VERSION ""

NS_ :

BS_:

BU_: ACM APIM APIM_CDC APIM_CIM APIM_CISM ARM DSP ESPM FCIMB GENERIC GWM HUD_ADV IPC MRCMB_RDAPM_HS3 RACM_RCIM TRM_ITRM TSTR WCM WCMB WCMC

BO_ 995 Personality_BCM_Data_HS3: 8 GWM
 SG_ FeatConfigBcmActl : 7|16@0+ (1,0) [0|65535] "Undefined"  APIM,APIM_CDC,APIM_CIM,APIM_CISM,IPC
 SG_ FeatNoBcm_No_Actl : 23|16@0+ (1,0) [0|65535] "Number"  APIM,APIM_CDC,APIM_CIM,APIM_CISM,IPC
 SG_ KeyAssocCmplt_B_Rq : 35|1@0+ (1,0) [0|1] "SED"  APIM_CDC,APIM_CIM,IPC
 SG_ FobAssocChime_B_Rq : 36|1@0+ (1,0) [0|1] "SED"  APIM_CDC,APIM_CIM,IPC
 SG_ PersIndexBcm_D_Actl : 39|3@0+ (1,0) [0|7] "SED"  APIM,APIM_CDC,APIM_CIM,APIM_CISM,IPC
 SG_ LightAmbColor_No_Actl : 47|8@0+ (1,0) [0|255] "Discrete"  ACM,APIM,APIM_CDC,APIM_CIM,APIM_CISM,RACM_RCIM
 SG_ LightAmbIntsty_No_Actl : 55|8@0+ (1,0) [0|255] "unitless"  ACM,APIM,APIM_CDC,APIM_CIM,APIM_CISM,RACM_RCIM

BO_ 996 Personality_HUD_Data: 8 HUD_ADV
 SG_ FeatConfigHudActl : 7|16@0+ (1,0) [0|65535] "Unitless"  APIM_CDC,APIM_CIM,APIM_CISM,IPC
 SG_ FeatNoHudActl : 23|16@0+ (1,0) [0|65535] "Unitless"  APIM_CDC,APIM_CIM,APIM_CISM,IPC
 SG_ PersIndexHud_D_Actl : 39|16@0+ (1,0) [0|65535] "unitless"  APIM_CDC,APIM_CIM,APIM_CISM,IPC

BO_ 997 Personality_CCM_Data_HS3: 8 GWM
 SG_ FeatConfigCcmActl : 7|16@0+ (1,0) [0|65535] "Undefined"  APIM,APIM_CDC,APIM_CIM,APIM_CISM,HUD_ADV,IPC
 SG_ FeatNoCcmActl : 23|16@0+ (1,0) [0|65535] "Number"  APIM,APIM_CDC,APIM_CIM,APIM_CISM,HUD_ADV,IPC
 SG_ PersTurnSglView_D_Stat : 36|2@0+ (1,0) [0|3] "SED"  APIM,APIM_CDC,APIM_CIM,APIM_CISM
 SG_ PersIndexCcm_D_Actl : 39|3@0+ (1,0) [0|7] "SED"  APIM,APIM_CDC,APIM_CIM,APIM_CISM,HUD_ADV,IPC

BO_ 998 Personality_SCCM_Data_HS3: 8 GWM
 SG_ FeatConfigSccmActl : 7|16@0+ (1,0) [0|65535] "Undefined"  APIM,APIM_CDC,APIM_CIM,APIM_CISM,IPC
 SG_ FeatNoSccmActl : 23|16@0+ (1,0) [0|65535] "Number"  APIM,APIM_CDC,APIM_CIM,APIM_CISM,IPC
 SG_ PersIndexSccm_D_Actl : 39|3@0+ (1,0) [0|7] "SED"  APIM,APIM_CDC,APIM_CIM,APIM_CISM,IPC

BO_ 999 Personality_HVAC_Data_HS3: 8 GWM
 SG_ FeatConfigFcimActl : 7|16@0+ (1,0) [0|65535] "Undefined"  APIM,APIM_CDC,APIM_CIM,APIM_CISM,IPC
 SG_ FeatNoFcimActl : 23|16@0+ (1,0) [0|65535] "Number"  APIM,APIM_CDC,APIM_CIM,APIM_CISM,IPC
 SG_ PersIndexFcim_D_Actl : 39|3@0+ (1,0) [0|7] "SED"  APIM,APIM_CDC,APIM_CIM,APIM_CISM,IPC

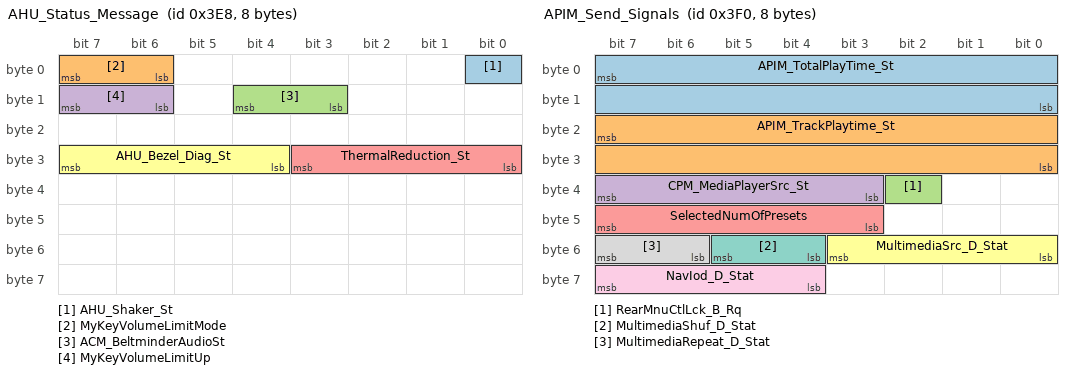
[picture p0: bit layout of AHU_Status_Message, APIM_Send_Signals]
BO_ 1000 AHU_Status_Message: 8 APIM_CIM
 SG_ AHU_Shaker_St : 0|1@0+ (1,0) [0|1] "SED"  APIM,APIM_CDC,GWM
 SG_ MyKeyVolumeLimitMode : 7|2@0+ (1,0) [0|3] "SED"  APIM,APIM_CDC
 SG_ ACM_BeltminderAudioSt : 12|2@0+ (1,0) [0|3] "SED"  APIM,APIM_CDC,IPC
 SG_ MyKeyVolumeLimitUp : 15|2@0+ (1,0) [0|3] "SED"  APIM,APIM_CDC
 SG_ ThermalReduction_St : 27|4@0+ (1,0) [0|15] "SED"  DSP
 SG_ AHU_Bezel_Diag_St : 31|4@0+ (1,0) [0|15] "SED"  APIM,APIM_CDC

BO_ 1001 Personality_SUMA_Data_HS3: 8 GWM
 SG_ FeatConfigSumaActl : 7|16@0+ (1,0) [0|65535] "unitless"  APIM,APIM_CDC,IPC
 SG_ FeatNoSumaActl : 23|16@0+ (1,0) [0|65535] "unitless"  APIM,APIM_CDC,IPC
 SG_ AirSuspMsgTxt_D_Rq2 : 36|2@0+ (1,0) [0|3] "SED"  APIM,APIM_CDC,APIM_CIM,IPC
 SG_ PersIndexSuma_D_Actl : 39|3@0+ (1,0) [0|7] "SED"  APIM,APIM_CDC,IPC

BO_ 1002 Personality_APIM_Data2: 8 APIM_CDC
 SG_ CntrStkKeycodeActl : 7|16@0+ (1,0) [0|65535] "Undefined"  GWM
 SG_ FeatConfigApimActl : 23|16@0+ (1,0) [0|65535] "Number"  GWM,IPC
 SG_ FeatNoApimActl : 39|16@0+ (1,0) [0|65535] "Number"  GWM,IPC
 SG_ CntrStk_D_RqRecall : 52|3@0+ (1,0) [0|7] "SED"  GWM
 SG_ CntrStk_D_RqAssoc : 55|3@0+ (1,0) [0|7] "SED"  GWM
 SG_ PersIndexApim_D_Actl : 63|3@0+ (1,0) [0|7] "SED"  GWM,IPC

BO_ 1004 Personality_BCM2_Data_HS3: 8 GWM
 SG_ RecallEvent_No_Cnt : 7|8@0+ (1,0) [0|255] "Counts"  ACM,APIM,APIM_CDC,APIM_CIM,APIM_CISM,DSP,HUD_ADV,IPC,RACM_RCIM
 SG_ PersNo_D_Actl : 10|3@0+ (1,0) [0|7] "SED"  ACM,APIM,APIM_CDC,APIM_CIM,APIM_CISM,DSP,IPC,RACM_RCIM
 SG_ Pers1Key_D_Stat : 12|2@0+ (1,0) [0|3] "SED"  APIM,APIM_CDC,APIM_CIM,APIM_CISM
 SG_ AssocConfirm_D_Actl : 15|3@0+ (1,0) [0|7] "SED"  APIM,APIM_CDC,APIM_CIM,APIM_CISM
 SG_ PersNoPos_D_Actl : 18|3@0+ (1,0) [0|7] "SED"  APIM,APIM_CDC,APIM_CIM,APIM_CISM,HUD_ADV,IPC
 SG_ PersSetupAccessCtrl : 19|1@0+ (1,0) [0|1] "SED"  APIM,APIM_CDC,APIM_CIM,APIM_CISM
 SG_ PersSetupRestr_D_Actl : 21|2@0+ (1,0) [0|3] "SED"  APIM,APIM_CDC,APIM_CIM,APIM_CISM
 SG_ PersConflict_D_Actl : 22|1@0+ (1,0) [0|1] "SED"  APIM,APIM_CDC,APIM_CIM,APIM_CISM
 SG_ PersSetup_No_Actl : 31|16@0+ (1,0) [0|65535] "Number"  APIM,APIM_CDC,APIM_CIM,APIM_CISM
 SG_ Pers3Key_D_Stat : 41|2@0+ (1,0) [0|3] "SED"  APIM,APIM_CDC,APIM_CIM,APIM_CISM
 SG_ Pers2Key_D_Stat : 43|2@0+ (1,0) [0|3] "SED"  APIM,APIM_CDC,APIM_CIM,APIM_CISM
 SG_ VehKeyActv_D_Stat : 47|4@0+ (1,0) [0|15] "SED"  APIM_CDC,APIM_CIM,APIM_CISM,IPC
 SG_ Pers4Key_D_Stat : 49|2@0+ (1,0) [0|3] "SED"  APIM,APIM_CDC,APIM_CIM,APIM_CISM
 SG_ EmPrflNo_D_Stat : 52|3@0+ (1,0) [0|7] "SED"  APIM,APIM_CDC,APIM_CIM,APIM_CISM
 SG_ EmPrflKeyAssoc_D_Stat : 55|3@0+ (1,0) [0|7] "SED"  APIM,APIM_CDC,APIM_CIM,APIM_CISM
 SG_ TailLghtLoadMde_D_Stat : 60|3@0+ (1,0) [0|7] "SED"  APIM,APIM_CDC,APIM_CIM,APIM_CISM
 SG_ PersRecallSrc_D_Actl : 63|3@0+ (1,0) [0|7] "SED" Vector__XXX

BO_ 1006 Personality_IPMB_Data_HS3: 8 GWM
 SG_ FeatConfigIpmbActl : 7|16@0+ (1,0) [0|65535] "Undefined"  ACM,APIM,APIM_CDC,APIM_CIM,APIM_CISM
 SG_ FeatNoIpmbActl : 23|16@0+ (1,0) [0|65535] "Number"  ACM,APIM,APIM_CDC,APIM_CIM,APIM_CISM
 SG_ PersIndexIpmb_D_Actl : 39|3@0+ (1,0) [0|7] "SED"  ACM,APIM,APIM_CDC,APIM_CIM,APIM_CISM

BO_ 1007 Personality_IPC_Data_3: 8 IPC
 SG_ FeatConfigIpc2Actl : 7|16@0+ (1,0) [0|65535] "unitless"  APIM,APIM_CISM
 SG_ FeatNoIpc2Actl : 23|16@0+ (1,0) [0|65535] "Number"  APIM,APIM_CISM
 SG_ PersIndexIpc2_D_Actl : 39|3@0+ (1,0) [0|7] "SED"  APIM,APIM_CISM

BO_ 1008 APIM_Send_Signals: 8 APIM_CDC
 SG_ APIM_TotalPlayTime_St : 7|16@0+ (1,-100) [-100|65434] "second"  GWM,IPC,RACM_RCIM
 SG_ APIM_TrackPlaytime_St : 23|16@0+ (1,-100) [-100|65434] "second"  GWM,IPC,RACM_RCIM
 SG_ RearMnuCtlLck_B_Rq : 34|1@0+ (1,0) [0|1] "Unitless"  RACM_RCIM
 SG_ CPM_MediaPlayerSrc_St : 39|5@0+ (1,0) [0|31] "SED"  GENERIC,GWM
 SG_ SelectedNumOfPresets : 47|5@0+ (1,0) [0|31] "SED"  ACM,GWM,IPC,RACM_RCIM
 SG_ MultimediaSrc_D_Stat : 51|4@0+ (1,0) [0|15] "SED"  GWM,RACM_RCIM
 SG_ MultimediaShuf_D_Stat : 53|2@0+ (1,0) [0|3] "SED"  GWM,RACM_RCIM
 SG_ MultimediaRepeat_D_Stat : 55|2@0+ (1,0) [0|3] "SED"  GWM,RACM_RCIM
 SG_ NavIod_D_Stat : 63|4@0+ (1,0) [0|15] "SED"  IPC

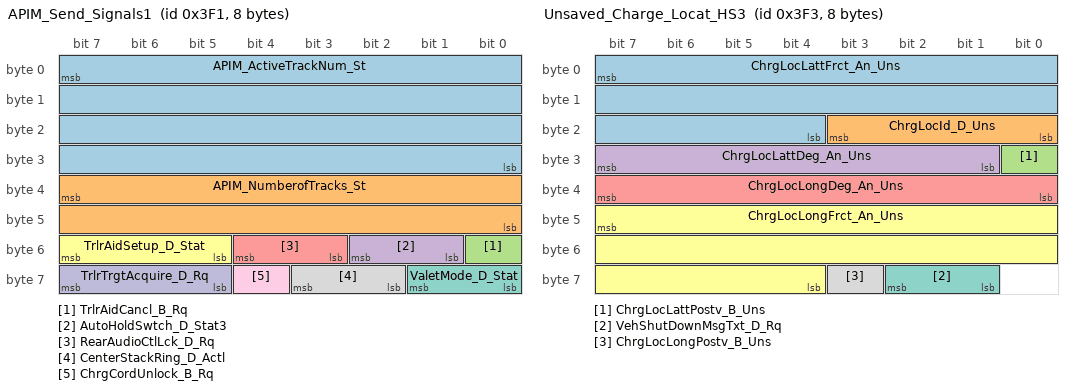
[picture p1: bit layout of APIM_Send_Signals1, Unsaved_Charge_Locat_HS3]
BO_ 1009 APIM_Send_Signals1: 8 APIM_CDC
 SG_ APIM_ActiveTrackNum_St : 7|32@0+ (1,0) [0|4294967295] "unitless"  GWM,HUD_ADV,IPC,RACM_RCIM
 SG_ APIM_NumberofTracks_St : 39|16@0+ (1,0) [0|65535] "unitless"  GWM,HUD_ADV,IPC,RACM_RCIM
 SG_ TrlrAidCancl_B_Rq : 48|1@0+ (1,0) [0|1] "SED"  GWM
 SG_ AutoHoldSwtch_D_Stat3 : 50|2@0+ (1,0) [0|3] "SED"  GWM
 SG_ RearAudioCtlLck_D_Rq : 52|2@0+ (1,0) [0|3] "SED"  GWM,RACM_RCIM
 SG_ TrlrAidSetup_D_Stat : 55|3@0+ (1,0) [0|7] "SED"  GWM,IPC
 SG_ ValetMode_D_Stat : 57|2@0+ (1,0) [0|3] "SED"  GWM
 SG_ CenterStackRing_D_Actl : 59|2@0+ (1,0) [0|3] "SED"  GWM
 SG_ ChrgCordUnlock_B_Rq : 60|1@0+ (1,0) [0|1] "SED"  GWM
 SG_ TrlrTrgtAcquire_D_Rq : 63|3@0+ (1,0) [0|7] "SED"  GWM

BO_ 1011 Unsaved_Charge_Locat_HS3: 8 GWM
 SG_ ChrgLocLattFrct_An_Uns : 7|20@0+ (1E-006,0) [0|1.048575] "degrees"  APIM,APIM_CDC,APIM_CIM,APIM_CISM
 SG_ ChrgLocId_D_Uns : 19|4@0+ (1,0) [0|15] "unitless"  APIM,APIM_CDC,APIM_CIM,APIM_CISM
 SG_ ChrgLocLattPostv_B_Uns : 24|1@0+ (1,0) [0|1] "SED"  APIM,APIM_CDC,APIM_CIM,APIM_CISM
 SG_ ChrgLocLattDeg_An_Uns : 31|7@0+ (1,0) [0|127] "unitless"  APIM,APIM_CDC,APIM_CIM,APIM_CISM
 SG_ ChrgLocLongDeg_An_Uns : 39|8@0+ (1,0) [0|255] "degrees"  APIM,APIM_CDC,APIM_CIM,APIM_CISM
 SG_ ChrgLocLongFrct_An_Uns : 47|20@0+ (1E-006,0) [0|1.048575] "degrees"  APIM,APIM_CDC,APIM_CIM,APIM_CISM
 SG_ VehShutDownMsgTxt_D_Rq : 58|2@0+ (1,0) [0|3] "SED"  APIM_CDC,IPC
 SG_ ChrgLocLongPostv_B_Uns : 59|1@0+ (1,0) [0|1] "SED"  APIM,APIM_CDC,APIM_CIM,APIM_CISM

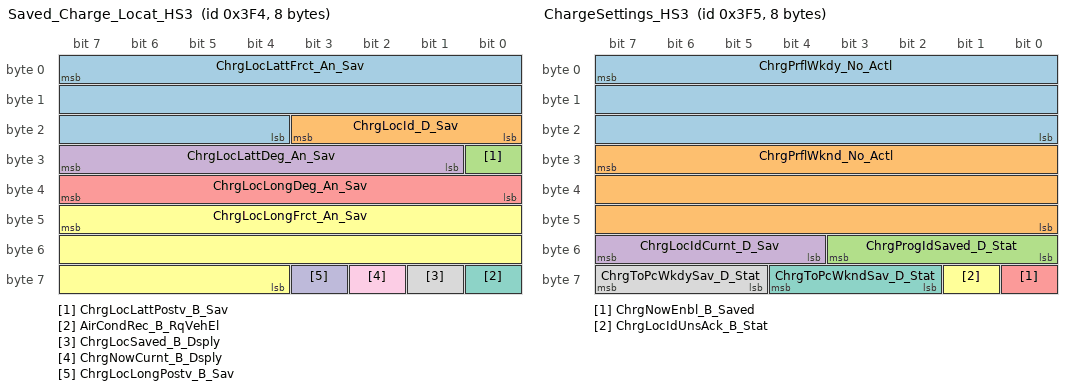
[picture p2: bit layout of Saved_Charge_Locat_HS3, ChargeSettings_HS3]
BO_ 1012 Saved_Charge_Locat_HS3: 8 GWM
 SG_ ChrgLocLattFrct_An_Sav : 7|20@0+ (1E-006,0) [0|1.048575] "degrees"  APIM,APIM_CDC,APIM_CIM,APIM_CISM
 SG_ ChrgLocId_D_Sav : 19|4@0+ (1,0) [0|15] "unitless"  APIM,APIM_CDC,APIM_CIM,APIM_CISM
 SG_ ChrgLocLattPostv_B_Sav : 24|1@0+ (1,0) [0|1] "SED"  APIM,APIM_CDC,APIM_CIM,APIM_CISM
 SG_ ChrgLocLattDeg_An_Sav : 31|7@0+ (1,0) [0|127] "unitless"  APIM,APIM_CDC,APIM_CIM,APIM_CISM
 SG_ ChrgLocLongDeg_An_Sav : 39|8@0+ (1,0) [0|255] "degrees"  APIM,APIM_CDC,APIM_CIM,APIM_CISM
 SG_ ChrgLocLongFrct_An_Sav : 47|20@0+ (1E-006,0) [0|1.048575] "degrees"  APIM,APIM_CDC,APIM_CIM,APIM_CISM
 SG_ AirCondRec_B_RqVehEl : 56|1@0+ (1,0) [0|1] "SED" Vector__XXX
 SG_ ChrgLocSaved_B_Dsply : 57|1@0+ (1,0) [0|1] "SED"  APIM,APIM_CDC,APIM_CIM,APIM_CISM
 SG_ ChrgNowCurnt_B_Dsply : 58|1@0+ (1,0) [0|1] "SED"  APIM,APIM_CDC,APIM_CIM,APIM_CISM,IPC
 SG_ ChrgLocLongPostv_B_Sav : 59|1@0+ (1,0) [0|1] "SED"  APIM,APIM_CDC,APIM_CIM,APIM_CISM

BO_ 1013 ChargeSettings_HS3: 8 GWM
 SG_ ChrgPrflWkdy_No_Actl : 7|24@0+ (1,0) [0|16777215] "unitless"  APIM,APIM_CDC,APIM_CIM,APIM_CISM
 SG_ ChrgPrflWknd_No_Actl : 31|24@0+ (1,0) [0|16777215] "unitless"  APIM,APIM_CDC,APIM_CIM,APIM_CISM
 SG_ ChrgProgIdSaved_D_Stat : 51|4@0+ (1,0) [0|15] "unitless"  APIM,APIM_CDC,APIM_CIM,APIM_CISM
 SG_ ChrgLocIdCurnt_D_Sav : 55|4@0+ (1,0) [0|15] "unitless"  APIM,APIM_CDC,APIM_CIM,APIM_CISM,IPC
 SG_ ChrgNowEnbl_B_Saved : 56|1@0+ (1,0) [0|1] "SED"  APIM,APIM_CDC,APIM_CIM,APIM_CISM
 SG_ ChrgLocIdUnsAck_B_Stat : 57|1@0+ (1,0) [0|1] "SED"  APIM,APIM_CDC,APIM_CIM,APIM_CISM
 SG_ ChrgToPcWkndSav_D_Stat : 60|3@0+ (1,0) [0|7] "SED"  APIM,APIM_CDC,APIM_CIM,APIM_CISM
 SG_ ChrgToPcWkdySav_D_Stat : 63|3@0+ (1,0) [0|7] "SED"  APIM,APIM_CDC,APIM_CIM,APIM_CISM

BO_ 1014 WCM_Send_Signals: 8 WCM
 SG_ WrlssAcsyChrgr_D_Stat : 7|3@0+ (1,0) [0|7] "SED"  APIM,APIM_CDC,APIM_CIM,APIM_CISM
 SG_ WrlssAcsyChrg_Pc_Actl : 15|7@0+ (1,0) [0|127] "percent"  APIM,APIM_CDC,APIM_CIM,APIM_CISM

BO_ 1015 Clmt_Button_Stat8_HS3: 8 GWM
 SG_ SelDrvMdeSwtch_D_Stat7 : 1|2@0+ (1,0) [0|3] "SED"  APIM,APIM_CDC
 SG_ E_Frt_Btn_Status_1st : 7|6@0+ (1,0) [0|63] "SED" Vector__XXX
 SG_ E_Frt_Btn_Status_2nd : 15|6@0+ (1,0) [0|63] "SED" Vector__XXX

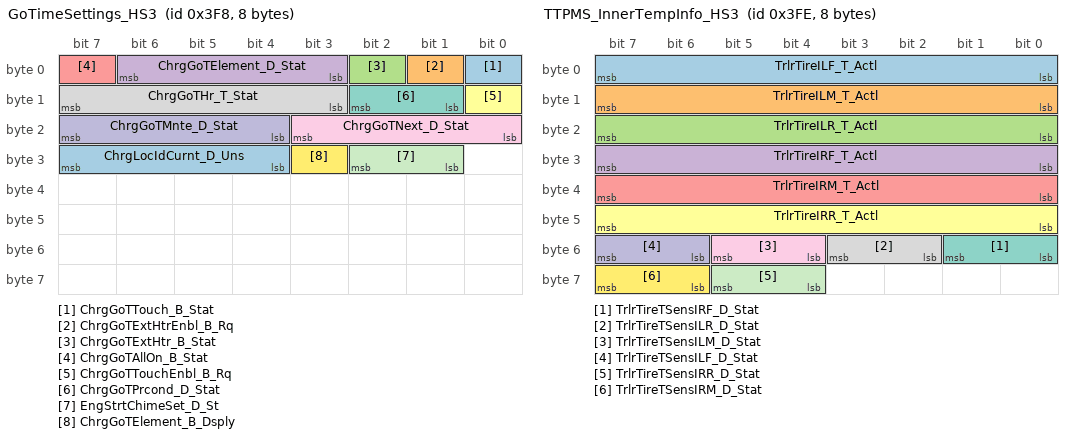
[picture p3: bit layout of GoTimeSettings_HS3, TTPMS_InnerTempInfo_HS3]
BO_ 1016 GoTimeSettings_HS3: 8 GWM
 SG_ ChrgGoTTouch_B_Stat : 0|1@0+ (1,0) [0|1] "SED"  APIM,APIM_CDC,APIM_CIM,APIM_CISM
 SG_ ChrgGoTExtHtrEnbl_B_Rq : 1|1@0+ (1,0) [0|1] "SED" Vector__XXX
 SG_ ChrgGoTExtHtr_B_Stat : 2|1@0+ (1,0) [0|1] "SED"  APIM,APIM_CDC,APIM_CIM,APIM_CISM
 SG_ ChrgGoTElement_D_Stat : 6|4@0+ (1,0) [0|15] "unitless"  APIM,APIM_CDC,APIM_CIM,APIM_CISM
 SG_ ChrgGoTAllOn_B_Stat : 7|1@0+ (1,0) [0|1] "SED"  APIM,APIM_CDC,APIM_CIM,APIM_CISM
 SG_ ChrgGoTTouchEnbl_B_Rq : 8|1@0+ (1,0) [0|1] "SED"  APIM,APIM_CDC,APIM_CIM,APIM_CISM
 SG_ ChrgGoTPrcond_D_Stat : 10|2@0+ (1,0) [0|3] "SED"  APIM,APIM_CDC,APIM_CIM,APIM_CISM
 SG_ ChrgGoTHr_T_Stat : 15|5@0+ (1,0) [0|31] "hour"  APIM,APIM_CDC,APIM_CIM,APIM_CISM
 SG_ ChrgGoTNext_D_Stat : 19|4@0+ (1,0) [0|15] "unitless"  APIM,APIM_CDC,APIM_CIM,APIM_CISM
 SG_ ChrgGoTMnte_D_Stat : 23|4@0+ (1,0) [0|15] "SED"  APIM,APIM_CDC,APIM_CIM,APIM_CISM
 SG_ EngStrtChimeSet_D_St : 26|2@0+ (1,0) [0|3] "SED"  APIM
 SG_ ChrgGoTElement_B_Dsply : 27|1@0+ (1,0) [0|1] "SED"  APIM,APIM_CDC,APIM_CIM,APIM_CISM
 SG_ ChrgLocIdCurnt_D_Uns : 31|4@0+ (1,0) [0|15] "unitless"  APIM,APIM_CDC,APIM_CIM,APIM_CISM

BO_ 1018 TTPMS_InnerLeftTrlTire_HS3: 8 GWM
 SG_ TrlrTireILF_P_Actl : 7|16@0+ (1,0) [0|65535] "kilopascal"  APIM,APIM_CDC,APIM_CIM,APIM_CISM,IPC
 SG_ TrlrTireILM_P_Actl : 23|16@0+ (1,0) [0|65535] "kilopascal"  APIM,APIM_CDC,APIM_CIM,APIM_CISM,IPC
 SG_ TrlrTireILR_P_Actl : 39|16@0+ (1,0) [0|65535] "kilopascal"  APIM,APIM_CDC,APIM_CIM,APIM_CISM,IPC
 SG_ TrlrTireSensILM_D_Stat : 51|4@0+ (1,0) [0|15] "SED"  APIM,APIM_CDC,APIM_CIM,APIM_CISM,IPC
 SG_ TrlrTireSensILF_D_Stat : 55|4@0+ (1,0) [0|15] "SED"  APIM,APIM_CDC,APIM_CIM,APIM_CISM,IPC
 SG_ TrlrTireSensILR_D_Stat : 63|4@0+ (1,0) [0|15] "SED"  APIM,APIM_CDC,APIM_CIM,APIM_CISM,IPC

BO_ 1019 Personality_IPC_Data_2: 8 APIM_CDC
 SG_ FeatConfigIpcActl : 7|16@0+ (1,0) [0|65535] "unitless"  APIM,APIM_CISM,GWM
 SG_ FeatNoIpcActl : 23|16@0+ (1,0) [0|65535] "Number"  APIM,APIM_CISM,GWM
 SG_ PersIndexIpc_D_Actl : 34|3@0+ (1,0) [0|7] "SED"  APIM,APIM_CISM,GWM

BO_ 1020 Personality_APIM_Data4: 8 APIM_CDC
 SG_ CtrStkFeat2ConfigActl : 7|16@0+ (1,0) [0|65535] "Undefined"  HUD_ADV,IPC
 SG_ CtrStkFeat2NoActl : 23|16@0+ (1,0) [0|65535] "Undefined"  HUD_ADV,IPC
 SG_ CtrStkDsplyOp2_D_Rq : 36|3@0+ (1,0) [0|7] "SED"  HUD_ADV,IPC
 SG_ CtrStkPersIndex2_D_Actl : 39|3@0+ (1,0) [0|7] "SED"  HUD_ADV,IPC

BO_ 1021 TTPMS_InnerRghtTrlTire_HS3: 8 GWM
 SG_ TrlrTireIRF_P_Actl : 7|16@0+ (1,0) [0|65535] "kilopascal"  APIM,APIM_CDC,APIM_CIM,APIM_CISM,IPC
 SG_ TrlrTireIRM_P_Actl : 23|16@0+ (1,0) [0|65535] "kilopascal"  APIM,APIM_CDC,APIM_CIM,APIM_CISM,IPC
 SG_ TrlrTireIRR_P_Actl : 39|16@0+ (1,0) [0|65535] "kilopascal"  APIM,APIM_CDC,APIM_CIM,APIM_CISM,IPC
 SG_ TrlrTireSensIRM_D_Stat : 51|4@0+ (1,0) [0|15] "SED"  APIM,APIM_CDC,APIM_CIM,APIM_CISM,IPC
 SG_ TrlrTireSensIRF_D_Stat : 55|4@0+ (1,0) [0|15] "SED"  APIM,APIM_CDC,APIM_CIM,APIM_CISM,IPC
 SG_ TrlrTireSensIRR_D_Stat : 63|4@0+ (1,0) [0|15] "SED"  APIM,APIM_CDC,APIM_CIM,APIM_CISM,IPC

BO_ 1022 TTPMS_InnerTempInfo_HS3: 8 GWM
 SG_ TrlrTireILF_T_Actl : 7|8@0+ (1,-60) [-60|195] "degC"  APIM,APIM_CDC,APIM_CIM,APIM_CISM,IPC
 SG_ TrlrTireILM_T_Actl : 15|8@0+ (1,-60) [-60|195] "degC"  APIM,APIM_CDC,APIM_CIM,APIM_CISM,IPC
 SG_ TrlrTireILR_T_Actl : 23|8@0+ (1,-60) [-60|195] "degC"  APIM,APIM_CDC,APIM_CIM,APIM_CISM,IPC
 SG_ TrlrTireIRF_T_Actl : 31|8@0+ (1,-60) [-60|195] "degC"  APIM,APIM_CDC,APIM_CIM,APIM_CISM,IPC
 SG_ TrlrTireIRM_T_Actl : 39|8@0+ (1,-60) [-60|195] "degC"  APIM,APIM_CDC,APIM_CIM,APIM_CISM,IPC
 SG_ TrlrTireIRR_T_Actl : 47|8@0+ (1,-60) [-60|195] "degC"  APIM,APIM_CDC,APIM_CIM,APIM_CISM,IPC
 SG_ TrlrTireTSensIRF_D_Stat : 49|2@0+ (1,0) [0|3] "SED"  APIM,APIM_CDC,APIM_CIM,APIM_CISM,IPC
 SG_ TrlrTireTSensILR_D_Stat : 51|2@0+ (1,0) [0|3] "SED"  APIM,APIM_CDC,APIM_CIM,APIM_CISM,IPC
 SG_ TrlrTireTSensILM_D_Stat : 53|2@0+ (1,0) [0|3] "SED"  APIM,APIM_CDC,APIM_CIM,APIM_CISM,IPC
 SG_ TrlrTireTSensILF_D_Stat : 55|2@0+ (1,0) [0|3] "SED"  APIM,APIM_CDC,APIM_CIM,APIM_CISM,IPC
 SG_ TrlrTireTSensIRR_D_Stat : 61|2@0+ (1,0) [0|3] "SED"  APIM,APIM_CDC,APIM_CIM,APIM_CISM,IPC
 SG_ TrlrTireTSensIRM_D_Stat : 63|2@0+ (1,0) [0|3] "SED"  APIM,APIM_CDC,APIM_CIM,APIM_CISM,IPC

BO_ 1034 GGCC_Config_Mgmt_ID_1_HS3: 8 GWM
 SG_ VehicleGGCCData : 7|64@0+ (1,0) [0|1.84467440737096E+019] "Unitless"  ACM,APIM,APIM_CDC,APIM_CIM,APIM_CISM,HUD_ADV,IPC,RACM_RCIM,TRM_ITRM

BO_ 1036 PedestrianAlert_Data_HS3: 8 GWM
 SG_ OnbSnd_D_Stat : 6|2@0+ (1,0) [0|3] "SED"  APIM
 SG_ PdstrnAlrt_B_Falt : 7|1@0+ (1,0) [0|1] "SED"  APIM_CDC,APIM_CIM,IPC

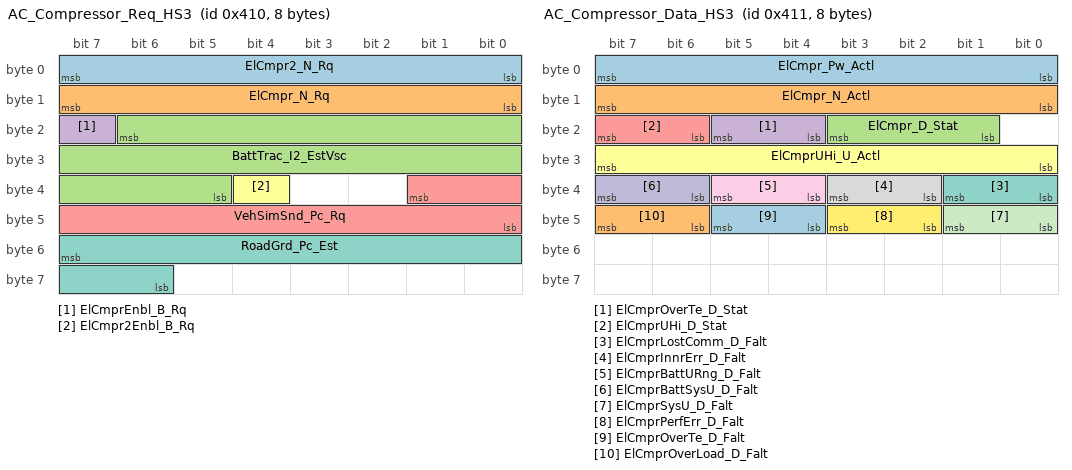
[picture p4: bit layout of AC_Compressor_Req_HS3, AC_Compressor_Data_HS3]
BO_ 1040 AC_Compressor_Req_HS3: 8 GWM
 SG_ ElCmpr2_N_Rq : 7|8@0+ (50,0) [0|12750] "RPM" Vector__XXX
 SG_ ElCmpr_N_Rq : 15|8@0+ (50,0) [0|12750] "RPM" Vector__XXX
 SG_ BattTrac_I2_EstVsc : 22|18@0+ (0.05,-6553.52) [-6553.52|6553.63] "ampere" Vector__XXX
 SG_ ElCmprEnbl_B_Rq : 23|1@0+ (1,0) [0|1] "SED" Vector__XXX
 SG_ VehSimSnd_Pc_Rq : 33|10@0+ (0.2,-102.2) [-102.2|102.4] "percent"  ACM,APIM_CDC,APIM_CIM,APIM_CISM
 SG_ ElCmpr2Enbl_B_Rq : 36|1@0+ (1,0) [0|1] "SED" Vector__XXX
 SG_ RoadGrd_Pc_Est : 55|10@0+ (0.2,-102) [-102|102.6] "percent" Vector__XXX

BO_ 1041 AC_Compressor_Data_HS3: 8 GWM
 SG_ ElCmpr_Pw_Actl : 7|8@0+ (40,0) [0|10200] "watts" Vector__XXX
 SG_ ElCmpr_N_Actl : 15|8@0+ (50,0) [0|12750] "RPM"  WCM,WCMB,WCMC
 SG_ ElCmpr_D_Stat : 19|3@0+ (1,0) [0|7] "SED" Vector__XXX
 SG_ ElCmprOverTe_D_Stat : 21|2@0+ (1,0) [0|3] "SED" Vector__XXX
 SG_ ElCmprUHi_D_Stat : 23|2@0+ (1,0) [0|3] "SED" Vector__XXX
 SG_ ElCmprUHi_U_Actl : 31|8@0+ (2,0) [0|510] "volt" Vector__XXX
 SG_ ElCmprLostComm_D_Falt : 33|2@0+ (1,0) [0|3] "SED" Vector__XXX
 SG_ ElCmprInnrErr_D_Falt : 35|2@0+ (1,0) [0|3] "SED" Vector__XXX
 SG_ ElCmprBattURng_D_Falt : 37|2@0+ (1,0) [0|3] "SED" Vector__XXX
 SG_ ElCmprBattSysU_D_Falt : 39|2@0+ (1,0) [0|3] "SED" Vector__XXX
 SG_ ElCmprSysU_D_Falt : 41|2@0+ (1,0) [0|3] "SED" Vector__XXX
 SG_ ElCmprPerfErr_D_Falt : 43|2@0+ (1,0) [0|3] "SED" Vector__XXX
 SG_ ElCmprOverTe_D_Falt : 45|2@0+ (1,0) [0|3] "SED" Vector__XXX
 SG_ ElCmprOverLoad_D_Falt : 47|2@0+ (1,0) [0|3] "SED" Vector__XXX

BO_ 1042 TrailerBrakeData_HS3: 8 GWM
 SG_ TrlrBrk_Pc_Rq : 14|7@0+ (1,0) [0|127] "percent"  IPC,TRM_ITRM
 SG_ VehPtch_An_Dsply : 23|7@0+ (1,-64) [-64|63] "degrees"  APIM,APIM_CDC,APIM_CIM,APIM_CISM,HUD_ADV,IPC
 SG_ VehRol_An_Dsply : 31|7@0+ (1,-64) [-64|63] "degrees"  APIM,APIM_CDC,APIM_CIM,APIM_CISM,HUD_ADV,IPC
 SG_ RearDiffLck_Tq_RqMn : 39|12@0+ (4,0) [0|16380] "Nm" Vector__XXX

BO_ 1043 ABS_BrkData_HS3: 8 GWM
 SG_ OrtaSwtchLamp_B_Rq : 0|1@0+ (1,0) [0|1] "SED"  APIM,APIM_CDC,APIM_CIM,APIM_CISM
 SG_ OrtaMsgTxt_D_Rq : 4|4@0+ (1,0) [0|15] "SED"  APIM,APIM_CDC,APIM_CIM,APIM_CISM,HUD_ADV,IPC
 SG_ OrtaMde_D_Ind : 7|3@0+ (1,0) [0|7] "SED"  APIM,APIM_CDC,APIM_CIM,APIM_CISM,HUD_ADV,IPC
 SG_ IndvMdeSel_D_Stat : 9|2@0+ (1,0) [0|3] "SED"  APIM_CDC,APIM_CIM,IPC
 SG_ TrailOnePdlMsgTxt_D_Rq : 12|3@0+ (1,0) [0|7] "SED"  APIM_CDC,APIM_CIM,APIM_CISM,IPC
 SG_ TrailOnePdlMde_D_Ind : 15|3@0+ (1,0) [0|7] "SED"  APIM_CDC,APIM_CIM,APIM_CISM,HUD_ADV,IPC
 SG_ IndvMdeSel_No_Rq : 19|4@0+ (1,0) [0|15] "unitless"  APIM_CDC,APIM_CIM,IPC
 SG_ IndvMdeMsgTxt_D_Rq : 23|4@0+ (1,0) [0|15] "SED"  APIM_CDC,APIM_CIM,IPC
 SG_ IndvMdeSusp_No_Stat : 27|4@0+ (1,0) [0|15] "unitless"  APIM_CDC,APIM_CIM,IPC
 SG_ IndvMdeSte_No_Stat : 31|4@0+ (1,0) [0|15] "unitless"  APIM_CDC,APIM_CIM,IPC
 SG_ PrkBrkPerfActv_B_Stat : 32|1@0+ (1,0) [0|1] "SED" Vector__XXX
 SG_ PrkBrkPerfMde_D_Stat : 34|2@0+ (1,0) [0|3] "SED"  APIM,APIM_CDC,APIM_CIM,APIM_CISM,IPC
 SG_ IndvMde5_B_Avail : 35|1@0+ (1,0) [0|1] "SED"  APIM_CDC,APIM_CIM,IPC
 SG_ IndvMde4_B_Avail : 36|1@0+ (1,0) [0|1] "SED"  APIM_CDC,APIM_CIM,IPC
 SG_ IndvMde3_B_Avail : 37|1@0+ (1,0) [0|1] "SED"  APIM_CDC,APIM_CIM,IPC
 SG_ IndvMde2_B_Avail : 38|1@0+ (1,0) [0|1] "SED"  APIM_CDC,APIM_CIM,IPC
 SG_ IndvMde1_B_Avail : 39|1@0+ (1,0) [0|1] "SED"  APIM_CDC,APIM_CIM,IPC
 SG_ WhlSpareMsgTxt_D_Rq : 41|2@0+ (1,0) [0|3] "SED"  APIM_CISM
 SG_ PrkBrkApplCpblty_B_Stat : 42|1@0+ (1,0) [0|1] "SED" Vector__XXX
 SG_ SelDrvMdeHmi02_D_Rq : 47|5@0+ (1,0) [0|31] "SED"  APIM,APIM_CDC,APIM_CIM,APIM_CISM,HUD_ADV,IPC
 SG_ WhlSpareDetct_D_Dsply : 50|3@0+ (1,0) [0|7] "SED"  APIM_CISM
 SG_ SelDrvMdeHmi04_D_Rq : 55|5@0+ (1,0) [0|31] "SED"  ACM,APIM_CDC,APIM_CIM,APIM_CISM
 SG_ PrkBrkPerfMsgTxt_D_Rq : 63|5@0+ (1,0) [0|31] "SED"  APIM,APIM_CDC,APIM_CIM,APIM_CISM,IPC

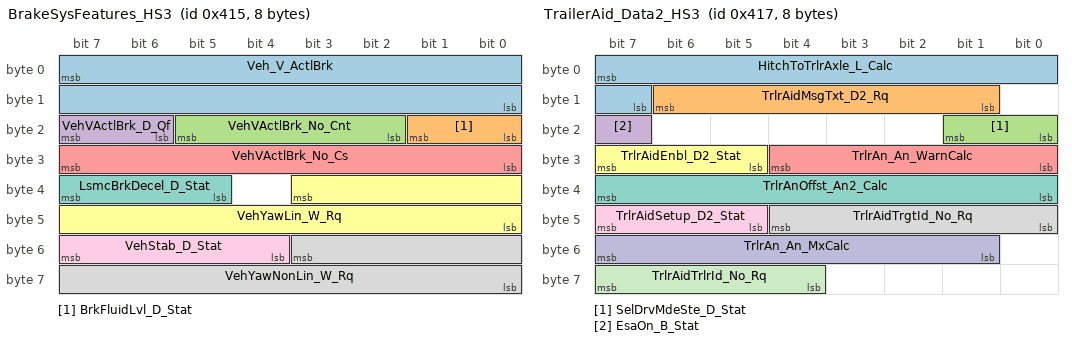
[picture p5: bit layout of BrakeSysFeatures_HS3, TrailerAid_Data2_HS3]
BO_ 1045 BrakeSysFeatures_HS3: 8 GWM
 SG_ Veh_V_ActlBrk : 7|16@0+ (0.01,0) [0|655.35] "kph"  TRM_ITRM
 SG_ BrkFluidLvl_D_Stat : 17|2@0+ (1,0) [0|3] "SED"  APIM_CDC,APIM_CIM
 SG_ VehVActlBrk_No_Cnt : 21|4@0+ (1,0) [0|15] "unitless"  TRM_ITRM
 SG_ VehVActlBrk_D_Qf : 23|2@0+ (1,0) [0|3] "SED"  TRM_ITRM
 SG_ VehVActlBrk_No_Cs : 31|8@0+ (1,0) [0|255] "unitless"  TRM_ITRM
 SG_ VehYawLin_W_Rq : 35|12@0+ (0.03663,-75) [-75|74.99985] "deg/s" Vector__XXX
 SG_ LsmcBrkDecel_D_Stat : 39|3@0+ (1,0) [0|7] "SED" Vector__XXX
 SG_ VehYawNonLin_W_Rq : 51|12@0+ (0.03663,-75) [-75|74.99985] "deg/s" Vector__XXX
 SG_ VehStab_D_Stat : 55|4@0+ (1,0) [0|15] "SED" Vector__XXX

BO_ 1046 BrakeSysFeatures_2_HS3: 8 GWM
 SG_ BpedMove_No_Cnt : 3|4@0+ (1,0) [0|15] "unitless"  GENERIC
 SG_ StabCtlBrk_B_Avail : 4|1@0+ (1,0) [0|1] "SED"  IPC
 SG_ Abs_B_Falt : 5|1@0+ (1,0) [0|1] "SED"  IPC,TRM_ITRM
 SG_ BpedMove_D_Actl : 7|2@0+ (1,0) [0|3] "SED" Vector__XXX
 SG_ DrvHdcMsg_D_Rq : 10|3@0+ (1,0) [0|7] "SED"  APIM_CDC,APIM_CIM,IPC
 SG_ DrvHdcLampInfo_D_Rq : 12|2@0+ (1,0) [0|3] "SED"  APIM,APIM_CDC,APIM_CIM,APIM_CISM,IPC
 SG_ BrkLamp_B_Rq : 13|1@0+ (1,0) [0|1] "SED"  APIM_CDC,APIM_CIM,IPC
 SG_ ChimeBrk_B_Rq : 14|1@0+ (1,0) [0|1] "SED"  APIM_CDC,APIM_CIM,IPC
 SG_ TCMode : 15|1@0+ (1,0) [0|1] "SED"  APIM,APIM_CDC,APIM_CIM,APIM_CISM,IPC
 SG_ BpedDiffLckTq_No_Cs : 23|8@0+ (1,0) [0|255] "unitless"  GENERIC
 SG_ BrkPrkBrkDynmc_B_Actl : 24|1@0+ (1,0) [0|1] "SED"  IPC
 SG_ TRLR_SWAY_EVNT_IN_PROG : 25|1@0+ (1,0) [0|1] "SED"  APIM,APIM_CDC,APIM_CIM,APIM_CISM,IPC
 SG_ TRLR_SWAY_CONFIG_STAT : 26|1@0+ (1,0) [0|1] "SED"  APIM,APIM_CDC,APIM_CIM,APIM_CISM,IPC
 SG_ BrkBstrVac_B_Rq : 27|1@0+ (1,0) [0|1] "Discrete" Vector__XXX
 SG_ ReserveTracCtlPtActv : 28|1@0+ (1,0) [0|1] "SED" Vector__XXX
 SG_ HdcMde_D_Actl : 31|3@0+ (1,0) [0|7] "SED"  APIM_CDC,APIM_CIM
 SG_ HsaMde_D_Mem : 33|2@0+ (1,0) [0|3] "SED"  APIM,APIM_CDC,APIM_CIM,APIM_CISM,IPC
 SG_ DrvHdcWarnInfo_D_Rq : 35|2@0+ (1,0) [0|3] "SED"  APIM_CDC,APIM_CIM,IPC
 SG_ PrkBrkDynmc_D_Allw : 39|2@0+ (1,0) [0|3] "SED"  IPC
 SG_ RearDiffElckrOpen_B_Rq : 40|1@0+ (1,0) [0|1] "SED"  GENERIC
 SG_ DrvSlipCtlLamp_D_Rq : 42|2@0+ (1,0) [0|3] "SED"  APIM_CDC,APIM_CIM,APIM_CISM,IPC
 SG_ DrvSlipCtlMde_D_Ind : 44|2@0+ (1,0) [0|3] "SED"  APIM_CDC,APIM_CIM,IPC
 SG_ HILL_DESC_MC : 47|3@0+ (1,0) [0|7] "SED"  APIM,APIM_CDC,APIM_CIM,APIM_CISM,IPC
 SG_ RearDiffLck_Tq2_RqMx : 51|12@0+ (4,0) [0|16380] "Nm"  GENERIC
 SG_ DrvAntiLckLamp_D_Rq : 55|2@0+ (1,0) [0|3] "SED"  APIM_CDC,APIM_CIM,APIM_CISM,IPC

BO_ 1047 TrailerAid_Data2_HS3: 8 GWM
 SG_ HitchToTrlrAxle_L_Calc : 7|9@0+ (0.0254,0) [0|12.9794] "meter" Vector__XXX
 SG_ TrlrAidMsgTxt_D2_Rq : 14|6@0+ (1,0) [0|63] "SED"  APIM,APIM_CDC,APIM_CIM,APIM_CISM,IPC,TRM_ITRM
 SG_ SelDrvMdeSte_D_Stat : 17|2@0+ (1,0) [0|3] "SED" Vector__XXX
 SG_ EsaOn_B_Stat : 23|1@0+ (1,0) [0|1] "SED"  APIM_CDC,APIM_CIM,IPC
 SG_ TrlrAn_An_WarnCalc : 28|5@0+ (1,0) [0|31] "degrees" Vector__XXX
 SG_ TrlrAidEnbl_D2_Stat : 31|3@0+ (1,0) [0|7] "SED"  APIM,APIM_CDC,APIM_CIM,APIM_CISM,IPC,TRM_ITRM
 SG_ TrlrAnOffst_An2_Calc : 39|8@0+ (0.5,-64) [-64|63.5] "degrees" Vector__XXX
 SG_ TrlrAidTrgtId_No_Rq : 44|5@0+ (1,0) [0|31] "unitless" Vector__XXX
 SG_ TrlrAidSetup_D2_Stat : 47|3@0+ (1,0) [0|7] "SED"  APIM,APIM_CDC
 SG_ TrlrAn_An_MxCalc : 55|7@0+ (1,0) [0|127] "degrees" Vector__XXX
 SG_ TrlrAidTrlrId_No_Rq : 63|4@0+ (1,0) [0|15] "unitless"  APIM,APIM_CDC,APIM_CIM,APIM_CISM,IPC

BO_ 1049 APIMSDMsignals: 8 APIM_CDC
 SG_ SelDrvMdePage_B_Stat : 0|1@0+ (1,0) [0|1] "SED"  GWM
 SG_ SelDrvMdeCnfm_D_Stat2 : 2|2@0+ (1,0) [0|3] "SED"  GWM
 SG_ SelDrvMde_D_RqDrv : 7|5@0+ (1,0) [0|31] "SED"  GWM
 SG_ RearDiffLck_D_RqDrv3 : 9|2@0+ (1,0) [0|3] "SED"  GWM
 SG_ FrontDiffLck_D_RqDrv3 : 11|2@0+ (1,0) [0|3] "SED"  GWM
 SG_ CamraFrnt_B_RqMnu : 12|1@0+ (1,0) [0|1] "SED"  GWM
 SG_ TurnAsstSwtch_D_Stat : 14|2@0+ (1,0) [0|3] "SED"  GWM
 SG_ SelDrvMdeTxtRst_B_Rq2 : 15|1@0+ (1,0) [0|1] "SED"  GWM
 SG_ DcacAllZoneBttn_B_Stat : 16|1@0+ (1,0) [0|1] "SED"  GWM
 SG_ DcacChime_D_Rq : 18|2@0+ (1,0) [0|3] "SED"  GWM,IPC
 SG_ PersTurnSglView_D_RqMnu : 20|2@0+ (1,0) [0|3] "SED"  GWM
 SG_ TrailCtlSwtch_B_Stat4 : 21|1@0+ (1,0) [0|1] "SED"  GWM
 SG_ StabBarCnncButtn_D_Sta3 : 23|2@0+ (1,0) [0|3] "SED"  GWM
 SG_ TrlrRngId_No_RqReset : 27|4@0+ (1,0) [0|15] "unitless"  GWM
 SG_ TrlrId_No_ActlMnu : 31|4@0+ (1,0) [0|15] "unitless"  GWM
 SG_ LnchCtl_D_Rq2 : 33|2@0+ (1,0) [0|3] "SED"  GWM
 SG_ DcacZone3PwBttn_B_Stat : 34|1@0+ (1,0) [0|1] "SED"  GWM
 SG_ DcacZone2PwBttn_B_Stat : 35|1@0+ (1,0) [0|1] "SED"  GWM
 SG_ DcacPwResetBtn2_B_Stat : 36|1@0+ (1,0) [0|1] "SED"  GWM
 SG_ DcacPwOffButtn2_B_Stat : 37|1@0+ (1,0) [0|1] "SED"  GWM
 SG_ DcacPwHiButtn2_B_Stat : 38|1@0+ (1,0) [0|1] "SED"  GWM
 SG_ DcacGfciTestBtn2_B_Stat : 39|1@0+ (1,0) [0|1] "SED"  GWM
 SG_ LnchCtl_N_Rq2 : 47|8@0+ (50,0) [0|12750] "rpm"  GWM,IPC
 SG_ Chrgr_Pw_EstMx : 55|9@0+ (2,0) [0|1022] "kilowatt"  GWM
 SG_ Fba_D_Rq : 57|2@0+ (1,0) [0|3] "SED"  GWM
 SG_ ExtLghtAnmtn_D_Rq : 61|4@0+ (1,0) [0|15] "SED"  GWM
 SG_ DrvSlipCtlMde_B_Rq6 : 62|1@0+ (1,0) [0|1] "SED"  GWM

BO_ 1050 Climate_Control_Data_HS3: 8 GWM
 SG_ Outside_Air_Temp_Stat : 7|8@0+ (0.5,-40) [-40|87.5] "degC"  APIM,APIM_CDC,APIM_CIM,APIM_CISM,HUD_ADV,IPC,WCM,WCMB,WCMC
 SG_ CamraFrntBttn_D_Stat : 8|1@0+ (1,0) [0|1] "SED" Vector__XXX
 SG_ DrvSlipCtlMde_B_Rq : 9|1@0+ (1,0) [0|1] "SED" Vector__XXX
 SG_ SteWhlHeat_D_Rq : 13|4@0+ (1,0) [0|15] "SED" Vector__XXX
 SG_ MirrorHeatOn_B_Rq : 14|1@0+ (1,0) [0|1] "SED" Vector__XXX
 SG_ Remote_Start_QuietMode : 15|1@0+ (1,0) [0|1] "SED" Vector__XXX
 SG_ TrailCtlSwtch_B_Stat : 16|1@0+ (1,0) [0|1] "SED" Vector__XXX
 SG_ EcoInhbt_B_RqHvac : 17|1@0+ (1,0) [0|1] "SED" Vector__XXX
 SG_ PrkAidSwtch_D_RqDrv : 18|1@0+ (1,0) [0|1] "SED" Vector__XXX
 SG_ AutoHoldSwtch_D_Stat : 20|2@0+ (1,0) [0|3] "SED" Vector__XXX
 SG_ GlvBoxRleas_No_Actl : 23|3@0+ (1,0) [0|7] "unitless" Vector__XXX
 SG_ LpdbDfrstRearOn_B_Rq : 24|1@0+ (1,0) [0|1] "SED" Vector__XXX
 SG_ LpdbDfrstFrOn_B_Rq : 25|1@0+ (1,0) [0|1] "SED" Vector__XXX
 SG_ LpdbDfrstFlOn_B_Rq : 26|1@0+ (1,0) [0|1] "SED" Vector__XXX
 SG_ LpdbAuxBlwr_B_Rq : 27|1@0+ (1,0) [0|1] "SED" Vector__XXX
 SG_ PrkAidSwtch_No_Cnt : 31|4@0+ (1,0) [0|15] "Unitless" Vector__XXX
 SG_ HtrCoreRearSov_D_Stat : 34|3@0+ (1,0) [0|7] "SED" Vector__XXX
 SG_ CamraRearBttn_D_Stat : 35|1@0+ (1,0) [0|1] "SED"  APIM,APIM_CDC,APIM_CIM,APIM_CISM
 SG_ LpdbPtc3_B_Rq : 36|1@0+ (1,0) [0|1] "SED" Vector__XXX
 SG_ LpdbPtc2_B_Rq : 37|1@0+ (1,0) [0|1] "SED" Vector__XXX
 SG_ LpdbPtc1_B_Rq : 38|1@0+ (1,0) [0|1] "SED" Vector__XXX
 SG_ LpdbHeatWiprPrk_B_Rq : 39|1@0+ (1,0) [0|1] "SED" Vector__XXX
 SG_ CabnAmb_Te2_Actl : 47|8@0+ (0.5,-42) [-42|85] "degC" Vector__XXX
 SG_ RearDiffLck_D_RqDrv4 : 55|2@0+ (1,0) [0|3] "SED" Vector__XXX
 SG_ CabnThrml_Te_Actl : 63|7@0+ (1,-40) [-40|87] "degC" Vector__XXX

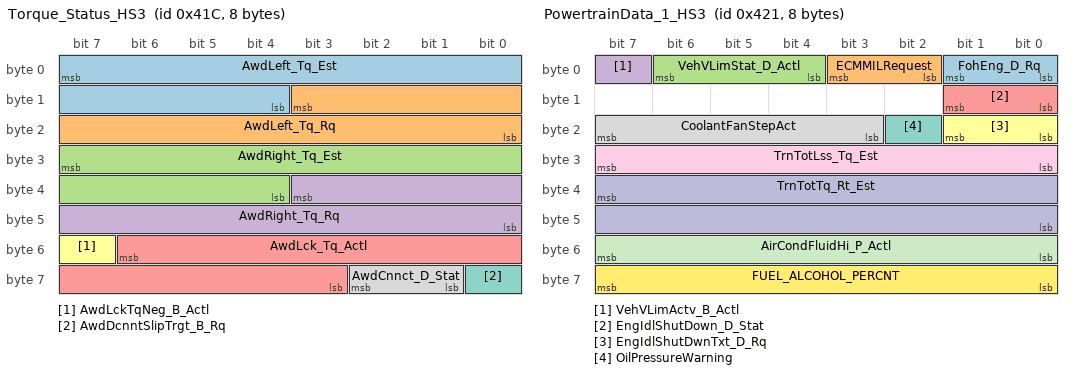
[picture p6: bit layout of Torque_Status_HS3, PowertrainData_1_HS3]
BO_ 1052 Torque_Status_HS3: 8 GWM
 SG_ AwdLeft_Tq_Est : 7|12@0+ (1,0) [0|4095] "Nm" Vector__XXX
 SG_ AwdLeft_Tq_Rq : 11|12@0+ (1,0) [0|4095] "Nm" Vector__XXX
 SG_ AwdRight_Tq_Est : 31|12@0+ (1,0) [0|4095] "Nm" Vector__XXX
 SG_ AwdRight_Tq_Rq : 35|12@0+ (1,0) [0|4095] "Nm" Vector__XXX
 SG_ AwdLck_Tq_Actl : 54|12@0+ (1,0) [0|4095] "Nm"  APIM_CDC,APIM_CIM,IPC
 SG_ AwdLckTqNeg_B_Actl : 55|1@0+ (1,0) [0|1] "SED" Vector__XXX
 SG_ AwdDcnntSlipTrgt_B_Rq : 56|1@0+ (1,0) [0|1] "SED" Vector__XXX
 SG_ AwdCnnct_D_Stat : 58|2@0+ (1,0) [0|3] "SED" Vector__XXX

BO_ 1054 BrakeSysFeatures_3_HS3: 8 GWM
 SG_ AutoHoldSwMde_B_Ind : 0|1@0+ (1,0) [0|1] "SED"  APIM,APIM_CDC,APIM_CIM,APIM_CISM
 SG_ AutoHoldMsgTxt_D_Rq : 4|4@0+ (1,0) [0|15] "SED"  APIM_CDC,APIM_CIM,IPC
 SG_ BrkDrvMde_D_Stat : 7|3@0+ (1,0) [0|7] "SED"  ACM,IPC
 SG_ BrkMdeInhbt_B_RqDsply : 8|1@0+ (1,0) [0|1] "SED"  APIM_CDC,APIM_CIM,IPC
 SG_ DrvSlipCtlMdeMsg_D_Rq : 13|5@0+ (1,0) [0|31] "SED"  APIM,APIM_CDC,APIM_CIM,APIM_CISM,IPC
 SG_ AutoHoldMde_D_Ind : 15|2@0+ (1,0) [0|3] "SED"  APIM_CDC,APIM_CIM,HUD_ADV,IPC
 SG_ HdcOn_B_Ind : 16|1@0+ (1,0) [0|1] "SED"  APIM,APIM_CDC,APIM_CIM,APIM_CISM,IPC
 SG_ BrkBstrVac_D_Stat : 18|2@0+ (1,0) [0|3] "SED" Vector__XXX
 SG_ BrkLineLck_D_Stat : 21|3@0+ (1,0) [0|7] "SED"  APIM,APIM_CDC,APIM_CIM,APIM_CISM,IPC
 SG_ DrvSlipCtlOffLamp_D_Rq : 23|2@0+ (1,0) [0|3] "SED"  APIM,APIM_CDC,APIM_CIM,APIM_CISM,IPC
 SG_ BrkBstrLoLampOn_B_Rq : 24|1@0+ (1,0) [0|1] "SED"  APIM_CDC,APIM_CIM
 SG_ SelDrvMdeAwd_D_Rq : 29|5@0+ (1,0) [0|31] "SED" Vector__XXX
 SG_ BrkPadMsgTxt_D_Rq : 31|2@0+ (1,0) [0|3] "SED"  APIM_CDC,APIM_CIM,IPC
 SG_ ApaBrk_D_Stat : 34|2@0+ (1,0) [0|3] "SED" Vector__XXX
 SG_ SelDrvMdeChassis_D_Rq : 39|5@0+ (1,0) [0|31] "SED" Vector__XXX
 SG_ OnePdlDrvDeny_B_Stat : 40|1@0+ (1,0) [0|1] "SED" Vector__XXX
 SG_ SelDrvMdeChassis2_D_Rq : 45|5@0+ (1,0) [0|31] "SED" Vector__XXX
 SG_ CtaBrk_D_Stat : 47|2@0+ (1,0) [0|3] "SED" Vector__XXX
 SG_ FrontDiffElckrOpen_B_Rq : 48|1@0+ (1,0) [0|1] "SED" Vector__XXX
 SG_ TrailCtlMsgTxt_D_Rq : 52|4@0+ (1,0) [0|15] "SED"  APIM_CDC,APIM_CIM,APIM_CISM,IPC
 SG_ TrailCtl_D_Stat : 55|3@0+ (1,0) [0|7] "SED"  APIM,APIM_CDC,APIM_CIM,APIM_CISM,HUD_ADV,IPC
 SG_ TrailOnePdlTqLm_B_Actl : 56|1@0+ (1,0) [0|1] "SED" Vector__XXX
 SG_ SelDrvMdeChassis3_D_Rq : 61|5@0+ (1,0) [0|31] "SED" Vector__XXX
 SG_ RbaBrk_D_Stat : 63|2@0+ (1,0) [0|3] "SED" Vector__XXX

BO_ 1055 PowertrainData_7_HS3: 8 GWM
 SG_ EcoCochA_Pc_Dsply : 7|8@0+ (0.392157,0) [0|100.000035] "percent"  APIM,APIM_CDC,APIM_CIM,APIM_CISM,IPC
 SG_ EcoCochCrus_Pc_Dsply : 15|8@0+ (0.392157,0) [0|100.000035] "percent"  APIM,APIM_CDC,APIM_CIM,APIM_CISM,IPC
 SG_ EcoCochDecel_Pc_Dsply : 23|8@0+ (0.392157,0) [0|100.000035] "percent"  APIM,APIM_CDC,APIM_CIM,APIM_CISM,IPC
 SG_ EcoCochIdlFuel_Pc_Dsply : 31|8@0+ (0.392157,0) [0|100.000035] "percent"  APIM_CDC,APIM_CIM,APIM_CISM,IPC
 SG_ EcoCochShif_Pc_Dsply : 39|8@0+ (0.392157,0) [0|100.000035] "percent"  APIM,APIM_CDC,APIM_CIM,APIM_CISM,IPC
 SG_ EcoCochInst_Pc_Dsply : 47|10@0+ (0.1,0) [0|102.3] "percent"  APIM_CDC,APIM_CIM,APIM_CISM,IPC
 SG_ EcoCochInstNeg_B_Dsply : 53|1@0+ (1,0) [0|1] "SED"  APIM_CDC,APIM_CIM,APIM_CISM,IPC
 SG_ DcdcIn_Pw2_Mx : 63|8@0+ (20,500) [500|5600] "watts" Vector__XXX

BO_ 1056 SelectDriveModeData_HS3: 8 GWM
 SG_ VehVActlBrk_No_Corr : 7|8@0+ (0.001,0.9) [0.9|1.155] "unitless"  APIM_CDC,IPC
 SG_ SelDrvMdeHmi03_D_Rq : 12|5@0+ (1,0) [0|31] "SED" Vector__XXX
 SG_ PrkBrkMsgTxt_D2_Rq : 15|3@0+ (1,0) [0|7] "Unitless"  APIM_CDC,APIM_CIM,IPC
 SG_ SelDrvMdeMsgTxt_D_Rq : 19|4@0+ (1,0) [0|15] "SED"  APIM_CDC,APIM_CIM,IPC
 SG_ SelDrvMdeMsgTxt2_D_Rq : 23|4@0+ (1,0) [0|15] "SED"  APIM,APIM_CDC,APIM_CIM,APIM_CISM
 SG_ SelDrvMdePos01_B_Avail : 24|1@0+ (1,0) [0|1] "SED"  APIM,APIM_CDC,APIM_CIM,APIM_CISM,IPC
 SG_ SelDrvMde_D_Stat : 26|2@0+ (1,0) [0|3] "SED"  APIM,APIM_CDC,APIM_CIM,APIM_CISM,IPC
 SG_ SelDrvMdePt_D_Rq : 31|5@0+ (1,0) [0|31] "SED"  GENERIC
 SG_ SelDrvMdePos02_B_Avail : 32|1@0+ (1,0) [0|1] "SED"  APIM,APIM_CDC,APIM_CIM,APIM_CISM,IPC
 SG_ AwdMde_D_RqBrk : 35|3@0+ (1,0) [0|7] "SED"  GENERIC
 SG_ AutoEpbDsply_D_Stat : 37|2@0+ (1,0) [0|3] "SED"  APIM,APIM_CDC,APIM_CIM,APIM_CISM
 SG_ SelDrvMdePos10_B_Avail : 40|1@0+ (1,0) [0|1] "SED"  APIM,APIM_CDC,APIM_CIM,APIM_CISM,IPC
 SG_ SelDrvMdePos09_B_Avail : 41|1@0+ (1,0) [0|1] "SED"  APIM,APIM_CDC,APIM_CIM,APIM_CISM,IPC
 SG_ SelDrvMdePos08_B_Avail : 42|1@0+ (1,0) [0|1] "SED"  APIM,APIM_CDC,APIM_CIM,APIM_CISM,IPC
 SG_ SelDrvMdePos07_B_Avail : 43|1@0+ (1,0) [0|1] "SED"  APIM,APIM_CDC,APIM_CIM,APIM_CISM,IPC
 SG_ SelDrvMdePos06_B_Avail : 44|1@0+ (1,0) [0|1] "SED"  APIM,APIM_CDC,APIM_CIM,APIM_CISM,IPC
 SG_ SelDrvMdePos05_B_Avail : 45|1@0+ (1,0) [0|1] "SED"  APIM,APIM_CDC,APIM_CIM,APIM_CISM,IPC
 SG_ SelDrvMdePos04_B_Avail : 46|1@0+ (1,0) [0|1] "SED"  APIM,APIM_CDC,APIM_CIM,APIM_CISM,IPC
 SG_ SelDrvMdePos03_B_Avail : 47|1@0+ (1,0) [0|1] "SED"  APIM,APIM_CDC,APIM_CIM,APIM_CISM,IPC
 SG_ AutoEpbButtnOn_B_Stat : 48|1@0+ (1,0) [0|1] "SED"  APIM,APIM_CDC,APIM_CIM,APIM_CISM
 SG_ ActvDrvMde_D2_Stat : 53|5@0+ (1,0) [0|31] "SED"  ACM,APIM,APIM_CDC,APIM_CIM,APIM_CISM,HUD_ADV,IPC
 SG_ SelDrvMdePos12_B_Avail : 54|1@0+ (1,0) [0|1] "SED"  APIM,APIM_CDC,APIM_CIM,APIM_CISM,IPC
 SG_ SelDrvMdePos11_B_Avail : 55|1@0+ (1,0) [0|1] "SED"  APIM,APIM_CDC,APIM_CIM,APIM_CISM,IPC
 SG_ AutoEpbMsgTxt_D_Rq : 58|3@0+ (1,0) [0|7] "SED"  APIM,APIM_CDC,APIM_CIM,APIM_CISM
 SG_ SelDrvMde_D2_Rq : 63|5@0+ (1,0) [0|31] "SED"  APIM,APIM_CDC,APIM_CIM,APIM_CISM,IPC

BO_ 1057 PowertrainData_1_HS3: 8 GWM
 SG_ FohEng_D_Rq : 1|2@0+ (1,0) [0|3] "SED"  IPC
 SG_ ECMMILRequest : 3|2@0+ (1,0) [0|3] "SED"  APIM_CDC,APIM_CIM,IPC
 SG_ VehVLimStat_D_Actl : 6|3@0+ (1,0) [0|7] "SED"  IPC
 SG_ VehVLimActv_B_Actl : 7|1@0+ (1,0) [0|1] "SED"  IPC
 SG_ EngIdlShutDown_D_Stat : 9|2@0+ (1,0) [0|3] "SED"  APIM,APIM_CDC,APIM_CIM,IPC
 SG_ EngIdlShutDwnTxt_D_Rq : 17|2@0+ (1,0) [0|3] "SED"  APIM_CDC,APIM_CIM,IPC
 SG_ OilPressureWarning : 18|1@0+ (1,0) [0|1] "SED"  APIM_CDC,APIM_CIM,IPC
 SG_ CoolantFanStepAct : 23|5@0+ (1,0) [0|31] "Steps"  IPC
 SG_ TrnTotLss_Tq_Est : 31|8@0+ (0.5,0) [0|127.5] "Nm"  IPC
 SG_ TrnTotTq_Rt_Est : 39|16@0+ (0.001,0) [0|65.535] "unitless"  IPC
 SG_ AirCondFluidHi_P_Actl : 55|8@0+ (0.125,0) [0|31.875] "bar"  IPC
 SG_ FUEL_ALCOHOL_PERCNT : 63|8@0+ (0.393700787,0) [0|100.393700685] "percent"  APIM_CDC,APIM_CIM,IPC

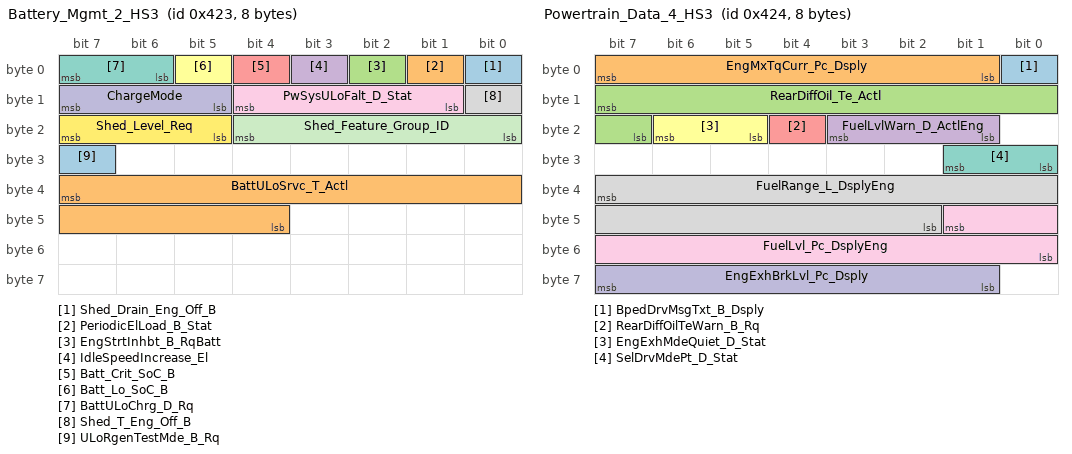
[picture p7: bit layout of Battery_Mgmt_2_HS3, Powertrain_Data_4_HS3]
BO_ 1059 Battery_Mgmt_2_HS3: 8 GWM
 SG_ Shed_Drain_Eng_Off_B : 0|1@0+ (1,0) [0|1] "SED"  APIM,APIM_CDC,APIM_CIM,APIM_CISM,TRM_ITRM
 SG_ PeriodicElLoad_B_Stat : 1|1@0+ (1,0) [0|1] "SED" Vector__XXX
 SG_ EngStrtInhbt_B_RqBatt : 2|1@0+ (1,0) [0|1] "SED" Vector__XXX
 SG_ IdleSpeedIncrease_El : 3|1@0+ (1,0) [0|1] "SED" Vector__XXX
 SG_ Batt_Crit_SoC_B : 4|1@0+ (1,0) [0|1] "SED"  APIM,APIM_CDC,APIM_CIM,APIM_CISM,IPC,TRM_ITRM
 SG_ Batt_Lo_SoC_B : 5|1@0+ (1,0) [0|1] "SED"  APIM,APIM_CDC,APIM_CIM,APIM_CISM,IPC,TRM_ITRM
 SG_ BattULoChrg_D_Rq : 7|2@0+ (1,0) [0|3] "SED" Vector__XXX
 SG_ Shed_T_Eng_Off_B : 8|1@0+ (1,0) [0|1] "SED"  APIM,APIM_CDC,APIM_CIM,APIM_CISM,TRM_ITRM
 SG_ PwSysULoFalt_D_Stat : 12|4@0+ (1,0) [0|15] "SED"  APIM_CDC,APIM_CIM,IPC
 SG_ ChargeMode : 15|3@0+ (1,0) [0|7] "SED" Vector__XXX
 SG_ Shed_Feature_Group_ID : 20|5@0+ (1,0) [0|31] "SED"  TRM_ITRM
 SG_ Shed_Level_Req : 23|3@0+ (1,0) [0|7] "SED"  APIM,APIM_CDC,APIM_CIM,APIM_CISM,IPC,TRM_ITRM
 SG_ ULoRgenTestMde_B_Rq : 31|1@0+ (1,0) [0|1] "SED" Vector__XXX
 SG_ BattULoSrvc_T_Actl : 39|12@0+ (1,0) [0|4095] "day" Vector__XXX

BO_ 1060 Powertrain_Data_4_HS3: 8 GWM
 SG_ BpedDrvMsgTxt_B_Dsply : 0|1@0+ (1,0) [0|1] "SED"  APIM_CDC,APIM_CIM,IPC
 SG_ EngMxTqCurr_Pc_Dsply : 7|7@0+ (1,0) [0|100] "percent"  APIM_CDC,APIM_CIM,IPC
 SG_ RearDiffOil_Te_Actl : 15|9@0+ (1,-40) [-40|471] "degC"  APIM,APIM_CDC,APIM_CIM,APIM_CISM,IPC
 SG_ FuelLvlWarn_D_ActlEng : 19|3@0+ (1,0) [0|7] "SED"  APIM,APIM_CDC,APIM_CIM,APIM_CISM,HUD_ADV,IPC
 SG_ RearDiffOilTeWarn_B_Rq : 20|1@0+ (1,0) [0|1] "SED"  APIM_CDC,APIM_CIM,IPC
 SG_ EngExhMdeQuiet_D_Stat : 22|2@0+ (1,0) [0|3] "SED"  ACM,APIM_CDC,APIM_CIM,APIM_CISM,IPC
 SG_ SelDrvMdePt_D_Stat : 25|2@0+ (1,0) [0|3] "SED"  GENERIC
 SG_ FuelRange_L_DsplyEng : 39|14@0+ (0.1,0) [0|1638.3] "kilometer"  APIM_CDC,APIM_CIM,IPC
 SG_ FuelLvl_Pc_DsplyEng : 41|10@0+ (0.108696,-5.217408) [-5.217408|105.9786] "percent"  APIM,APIM_CDC,APIM_CIM,APIM_CISM,IPC
 SG_ EngExhBrkLvl_Pc_Dsply : 63|7@0+ (1,0) [0|127] "Percent"  APIM_CDC,APIM_CIM,IPC

BO_ 1068 EnginePwrData_HS3: 8 GWM
 SG_ TrlrAidMsgTxt_D_Rq : 30|5@0+ (1,0) [0|31] "SED"  APIM_CDC,APIM_CIM,IPC

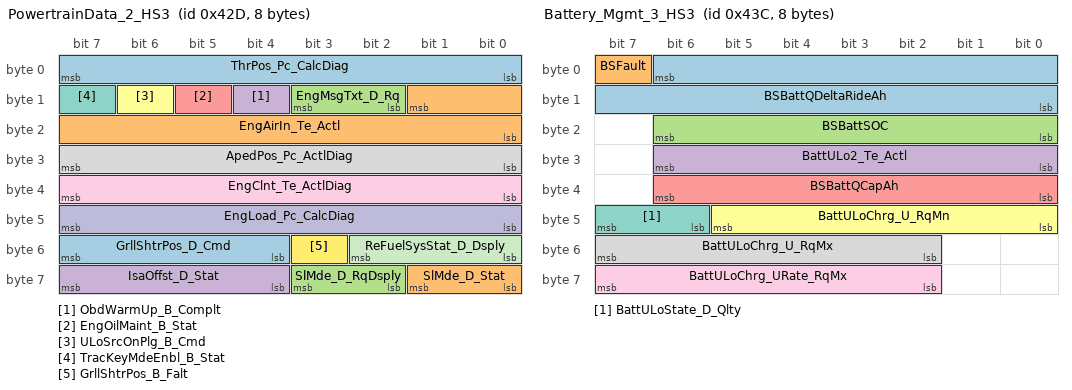
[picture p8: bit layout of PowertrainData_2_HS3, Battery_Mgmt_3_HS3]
BO_ 1069 PowertrainData_2_HS3: 8 GWM
 SG_ ThrPos_Pc_CalcDiag : 7|8@0+ (0.392157,0) [0|100.000035] "%"  IPC
 SG_ EngAirIn_Te_Actl : 9|10@0+ (0.25,-128) [-128|127.75] "degC"  APIM,APIM_CDC,APIM_CIM,IPC
 SG_ EngMsgTxt_D_Rq : 11|2@0+ (1,0) [0|3] "SED"  APIM_CDC,APIM_CIM,IPC
 SG_ ObdWarmUp_B_Complt : 12|1@0+ (1,0) [0|1] "SED" Vector__XXX
 SG_ EngOilMaint_B_Stat : 13|1@0+ (1,0) [0|1] "SED"  GENERIC
 SG_ ULoSrcOnPlg_B_Cmd : 14|1@0+ (1,0) [0|1] "SED"  IPC
 SG_ TracKeyMdeEnbl_B_Stat : 15|1@0+ (1,0) [0|1] "SED"  APIM_CDC,APIM_CIM,IPC
 SG_ ApedPos_Pc_ActlDiag : 31|8@0+ (0.392157,0) [0|100.000035] "%"  IPC
 SG_ EngClnt_Te_ActlDiag : 39|8@0+ (1,-40) [-40|215] "degC"  IPC
 SG_ EngLoad_Pc_CalcDiag : 47|8@0+ (0.392157,0) [0|100.000035] "%"  IPC
 SG_ ReFuelSysStat_D_Dsply : 50|3@0+ (1,0) [0|7] "SED"  APIM_CDC,APIM_CIM,APIM_CISM,IPC
 SG_ GrllShtrPos_B_Falt : 51|1@0+ (1,0) [0|1] "SED"  IPC
 SG_ GrllShtrPos_D_Cmd : 55|4@0+ (1,0) [0|15] "SED"  IPC
 SG_ SlMde_D_Stat : 57|2@0+ (1,0) [0|3] "SED"  APIM_CDC,APIM_CIM,HUD_ADV,IPC
 SG_ SlMde_D_RqDsply : 59|2@0+ (1,0) [0|3] "SED"  APIM,APIM_CDC,APIM_CIM,APIM_CISM,HUD_ADV,IPC
 SG_ IsaOffst_D_Stat : 63|4@0+ (1,0) [0|15] "SED"  APIM_CDC,APIM_CIM,IPC

BO_ 1071 Engine_Clutch_Data_HS3: 8 GWM
 SG_ CluPdl_PcRate_Actl : 7|8@0+ (0.04,-5) [-5|5.2] "%/ms"  IPC
 SG_ CluPdlPos_Pc_Meas : 9|10@0+ (0.1,0) [0|102.3] "%"  IPC
 SG_ CluPdlPosPcMeas_D_Qf : 11|2@0+ (1,0) [0|3] "SED"  IPC
 SG_ EngAoutIdl_N_Ntrl : 31|11@0+ (2,0) [0|4094] "rpm"  GENERIC
 SG_ EngMnfld3_P_Actl : 47|8@0+ (10,0) [0|2550] "milibar"  GENERIC
 SG_ EngAout_N_Dsply : 52|13@0+ (2,0) [0|16382] "rpm"  APIM_CDC,APIM_CIM,HUD_ADV,IPC

BO_ 1072 Cluster_Info1: 8 APIM_CDC
 SG_ ePRNDL_MODE : 0|1@0+ (1,0) [0|1] "SED"  GWM
 SG_ NtrlTowMdeEnbl_B_RqDrv : 1|1@0+ (1,0) [0|1] "SED"  GWM
 SG_ LscmbbStat_B_Actl : 2|1@0+ (1,0) [0|1] "SED"  GWM
 SG_ EngIdlShutDown_B_RqDrv : 3|1@0+ (1,0) [0|1] "SED"  GWM
 SG_ ManRgen_D_Rq : 5|2@0+ (1,0) [0|3] "SED"  GWM
 SG_ MetricActv_B_Actl : 6|1@0+ (1,0) [0|1] "SED"  APIM,APIM_CISM,GWM,HUD_ADV
 SG_ AccDeny_B_RqIpc : 7|1@0+ (1,0) [0|1] "SED"  GWM,HUD_ADV
 SG_ OdometerMasterValue : 15|24@0+ (1,0) [0|16777215] "km"  APIM,APIM_CISM,GWM
 SG_ DrvSlipCtlMde_D_Rq : 33|2@0+ (1,0) [0|3] "SED"  GWM
 SG_ DrvSlipCtlMde_B_Rq2 : 34|1@0+ (1,0) [0|1] "SED"  GWM
 SG_ AccEnbl_B_RqDrv : 35|1@0+ (1,0) [0|1] "SED"  GWM,HUD_ADV
 SG_ Fda_B_Stat : 36|1@0+ (1,0) [0|1] "SED"  GWM
 SG_ TRAILER_BRAKE_CONFIG : 37|1@0+ (1,0) [0|1] "SED"  GWM,TRM_ITRM
 SG_ MetricActvTe_B_Actl : 38|1@0+ (1,0) [0|1] "SED"  GWM
 SG_ Power_Liftgate_Mode_Cmd : 39|1@0+ (1,0) [0|1] "SED"  GWM
 SG_ KeyTypeChngMykey_D_Rq : 41|2@0+ (1,0) [0|3] "SED"  GWM
 SG_ HaDsplyCpblty_B_Stat : 42|1@0+ (1,0) [0|1] "SED"  GWM
 SG_ EngOilLife_B_RqReset : 43|1@0+ (1,0) [0|1] "SED"  GWM
 SG_ FrostWarn_D_Stat : 45|2@0+ (1,0) [0|3] "SED"  GWM
 SG_ StopStrtDrvMde_D_RqMnu : 47|2@0+ (1,0) [0|3] "SED"  GWM
 SG_ DrvPerfMde_D_Rq : 49|2@0+ (1,0) [0|3] "SED"  GWM
 SG_ ReducedGuard_D_Rq : 51|2@0+ (1,0) [0|3] "SED"  GWM
 SG_ ParkDetect_Stat : 52|1@0+ (1,0) [0|1] "SED"  GWM,HUD_ADV
 SG_ HsaMde_D_Rq : 54|2@0+ (1,0) [0|3] "SED"  GWM
 SG_ BulbChkActv_B_Stat : 55|1@0+ (1,0) [0|1] "SED"  GWM
 SG_ TRLR_SWAY_CONFIG_CMD : 56|1@0+ (1,0) [0|1] "SED"  GWM
 SG_ TrlrBrkMde_D_Rq : 57|1@0+ (1,0) [0|1] "SED"  GWM,TRM_ITRM
 SG_ PtDrvMde_D_Rq : 61|4@0+ (1,0) [0|15] "SED"  GWM
 SG_ PrkLckCtlEnbl_D_RqIpc : 63|2@0+ (1,0) [0|3] "SED"  GWM

BO_ 1076 Cluster_Info_3: 8 APIM_CDC
 SG_ FuelLvl_Pc_Dsply : 1|10@0+ (0.108696,-5.217408) [-5.217408|105.9786] "Percent"  APIM,APIM_CISM,GWM
 SG_ OdoTripRx_B_Actl : 2|1@0+ (1,0) [0|1] "SED"  GWM
 SG_ FogLghtRearButtn_B_Rq : 3|1@0+ (1,0) [0|1] "SED"  GWM
 SG_ FogLghtFrontButtn_B_Rq : 4|1@0+ (1,0) [0|1] "SED"  GWM
 SG_ DISPLAY_SPEED_OFFSET : 7|3@0+ (0.5,0) [0|3.5] "kph"  GWM
 SG_ FuelLvlPssvSide_No_Raw : 17|10@0+ (1,0) [0|1023] "Unitless"  GWM
 SG_ TirePReset_B_Rq : 18|1@0+ (1,0) [0|1] "SED"  GWM
 SG_ DieslFuelBio_B_ActlDrv : 19|1@0+ (1,0) [0|1] "SED"  GWM
 SG_ DISPLAY_SPEED_SCALING : 23|4@0+ (0.5,100) [100|107.5] "%"  GWM
 SG_ HILL_DESC_SW : 32|1@0+ (1,0) [0|1] "SED"  GWM
 SG_ AutoRgen_D_Rq : 34|2@0+ (1,0) [0|3] "SED"  GWM
 SG_ FUEL_SENSOR_NUM : 35|1@0+ (1,0) [0|1] "SED"  GWM
 SG_ IpcGearDsplyRdy_B_Stat : 36|1@0+ (1,0) [0|1] "SED"  GWM
 SG_ W2S_LAMP_OK : 37|1@0+ (1,0) [0|1] "SED"  GWM
 SG_ DrvSlipCtlMde_B_RqMyKey : 38|1@0+ (1,0) [0|1] "SED"  GWM
 SG_ FuelSecndActv_B_Actl : 39|1@0+ (1,0) [0|1] "SED"  GWM
 SG_ Veh_V_CompLimMx : 47|12@0+ (0.1,0) [0|409.5] "km/h"  GWM
 SG_ FuelLvlActvSide_No_Raw : 49|10@0+ (1,0) [0|1023] "Unitless"  GWM
 SG_ FuelLvlWarn_D_Actl : 51|2@0+ (1,0) [0|3] "SED"  APIM,APIM_CISM,ARM,GWM,HUD_ADV

BO_ 1084 Battery_Mgmt_3_HS3: 8 GWM
 SG_ BSBattQDeltaRideAh : 6|15@0+ (0.0078125,-100) [-100|155.9921875] "ampere*hour" Vector__XXX
 SG_ BSFault : 7|1@0+ (1,0) [0|1] "SED" Vector__XXX
 SG_ BSBattSOC : 22|7@0+ (1,0) [0|127] "%"  APIM,APIM_CDC,APIM_CIM,APIM_CISM
 SG_ BattULo2_Te_Actl : 30|7@0+ (1,-40) [-40|87] "degC" Vector__XXX
 SG_ BSBattQCapAh : 38|7@0+ (1,0) [0|127] "ampere*hour" Vector__XXX
 SG_ BattULoChrg_U_RqMn : 45|6@0+ (0.1,10.6) [10.6|16.9] "volt" Vector__XXX
 SG_ BattULoState_D_Qlty : 47|2@0+ (1,0) [0|3] "SED" Vector__XXX
 SG_ BattULoChrg_U_RqMx : 55|6@0+ (0.1,10.6) [10.6|16.9] "volt" Vector__XXX
 SG_ BattULoChrg_URate_RqMx : 63|6@0+ (0.1,0) [0|6.3] "volts/second" Vector__XXX

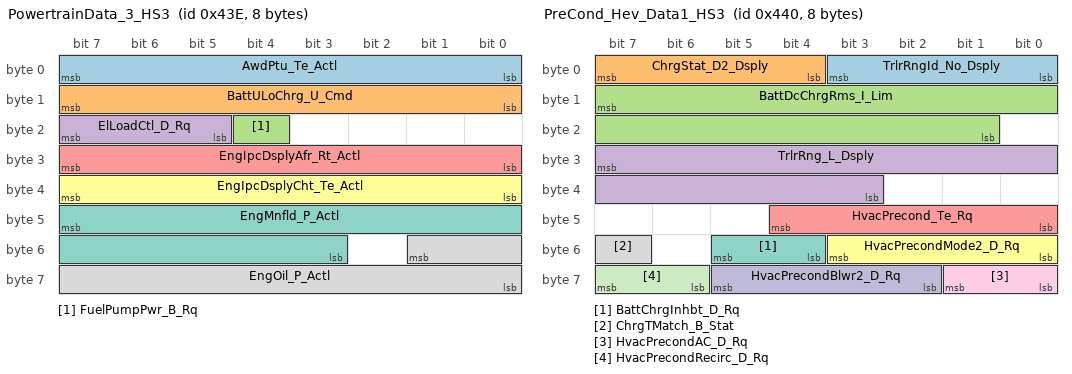
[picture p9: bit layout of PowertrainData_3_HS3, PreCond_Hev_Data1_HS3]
BO_ 1086 PowertrainData_3_HS3: 8 GWM
 SG_ AwdPtu_Te_Actl : 7|8@0+ (1,-50) [-50|205] "degC" Vector__XXX
 SG_ BattULoChrg_U_Cmd : 15|8@0+ (0.025,10.6) [10.6|16.975] "volt"  IPC
 SG_ FuelPumpPwr_B_Rq : 20|1@0+ (1,0) [0|1] "SED"  IPC
 SG_ ElLoadCtl_D_Rq : 23|3@0+ (1,0) [0|7] "SED"  IPC
 SG_ EngIpcDsplyAfr_Rt_Actl : 31|8@0+ (0.1,0) [0|25.5] "unitless"  APIM,APIM_CDC,APIM_CIM,IPC
 SG_ EngIpcDsplyCht_Te_Actl : 39|8@0+ (1,-60) [-60|195] "degC"  APIM,APIM_CDC,APIM_CIM,IPC
 SG_ EngMnfld_P_Actl : 47|13@0+ (0.1,-206.8) [-206.8|612.3] "kilopascal"  APIM,APIM_CDC,APIM_CIM,APIM_CISM,IPC
 SG_ EngOil_P_Actl : 49|10@0+ (1,0) [0|1023] "kilopascal"  APIM,APIM_CDC,APIM_CIM,APIM_CISM,IPC

BO_ 1087 Powertrain_Data_5_HS3: 8 GWM
 SG_ AdasLcObtclAbrt_B_Stat : 0|1@0+ (1,0) [0|1] "SED" Vector__XXX
 SG_ FapLcInhbt_B_Rq : 1|1@0+ (1,0) [0|1] "SED" Vector__XXX
 SG_ FapLcStopHold_B_Rq : 2|1@0+ (1,0) [0|1] "SED" Vector__XXX
 SG_ FapLcPrchgBrk_B_Rq : 3|1@0+ (1,0) [0|1] "SED" Vector__XXX
 SG_ FapLcObstcl_B_Stat : 4|1@0+ (1,0) [0|1] "SED" Vector__XXX
 SG_ FapLcMaxGrdInhbt_B_Stat : 5|1@0+ (1,0) [0|1] "SED" Vector__XXX
 SG_ FapLcMaxGrdAbrt_B_Stat : 6|1@0+ (1,0) [0|1] "SED" Vector__XXX
 SG_ FapLcActv_B_Stat : 7|1@0+ (1,0) [0|1] "SED" Vector__XXX
 SG_ BtsiShifInhbt_B_RqPt : 8|1@0+ (1,0) [0|1] "SED" Vector__XXX
 SG_ IgnOffInhbt_B_Stat : 9|1@0+ (1,0) [0|1] "SED" Vector__XXX
 SG_ CrnkInhbtHlthRate_B_Rq : 10|1@0+ (1,0) [0|1] "SED" Vector__XXX
 SG_ CrnkInhbtActv_B_Stat : 11|1@0+ (1,0) [0|1] "SED" Vector__XXX
 SG_ BattRgenLoDChrg_D_RqEng : 13|2@0+ (1,0) [0|3] "SED" Vector__XXX
 SG_ BattRgenLoChrg_D_RqEng : 15|2@0+ (1,0) [0|3] "SED" Vector__XXX
 SG_ TrlrRngeDsply_B_Stat : 16|1@0+ (1,0) [0|1] "SED"  APIM_CDC,IPC
 SG_ RepaLcGrdInhbt_B_Stat : 17|1@0+ (1,0) [0|1] "SED" Vector__XXX
 SG_ ClimtCool_D_RqPt : 19|2@0+ (1,0) [0|3] "SED" Vector__XXX
 SG_ StrtInGearMsgTxt_D_Rq : 23|4@0+ (1,0) [0|15] "SED"  APIM_CDC,APIM_CIM,IPC
 SG_ StopStrtCstm_D_Stat : 26|2@0+ (1,0) [0|3] "SED" Vector__XXX
 SG_ SelDrvMdeCstmPt_D_Stat : 31|5@0+ (1,0) [0|31] "SED" Vector__XXX
 SG_ DcacFaltMsgTxt_D2_Rq : 39|6@0+ (1,0) [0|63] "SED"  APIM,APIM_CDC,APIM_CIM,APIM_CISM,IPC
 SG_ EngIdlShutDownT_D_Stat : 47|8@0+ (1,0) [0|255] "SED"  APIM,APIM_CDC,APIM_CIM,APIM_CISM
 SG_ StopStrtImccActv_D_St : 52|3@0+ (1,0) [0|7] "SED"  APIM,APIM_CDC
 SG_ StopStrtImccTxt_D_Rq : 55|3@0+ (1,0) [0|7] "SED"  APIM,APIM_CDC
 SG_ StopStrtImccTxt_D_Dspl : 63|4@0+ (1,0) [0|15] "SED"  APIM_CDC,IPC

BO_ 1088 PreCond_Hev_Data1_HS3: 8 GWM
 SG_ TrlrRngId_No_Dsply : 3|4@0+ (1,0) [0|15] "unitless"  APIM,APIM_CDC,APIM_CIM,APIM_CISM
 SG_ ChrgStat_D2_Dsply : 7|4@0+ (1,0) [0|15] "SED"  APIM,APIM_CDC,APIM_CIM,APIM_CISM,IPC
 SG_ BattDcChrgRms_I_Lim : 15|15@0+ (0.05,0) [0|1638.35] "ampere" Vector__XXX
 SG_ TrlrRng_L_Dsply : 31|13@0+ (0.1,0) [0|819.1] "kilometer"  APIM,APIM_CDC,APIM_CIM,APIM_CISM
 SG_ HvacPrecond_Te_Rq : 44|5@0+ (0.5,14.5) [14.5|30] "degC"  GENERIC
 SG_ HvacPrecondMode2_D_Rq : 51|4@0+ (1,0) [0|15] "SED"  GENERIC
 SG_ BattChrgInhbt_D_Rq : 53|2@0+ (1,0) [0|3] "SED"  GENERIC
 SG_ ChrgTMatch_B_Stat : 55|1@0+ (1,0) [0|1] "SED"  APIM_CDC,APIM_CIM,APIM_CISM,IPC
 SG_ HvacPrecondAC_D_Rq : 57|2@0+ (1,0) [0|3] "SED"  GENERIC
 SG_ HvacPrecondBlwr2_D_Rq : 61|4@0+ (1,0) [0|15] "SED"  GENERIC
 SG_ HvacPrecondRecirc_D_Rq : 63|2@0+ (1,0) [0|3] "SED"  GENERIC

BO_ 1090 MtrTrac_Data2_HS3: 8 GWM
 SG_ Inv1Ain_I_ActlMntr : 7|15@0+ (0.1,-1000) [-1000|2276.7] "ampere" Vector__XXX
 SG_ HybVehMde_D_ActlMntr : 20|3@0+ (1,0) [0|7] "SED" Vector__XXX
 SG_ ChrgStat_D_ActlMntr : 23|3@0+ (1,0) [0|7] "SED" Vector__XXX
 SG_ VehElRnge_L_Dsply : 28|12@0+ (0.1,0) [0|409.5] "kilometer"  APIM,APIM_CDC,APIM_CIM,APIM_CISM,HUD_ADV,IPC
 SG_ Mtr2State_D_ActlMntr : 31|3@0+ (1,0) [0|7] "SED" Vector__XXX
 SG_ MtrTotNum_No_ActlMntr : 63|3@0+ (1,0) [0|7] "unitless" Vector__XXX

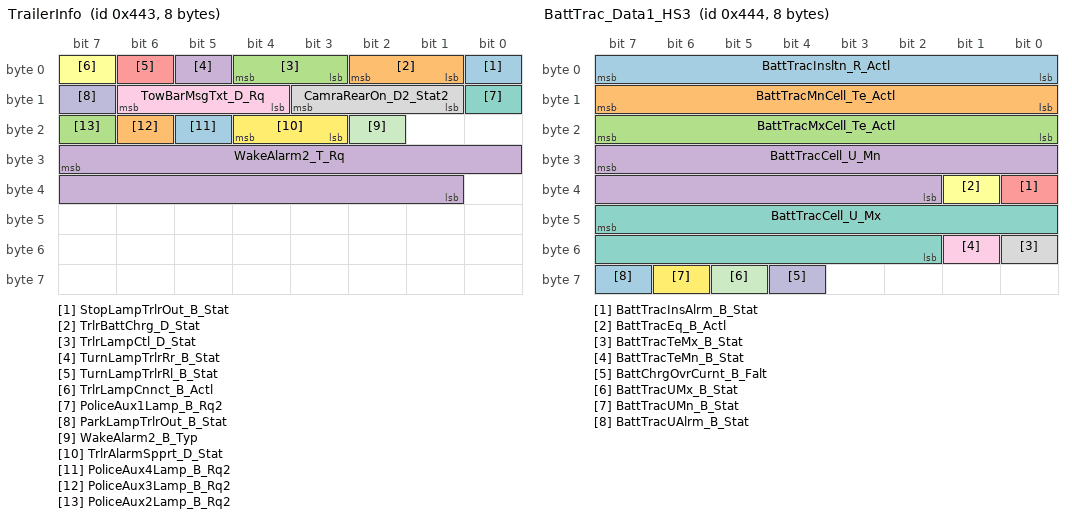
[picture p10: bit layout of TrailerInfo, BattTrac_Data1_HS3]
BO_ 1091 TrailerInfo: 8 TRM_ITRM
 SG_ StopLampTrlrOut_B_Stat : 0|1@0+ (1,0) [0|1] "SED"  APIM_CDC,APIM_CIM,GWM,IPC
 SG_ TrlrBattChrg_D_Stat : 2|2@0+ (1,0) [0|3] "SED"  APIM_CDC,APIM_CIM,GWM,IPC
 SG_ TrlrLampCtl_D_Stat : 4|2@0+ (1,0) [0|3] "SED"  APIM_CDC,APIM_CIM,GWM,IPC
 SG_ TurnLampTrlrRr_B_Stat : 5|1@0+ (1,0) [0|1] "SED"  APIM_CDC,APIM_CIM,GWM,IPC
 SG_ TurnLampTrlrRl_B_Stat : 6|1@0+ (1,0) [0|1] "SED"  APIM_CDC,APIM_CIM,GWM,IPC
 SG_ TrlrLampCnnct_B_Actl : 7|1@0+ (1,0) [0|1] "SED"  APIM,APIM_CDC,APIM_CIM,APIM_CISM,GWM,IPC
 SG_ PoliceAux1Lamp_B_Rq2 : 8|1@0+ (1,0) [0|1] "SED"  APIM_CDC,APIM_CIM,GWM,IPC
 SG_ CamraRearOn_D2_Stat2 : 11|3@0+ (1,0) [0|7] "SED"  APIM,APIM_CDC,APIM_CIM,APIM_CISM,GWM
 SG_ TowBarMsgTxt_D_Rq : 14|3@0+ (1,0) [0|7] "SED"  APIM_CDC,APIM_CIM,GWM,IPC
 SG_ ParkLampTrlrOut_B_Stat : 15|1@0+ (1,0) [0|1] "SED"  APIM_CDC,APIM_CIM,GWM,IPC
 SG_ WakeAlarm2_B_Typ : 18|1@0+ (1,0) [0|1] "SED"  GWM
 SG_ TrlrAlarmSpprt_D_Stat : 20|2@0+ (1,0) [0|3] "SED"  APIM,APIM_CDC,APIM_CIM,APIM_CISM,GWM
 SG_ PoliceAux4Lamp_B_Rq2 : 21|1@0+ (1,0) [0|1] "SED"  APIM_CDC,APIM_CIM,GWM,IPC
 SG_ PoliceAux3Lamp_B_Rq2 : 22|1@0+ (1,0) [0|1] "SED"  APIM_CDC,APIM_CIM,GWM,IPC
 SG_ PoliceAux2Lamp_B_Rq2 : 23|1@0+ (1,0) [0|1] "SED"  APIM_CDC,APIM_CIM,GWM,IPC
 SG_ WakeAlarm2_T_Rq : 31|15@0+ (1,0) [0|32767] "minute"  GWM

BO_ 1092 BattTrac_Data1_HS3: 8 GWM
 SG_ BattTracInsltn_R_Actl : 7|8@0+ (6000,0) [0|1530000] "ohm" Vector__XXX
 SG_ BattTracMnCell_Te_Actl : 15|8@0+ (1,-40) [-40|215] "degC" Vector__XXX
 SG_ BattTracMxCell_Te_Actl : 23|8@0+ (1,-40) [-40|215] "degC" Vector__XXX
 SG_ BattTracCell_U_Mn : 31|14@0+ (0.001,0) [0|16.383] "volt" Vector__XXX
 SG_ BattTracInsAlrm_B_Stat : 32|1@0+ (1,0) [0|1] "SED" Vector__XXX
 SG_ BattTracEq_B_Actl : 33|1@0+ (1,0) [0|1] "SED" Vector__XXX
 SG_ BattTracCell_U_Mx : 47|14@0+ (0.001,0) [0|16.383] "volt" Vector__XXX
 SG_ BattTracTeMx_B_Stat : 48|1@0+ (1,0) [0|1] "SED" Vector__XXX
 SG_ BattTracTeMn_B_Stat : 49|1@0+ (1,0) [0|1] "SED" Vector__XXX
 SG_ BattChrgOvrCurnt_B_Falt : 60|1@0+ (1,0) [0|1] "SED"  GENERIC
 SG_ BattTracUMx_B_Stat : 61|1@0+ (1,0) [0|1] "SED" Vector__XXX
 SG_ BattTracUMn_B_Stat : 62|1@0+ (1,0) [0|1] "SED" Vector__XXX
 SG_ BattTracUAlrm_B_Stat : 63|1@0+ (1,0) [0|1] "SED" Vector__XXX

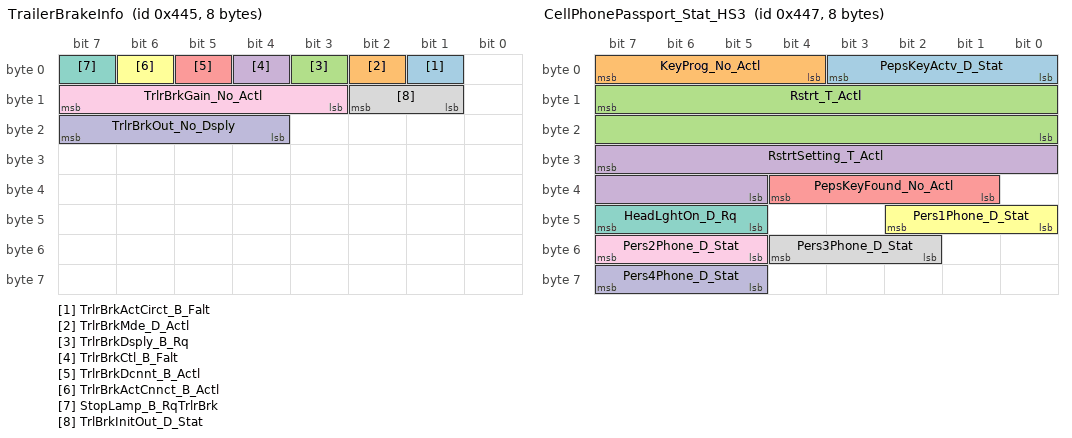
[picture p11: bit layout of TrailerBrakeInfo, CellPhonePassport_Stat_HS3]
BO_ 1093 TrailerBrakeInfo: 8 TRM_ITRM
 SG_ TrlrBrkActCirct_B_Falt : 1|1@0+ (1,0) [0|1] "SED"  APIM_CDC,APIM_CIM,GWM,IPC
 SG_ TrlrBrkMde_D_Actl : 2|1@0+ (1,0) [0|1] "SED"  APIM_CDC,APIM_CIM,GWM,IPC
 SG_ TrlrBrkDsply_B_Rq : 3|1@0+ (1,0) [0|1] "SED"  APIM_CDC,APIM_CIM,GWM,HUD_ADV,IPC
 SG_ TrlrBrkCtl_B_Falt : 4|1@0+ (1,0) [0|1] "SED"  APIM_CDC,APIM_CIM,GWM,IPC
 SG_ TrlrBrkDcnnt_B_Actl : 5|1@0+ (1,0) [0|1] "SED"  APIM_CDC,APIM_CIM,GWM,HUD_ADV,IPC
 SG_ TrlrBrkActCnnct_B_Actl : 6|1@0+ (1,0) [0|1] "SED"  APIM,APIM_CDC,APIM_CIM,APIM_CISM,GWM,HUD_ADV,IPC
 SG_ StopLamp_B_RqTrlrBrk : 7|1@0+ (1,0) [0|1] "SED"  GWM
 SG_ TrlBrkInitOut_D_Stat : 10|2@0+ (1,0) [0|3] "SED"  APIM_CDC,APIM_CIM,GWM,IPC
 SG_ TrlrBrkGain_No_Actl : 15|5@0+ (0.5,0) [0|15.5] "unitless"  APIM,APIM_CDC,APIM_CIM,APIM_CISM,GWM,HUD_ADV,IPC
 SG_ TrlrBrkOut_No_Dsply : 23|4@0+ (1,0) [0|15] "unitless"  APIM_CDC,APIM_CIM,GWM,HUD_ADV,IPC

BO_ 1095 CellPhonePassport_Stat_HS3: 8 GWM
 SG_ PepsKeyActv_D_Stat : 3|4@0+ (1,0) [0|15] "SED"  APIM_CDC,APIM_CIM
 SG_ KeyProg_No_Actl : 7|4@0+ (1,0) [0|15] "unitless" Vector__XXX
 SG_ Rstrt_T_Actl : 15|16@0+ (1,0) [0|65535] "seconds" Vector__XXX
 SG_ RstrtSetting_T_Actl : 31|11@0+ (1,0) [0|2047] "second" Vector__XXX
 SG_ PepsKeyFound_No_Actl : 36|4@0+ (1,0) [0|15] "unitless" Vector__XXX
 SG_ Pers1Phone_D_Stat : 42|3@0+ (1,0) [0|7] "SED"  APIM,APIM_CDC,APIM_CIM,APIM_CISM
 SG_ HeadLghtOn_D_Rq : 47|3@0+ (1,0) [0|7] "SED"  GENERIC
 SG_ Pers3Phone_D_Stat : 52|3@0+ (1,0) [0|7] "SED"  APIM,APIM_CDC,APIM_CIM,APIM_CISM
 SG_ Pers2Phone_D_Stat : 55|3@0+ (1,0) [0|7] "SED"  APIM,APIM_CDC,APIM_CIM,APIM_CISM
 SG_ Pers4Phone_D_Stat : 63|3@0+ (1,0) [0|7] "SED"  APIM,APIM_CDC,APIM_CIM,APIM_CISM

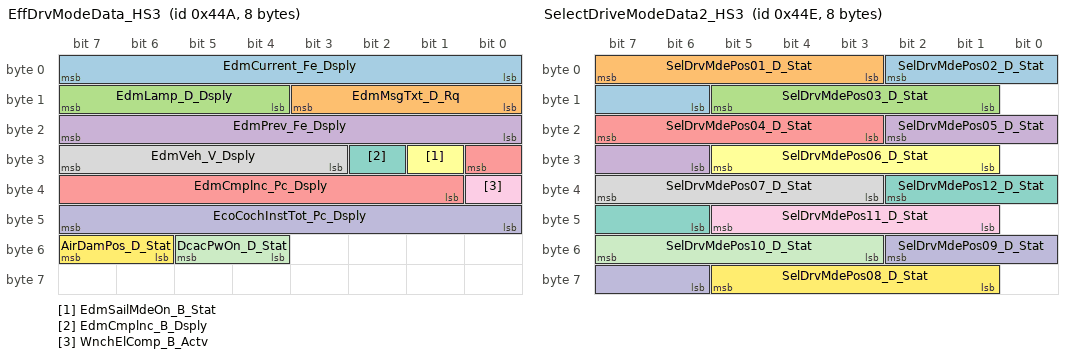
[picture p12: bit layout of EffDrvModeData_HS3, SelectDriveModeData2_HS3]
BO_ 1098 EffDrvModeData_HS3: 8 GWM
 SG_ EdmCurrent_Fe_Dsply : 7|8@0+ (0.1,0) [0|25.5] "litre/100km"  APIM_CDC,APIM_CIM,IPC
 SG_ EdmMsgTxt_D_Rq : 11|4@0+ (1,0) [0|15] "SED"  APIM_CDC,APIM_CIM,IPC
 SG_ EdmLamp_D_Dsply : 15|4@0+ (1,0) [0|15] "SED"  APIM_CDC,APIM_CIM,HUD_ADV,IPC
 SG_ EdmPrev_Fe_Dsply : 23|8@0+ (0.1,0) [0|25.5] "litre/100km"  APIM_CDC,APIM_CIM,IPC
 SG_ EdmCmplnc_Pc_Dsply : 24|8@0+ (0.392157,0) [0|100.000035] "percent"  APIM_CDC,APIM_CIM,IPC
 SG_ EdmSailMdeOn_B_Stat : 25|1@0+ (1,0) [0|1] "SED"  APIM_CDC,APIM_CIM,IPC
 SG_ EdmCmplnc_B_Dsply : 26|1@0+ (1,0) [0|1] "SED"  APIM_CDC,APIM_CIM,HUD_ADV,IPC
 SG_ EdmVeh_V_Dsply : 31|5@0+ (5,0) [0|155] "km/h"  APIM_CDC,APIM_CIM,IPC
 SG_ WnchElComp_B_Actv : 32|1@0+ (1,0) [0|1] "SED"  APIM_CDC,IPC
 SG_ EcoCochInstTot_Pc_Dsply : 47|8@0+ (0.392157,0) [0|100.000035] "percent"  APIM_CDC,APIM_CIM,IPC
 SG_ DcacPwOn_D_Stat : 53|2@0+ (1,0) [0|3] "SED"  APIM
 SG_ AirDamPos_D_Stat : 55|2@0+ (1,0) [0|3] "SED"  APIM_CDC,APIM_CIM,IPC

BO_ 1100 PowertrainData_9_HS3: 8 GWM
 SG_ GrossTrainWeight_M_Est : 7|8@0+ (100,0) [0|25500] "kilogram" Vector__XXX
 SG_ RearDiffSumpOil_Te_Est : 15|8@0+ (1,-40) [-40|215] "degC" Vector__XXX
 SG_ RearDiffLckMsg2_D_Rq : 19|4@0+ (1,0) [0|15] "SED"  APIM_CDC,APIM_CIM,IPC
 SG_ RearDiffLckLamp_D_Rq2 : 21|2@0+ (1,0) [0|3] "SED"  APIM_CDC,APIM_CIM,IPC
 SG_ EngTrlrCnnct_D_Stat : 23|2@0+ (1,0) [0|3] "SED" Vector__XXX
 SG_ AutoTowAllw_D_StatMnu : 25|2@0+ (1,0) [0|3] "SED"  APIM_CDC,APIM_CIM,IPC
 SG_ EngExhMdeQuiet_D2_Stat : 28|3@0+ (1,0) [0|7] "SED"  ACM,APIM,APIM_CDC,APIM_CIM,APIM_CISM,IPC
 SG_ SuspVlimMsgTxt_B_Rq : 29|1@0+ (1,0) [0|1] "SED"  APIM_CDC,APIM_CIM,IPC
 SG_ SpareTireDetct_B_Stat : 30|1@0+ (1,0) [0|1] "SED" Vector__XXX
 SG_ RearDiffMtrRun_B_Stat : 31|1@0+ (1,0) [0|1] "SED" Vector__XXX
 SG_ HvacCmprLim_D_Stat : 34|3@0+ (1,0) [0|7] "SED" Vector__XXX
 SG_ TrailCtlPt_B_Falt : 36|2@0+ (1,0) [0|3] "SED" Vector__XXX
 SG_ TrnNtrlIdlInhbt_B_Rq : 37|1@0+ (1,0) [0|1] "SED" Vector__XXX
 SG_ TrnNtrlIdlExit_B_Rq : 38|1@0+ (1,0) [0|1] "SED" Vector__XXX
 SG_ AutoTowActv_B_Stat : 39|1@0+ (1,0) [0|1] "SED"  APIM_CDC,APIM_CIM,IPC
 SG_ RvltnMatchAllw_D_Stat : 41|2@0+ (1,0) [0|3] "SED"  APIM_CDC,APIM_CIM,IPC
 SG_ Veh_V_DsplyTrailCtlSet : 47|6@0+ (0.5,0) [0|31.5] "unitless"  APIM_CDC,APIM_CIM,HUD_ADV,IPC
 SG_ WakeAlarm1_T_Rq : 55|15@0+ (1,0) [0|32767] "minute" Vector__XXX
 SG_ WakeAlarm1_B_Typ : 56|1@0+ (1,0) [0|1] "SED" Vector__XXX

BO_ 1101 LockControlData_HS3: 8 GWM
 SG_ Ptu_Te_Actl : 7|8@0+ (1,-50) [-50|205] "degC" Vector__XXX
 SG_ RearDiffLckLamp_D_Rq3 : 11|2@0+ (1,0) [0|3] "SED"  APIM_CDC,APIM_CIM,IPC
 SG_ AwdLckLamp_D_Rq : 13|2@0+ (1,0) [0|3] "SED"  APIM_CDC,APIM_CIM,IPC
 SG_ PtLatchActv_B_RqAwd : 14|1@0+ (1,0) [0|1] "SED" Vector__XXX
 SG_ PtuFanOn_B_Rq : 15|1@0+ (1,0) [0|1] "SED" Vector__XXX

BO_ 1102 SelectDriveModeData2_HS3: 8 GWM
 SG_ SelDrvMdePos02_D_Stat : 2|5@0+ (1,0) [0|31] "SED"  APIM,APIM_CDC,APIM_CIM,APIM_CISM,IPC
 SG_ SelDrvMdePos01_D_Stat : 7|5@0+ (1,0) [0|31] "SED"  APIM,APIM_CDC,APIM_CIM,APIM_CISM,IPC
 SG_ SelDrvMdePos03_D_Stat : 13|5@0+ (1,0) [0|31] "SED"  APIM,APIM_CDC,APIM_CIM,APIM_CISM,IPC
 SG_ SelDrvMdePos05_D_Stat : 18|5@0+ (1,0) [0|31] "SED"  APIM,APIM_CDC,APIM_CIM,APIM_CISM,IPC
 SG_ SelDrvMdePos04_D_Stat : 23|5@0+ (1,0) [0|31] "SED"  APIM,APIM_CDC,APIM_CIM,APIM_CISM,IPC
 SG_ SelDrvMdePos06_D_Stat : 29|5@0+ (1,0) [0|31] "SED"  APIM,APIM_CDC,APIM_CIM,APIM_CISM,IPC
 SG_ SelDrvMdePos12_D_Stat : 34|5@0+ (1,0) [0|31] "SED"  APIM,APIM_CDC,APIM_CIM,APIM_CISM,IPC
 SG_ SelDrvMdePos07_D_Stat : 39|5@0+ (1,0) [0|31] "SED"  APIM,APIM_CDC,APIM_CIM,APIM_CISM,IPC
 SG_ SelDrvMdePos11_D_Stat : 45|5@0+ (1,0) [0|31] "SED"  APIM,APIM_CDC,APIM_CIM,APIM_CISM,IPC
 SG_ SelDrvMdePos09_D_Stat : 50|5@0+ (1,0) [0|31] "SED"  APIM,APIM_CDC,APIM_CIM,APIM_CISM,IPC
 SG_ SelDrvMdePos10_D_Stat : 55|5@0+ (1,0) [0|31] "SED"  APIM,APIM_CDC,APIM_CIM,APIM_CISM,IPC
 SG_ SelDrvMdePos08_D_Stat : 61|5@0+ (1,0) [0|31] "SED"  APIM,APIM_CDC,APIM_CIM,APIM_CISM,IPC

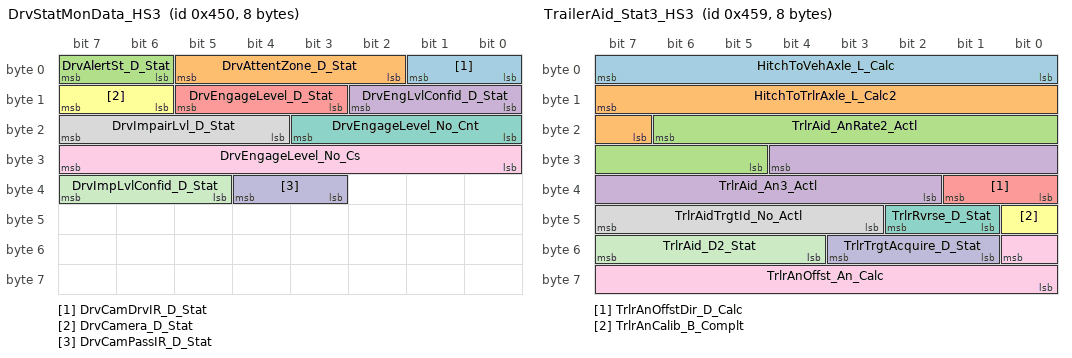
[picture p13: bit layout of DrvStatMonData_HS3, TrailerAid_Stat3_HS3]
BO_ 1104 DrvStatMonData_HS3: 8 GWM
 SG_ DrvCamDrvIR_D_Stat : 1|2@0+ (1,0) [0|3] "SED"  APIM,APIM_CDC,APIM_CIM,APIM_CISM
 SG_ DrvAttentZone_D_Stat : 5|4@0+ (1,0) [0|15] "SED" Vector__XXX
 SG_ DrvAlertSt_D_Stat : 7|2@0+ (1,0) [0|3] "SED" Vector__XXX
 SG_ DrvEngLvlConfid_D_Stat : 10|3@0+ (1,0) [0|7] "SED" Vector__XXX
 SG_ DrvEngageLevel_D_Stat : 13|3@0+ (1,0) [0|7] "SED" Vector__XXX
 SG_ DrvCamera_D_Stat : 15|2@0+ (1,0) [0|3] "SED"  APIM,APIM_CDC,APIM_CIM,APIM_CISM
 SG_ DrvEngageLevel_No_Cnt : 19|4@0+ (1,0) [0|15] "unitless" Vector__XXX
 SG_ DrvImpairLvl_D_Stat : 23|4@0+ (1,0) [0|15] "SED" Vector__XXX
 SG_ DrvEngageLevel_No_Cs : 31|8@0+ (1,0) [0|255] "unitless" Vector__XXX
 SG_ DrvCamPassIR_D_Stat : 36|2@0+ (1,0) [0|3] "SED"  APIM,APIM_CDC,APIM_CIM,APIM_CISM
 SG_ DrvImpLvlConfid_D_Stat : 39|3@0+ (1,0) [0|7] "SED" Vector__XXX

BO_ 1105 Image_Processing_Data_HS3: 8 GWM
 SG_ TrlrAidEnbl_D_RqAdas : 5|3@0+ (1,0) [0|7] "SED"  GENERIC
 SG_ CamraFrntStat_D_Stat : 7|2@0+ (1,0) [0|3] "SED"  ACM,APIM,APIM_CDC,APIM_CIM,APIM_CISM,FCIMB,IPC
 SG_ BrkDecel_B_RqRba : 8|1@0+ (1,0) [0|1] "SED" Vector__XXX
 SG_ RbaMnu_D_Rq : 10|2@0+ (1,0) [0|3] "SED"  APIM,APIM_CDC,APIM_CIM,APIM_CISM
 SG_ RbaAlrt_D_Dsply : 12|2@0+ (1,0) [0|3] "SED"  APIM,APIM_CDC,APIM_CIM,APIM_CISM,IPC
 SG_ Rba_D_Stat : 14|2@0+ (1,0) [0|3] "SED"  APIM,APIM_CDC,APIM_CIM,APIM_CISM,IPC
 SG_ TrlrHitchLamp_D_Rq2 : 15|1@0+ (1,0) [0|1] "SED" Vector__XXX
 SG_ TrlrRvrseEnbl_D2_Stat : 18|3@0+ (1,0) [0|7] "SED"  APIM,APIM_CDC,APIM_CIM,APIM_CISM,IPC,TRM_ITRM
 SG_ RbaMsg_D_Rq : 22|2@0+ (1,0) [0|3] "SED"  APIM_CDC,APIM_CIM,IPC
 SG_ BrkEnbl_B_RqRba : 23|1@0+ (1,0) [0|1] "SED" Vector__XXX
 SG_ ClrExitAsstActv_B_Rq : 24|1@0+ (1,0) [0|1] "SED"  APIM,APIM_CDC,APIM_CIM,APIM_CISM
 SG_ CamraFrntOffRd_B_Stat : 25|1@0+ (1,0) [0|1] "SED"  APIM,APIM_CDC,APIM_CIM,APIM_CISM
 SG_ TrlrRvrseMsgTxt_D2_Rq : 31|6@0+ (1,0) [0|63] "SED"  APIM,APIM_CDC,APIM_CIM,APIM_CISM,IPC,TRM_ITRM
 SG_ TrlrAidSwtchLamp_B_Rq : 32|1@0+ (1,0) [0|1] "SED"  TRM_ITRM
 SG_ TrlrHitchIcon_D_Rq : 36|4@0+ (1,0) [0|15] "SED"  APIM,APIM_CDC,APIM_CIM,APIM_CISM
 SG_ TrlrHitchChime_D_Rq : 39|3@0+ (1,0) [0|7] "SED"  APIM_CDC,APIM_CIM,IPC
 SG_ SpeedChngChime_D_Stat : 41|2@0+ (1,0) [0|3] "SED"  APIM,APIM_CDC,APIM_CIM,APIM_CISM,IPC
 SG_ TrlrHitchMsgTxt_D_Rq : 47|6@0+ (1,0) [0|63] "SED"  APIM,APIM_CDC,APIM_CIM,APIM_CISM
 SG_ ClrExitAsstMsgTxt2_D_Rq : 55|4@0+ (1,0) [0|15] "SED"  APIM,APIM_CDC,APIM_CIM,APIM_CISM

BO_ 1106 TrailerAid_Stat1_HS3: 8 GWM
 SG_ TrlrSnsId_No_Actl : 7|48@0+ (1,0) [0|281474976710655] "unitless"  APIM,APIM_CDC,APIM_CIM,APIM_CISM,IPC

BO_ 1109 eCall_Info: 8 APIM_CDC
 SG_ PassRstrnIndB_Stat : 4|3@0+ (1,0) [0|7] "SED"  GWM
 SG_ eCallConfirmation : 7|3@0+ (1,0) [0|7] "SED"  GWM,IPC
 SG_ PassRstrnIndA_D_Stat : 13|3@0+ (1,0) [0|7] "SED"  GWM
 SG_ DcacPwOn_D_RqMnu : 15|2@0+ (1,0) [0|3] "SED"  GWM

BO_ 1112 Battery_Traction_6_HS3: 8 GWM
 SG_ BattTracIsoDis_B_Stat : 0|1@0+ (1,0) [0|1] "SED" Vector__XXX
 SG_ BattTracTeEvnt_B_Stat : 2|1@0+ (1,0) [0|1] "SED" Vector__XXX
 SG_ BattChrgTrgtEvnt_B_Stat : 3|1@0+ (1,0) [0|1] "SED" Vector__XXX
 SG_ BattTracChrgSustn_B_Rq : 4|1@0+ (1,0) [0|1] "SED" Vector__XXX
 SG_ HtrnClntPump_D_Stat : 6|2@0+ (1,0) [0|3] "SED" Vector__XXX
 SG_ BattTracDcdcDis_B_Rq : 7|1@0+ (1,0) [0|1] "SED" Vector__XXX
 SG_ BattTracHvilOpen_B_Stat : 8|1@0+ (1,0) [0|1] "SED" Vector__XXX
 SG_ BattTracCoolLvl_D_Rq : 11|3@0+ (1,0) [0|7] "SED" Vector__XXX
 SG_ BattDcCnnct_D_Cmd : 14|3@0+ (1,0) [0|7] "SED" Vector__XXX
 SG_ BattTracDiagClr_B_Rq : 15|1@0+ (1,0) [0|1] "SED" Vector__XXX
 SG_ BattTracCnnct_D_Cmd : 18|3@0+ (1,0) [0|7] "SED" Vector__XXX
 SG_ CoolFanBatt_D_Rq : 23|5@0+ (1,0) [0|31] "unitless" Vector__XXX
 SG_ BattTrac2_E_Avail : 31|12@0+ (50,0) [0|204750] "watt*hour"  APIM,APIM_CDC,APIM_CIM,APIM_CISM
 SG_ BattTracClntPmp_D_Stat : 33|2@0+ (1,0) [0|3] "SED" Vector__XXX
 SG_ BattTracHeat_D_Rq : 35|2@0+ (1,0) [0|3] "SED" Vector__XXX
 SG_ BattTrac2_E_Max : 47|12@0+ (50,0) [0|204750] "watt*hour"  APIM,APIM_CDC,APIM_CIM,APIM_CISM
 SG_ BattTracHazrd_D_Stat : 50|3@0+ (1,0) [0|7] "SED"  APIM_CDC,APIM_CIM,IPC
 SG_ BattTracDcFstSustn_B_Rq : 51|1@0+ (1,0) [0|1] "SED" Vector__XXX
 SG_ BattTracDelta_Te_Actl : 63|8@0+ (0.5,-60) [-60|67.5] "degC" Vector__XXX

BO_ 1113 TrailerAid_Stat3_HS3: 8 GWM
 SG_ HitchToVehAxle_L_Calc : 7|8@0+ (0.0127,-0.508) [-0.508|2.7305] "meter" Vector__XXX
 SG_ HitchToTrlrAxle_L_Calc2 : 15|9@0+ (0.0254,0) [0|12.9794] "meter" Vector__XXX
 SG_ TrlrAid_AnRate2_Actl : 22|10@0+ (0.125,-50) [-50|77.875] "degrees/sec" Vector__XXX
 SG_ TrlrAid_An3_Actl : 28|11@0+ (0.125,-90) [-90|165.875] "degrees" Vector__XXX
 SG_ TrlrAnOffstDir_D_Calc : 33|2@0+ (1,0) [0|3] "SED"  APIM,APIM_CDC,APIM_CIM,APIM_CISM,IPC
 SG_ TrlrAnCalib_B_Complt : 40|1@0+ (1,0) [0|1] "SED"  APIM,APIM_CDC,APIM_CIM,APIM_CISM,IPC
 SG_ TrlrRvrse_D_Stat : 42|2@0+ (1,0) [0|3] "SED" Vector__XXX
 SG_ TrlrAidTrgtId_No_Actl : 47|5@0+ (1,0) [0|31] "unitless"  APIM,APIM_CDC,APIM_CIM,APIM_CISM,IPC
 SG_ TrlrAnOffst_An_Calc : 48|9@0+ (0.1,0) [0|51.1] "degrees"  APIM,APIM_CDC,APIM_CIM,APIM_CISM,IPC
 SG_ TrlrTrgtAcquire_D_Stat : 51|3@0+ (1,0) [0|7] "SED" Vector__XXX
 SG_ TrlrAid_D2_Stat : 55|4@0+ (1,0) [0|15] "SED" Vector__XXX

BO_ 1114 TrailerAid_Data: 8 APIM_CDC
 SG_ TrailCtlSwtch_B_Stat2 : 16|1@0+ (1,0) [0|1] "SED"  GWM
 SG_ TrlBrkInitOut_D_Rq : 60|2@0+ (1,0) [0|3] "SED"  GWM,TRM_ITRM

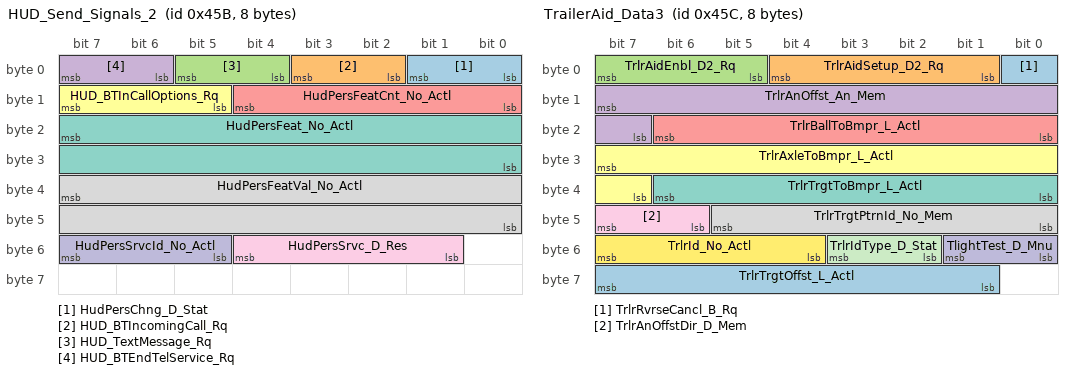
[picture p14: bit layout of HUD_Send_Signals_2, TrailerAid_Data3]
BO_ 1115 HUD_Send_Signals_2: 8 HUD_ADV
 SG_ HudPersChng_D_Stat : 1|2@0+ (1,0) [0|3] "SED"  GWM
 SG_ HUD_BTIncomingCall_Rq : 3|2@0+ (1,0) [0|3] "SED"  APIM,APIM_CDC,APIM_CIM,APIM_CISM
 SG_ HUD_TextMessage_Rq : 5|2@0+ (1,0) [0|3] "SED"  APIM,APIM_CDC,APIM_CIM,APIM_CISM
 SG_ HUD_BTEndTelService_Rq : 7|2@0+ (1,0) [0|3] "SED"  APIM,APIM_CDC,APIM_CIM,APIM_CISM
 SG_ HudPersFeatCnt_No_Actl : 12|5@0+ (1,0) [0|31] "unitless"  GWM
 SG_ HUD_BTInCallOptions_Rq : 15|3@0+ (1,0) [0|7] "SED"  APIM,APIM_CDC,APIM_CIM,APIM_CISM
 SG_ HudPersFeat_No_Actl : 23|16@0+ (1,0) [0|65535] "unitless"  GWM
 SG_ HudPersFeatVal_No_Actl : 39|16@0+ (1,0) [0|65535] "unitless"  GWM
 SG_ HudPersSrvc_D_Res : 52|4@0+ (1,0) [0|15] "SED"  GWM
 SG_ HudPersSrvcId_No_Actl : 55|3@0+ (1,0) [0|7] "unitless"  GWM

BO_ 1116 TrailerAid_Data3: 8 APIM_CDC
 SG_ TrlrRvrseCancl_B_Rq : 0|1@0+ (1,0) [0|1] "SED"  GWM
 SG_ TrlrAidSetup_D2_Rq : 4|4@0+ (1,0) [0|15] "SED"  GWM
 SG_ TrlrAidEnbl_D2_Rq : 7|3@0+ (1,0) [0|7] "SED"  GWM
 SG_ TrlrAnOffst_An_Mem : 15|9@0+ (0.1,0) [0|51.1] "degrees"  GWM
 SG_ TrlrBallToBmpr_L_Actl : 22|7@0+ (0.0127,0) [0|1.6129] "meter"  GWM
 SG_ TrlrAxleToBmpr_L_Actl : 31|9@0+ (0.0254,0) [0|12.9794] "meter"  GWM
 SG_ TrlrTrgtToBmpr_L_Actl : 38|7@0+ (0.0127,0) [0|1.6129] "meter"  GWM
 SG_ TrlrTrgtPtrnId_No_Mem : 45|6@0+ (1,0) [0|63] "unitless"  GWM
 SG_ TrlrAnOffstDir_D_Mem : 47|2@0+ (1,0) [0|3] "SED"  GWM
 SG_ TlightTest_D_Mnu : 49|2@0+ (1,0) [0|3] "SED"  GWM
 SG_ TrlrIdType_D_Stat : 51|2@0+ (1,0) [0|3] "SED"  GWM
 SG_ TrlrId_No_Actl : 55|4@0+ (1,0) [0|15] "unitless"  GWM
 SG_ TrlrTrgtOffst_L_Actl : 63|7@0+ (0.0127,0) [0|1.6129] "meter"  GWM

BO_ 1118 LocationServices_Data1: 8 APIM_CDC
 SG_ LocationServices_1 : 7|64@0+ (1,0) [0|1.84467440737096E+019] "unitless"  GWM,IPC

BO_ 1119 LocationServices_Data2: 8 APIM_CDC
 SG_ LocationServices_2 : 7|64@0+ (1,0) [0|1.84467440737096E+019] "unitless"  GWM,IPC

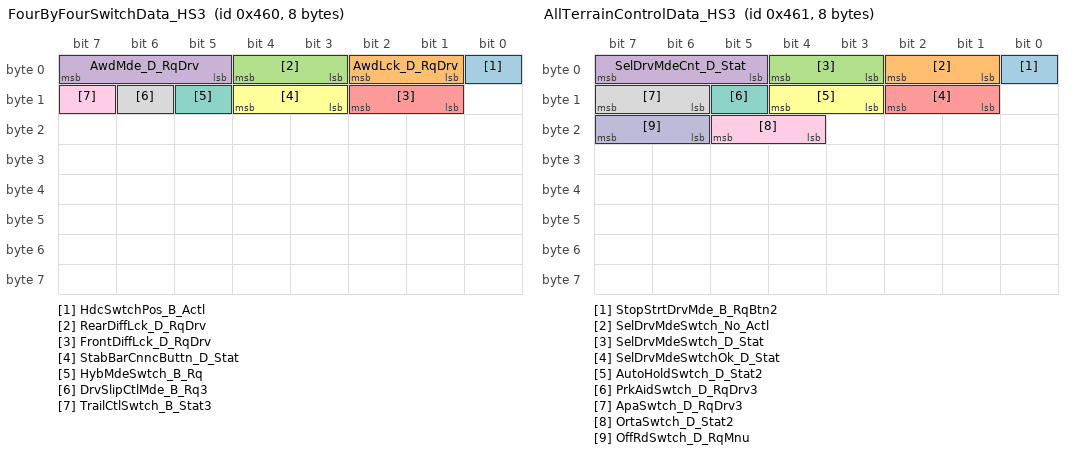
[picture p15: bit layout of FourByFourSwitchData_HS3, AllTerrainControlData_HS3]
BO_ 1120 FourByFourSwitchData_HS3: 8 GWM
 SG_ HdcSwtchPos_B_Actl : 0|1@0+ (1,0) [0|1] "SED" Vector__XXX
 SG_ AwdLck_D_RqDrv : 2|2@0+ (1,0) [0|3] "SED" Vector__XXX
 SG_ RearDiffLck_D_RqDrv : 4|2@0+ (1,0) [0|3] "SED"  APIM_CDC,APIM_CIM,IPC
 SG_ AwdMde_D_RqDrv : 7|3@0+ (1,0) [0|7] "SED"  APIM_CDC,APIM_CIM,IPC
 SG_ FrontDiffLck_D_RqDrv : 10|2@0+ (1,0) [0|3] "SED" Vector__XXX
 SG_ StabBarCnncButtn_D_Stat : 12|2@0+ (1,0) [0|3] "SED" Vector__XXX
 SG_ HybMdeSwtch_B_Rq : 13|1@0+ (1,0) [0|1] "SED" Vector__XXX
 SG_ DrvSlipCtlMde_B_Rq3 : 14|1@0+ (1,0) [0|1] "SED" Vector__XXX
 SG_ TrailCtlSwtch_B_Stat3 : 15|1@0+ (1,0) [0|1] "SED" Vector__XXX

BO_ 1121 AllTerrainControlData_HS3: 8 GWM
 SG_ StopStrtDrvMde_B_RqBtn2 : 0|1@0+ (1,0) [0|1] "SED" Vector__XXX
 SG_ SelDrvMdeSwtch_No_Actl : 2|2@0+ (1,0) [0|3] "unitless" Vector__XXX
 SG_ SelDrvMdeSwtch_D_Stat : 4|2@0+ (1,0) [0|3] "SED" Vector__XXX
 SG_ SelDrvMdeCnt_D_Stat : 7|3@0+ (1,0) [0|7] "Counts" Vector__XXX
 SG_ SelDrvMdeSwtchOk_D_Stat : 10|2@0+ (1,0) [0|3] "SED" Vector__XXX
 SG_ AutoHoldSwtch_D_Stat2 : 12|2@0+ (1,0) [0|3] "SED" Vector__XXX
 SG_ PrkAidSwtch_D_RqDrv3 : 13|1@0+ (1,0) [0|1] "SED" Vector__XXX
 SG_ ApaSwtch_D_RqDrv3 : 15|2@0+ (1,0) [0|3] "SED" Vector__XXX
 SG_ OrtaSwtch_D_Stat2 : 21|2@0+ (1,0) [0|3] "SED" Vector__XXX
 SG_ OffRdSwtch_D_RqMnu : 23|2@0+ (1,0) [0|3] "SED"  APIM,APIM_CDC,APIM_CIM,APIM_CISM

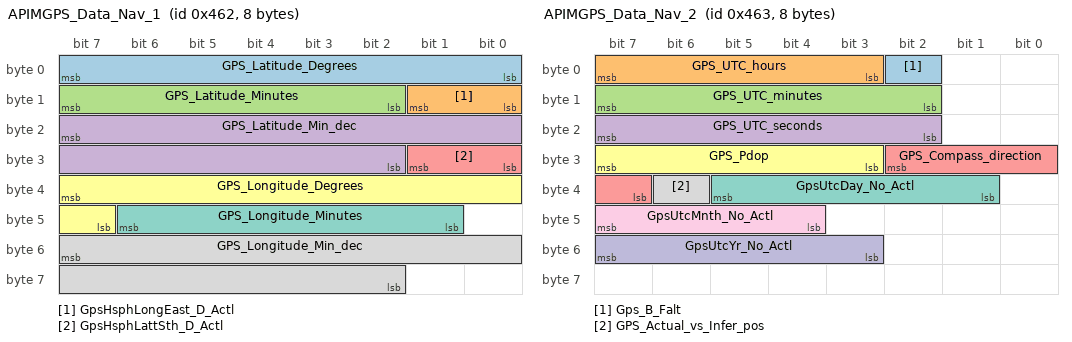
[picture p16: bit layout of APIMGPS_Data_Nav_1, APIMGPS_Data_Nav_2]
BO_ 1122 APIMGPS_Data_Nav_1: 8 APIM_CIM
 SG_ GPS_Latitude_Degrees : 7|8@0+ (1,-89) [-89|166] "degrees"  GWM
 SG_ GpsHsphLongEast_D_Actl : 9|2@0+ (1,0) [0|3] "SED"  GWM
 SG_ GPS_Latitude_Minutes : 15|6@0+ (1,0) [0|63] "minute"  GWM
 SG_ GPS_Latitude_Min_dec : 23|14@0+ (0.0001,0) [0|1.6383] "minute"  GWM
 SG_ GpsHsphLattSth_D_Actl : 25|2@0+ (1,0) [0|3] "SED"  GWM
 SG_ GPS_Longitude_Degrees : 39|9@0+ (1,-179) [-179|332] "degrees"  GWM
 SG_ GPS_Longitude_Minutes : 46|6@0+ (1,0) [0|63] "minute"  GWM
 SG_ GPS_Longitude_Min_dec : 55|14@0+ (0.0001,0) [0|1.6383] "minute"  GWM

BO_ 1123 APIMGPS_Data_Nav_2: 8 APIM_CIM
 SG_ Gps_B_Falt : 2|1@0+ (1,0) [0|1] "SED"  GWM
 SG_ GPS_UTC_hours : 7|5@0+ (1,0) [0|31] "Hours"  GWM
 SG_ GPS_UTC_minutes : 15|6@0+ (1,0) [0|63] "minute"  GWM
 SG_ GPS_UTC_seconds : 23|6@0+ (1,0) [0|63] "seconds"  GWM
 SG_ GPS_Compass_direction : 26|4@0+ (1,0) [0|15] "SED"  APIM_CDC,GWM,HUD_ADV,IPC
 SG_ GPS_Pdop : 31|5@0+ (0.2,0) [0|6.2] "unitless"  GWM
 SG_ GpsUtcDay_No_Actl : 37|5@0+ (1,1) [1|32] "day"  GWM
 SG_ GPS_Actual_vs_Infer_pos : 38|1@0+ (1,0) [0|1] "SED"  GWM
 SG_ GpsUtcMnth_No_Actl : 47|4@0+ (1,1) [1|16] "Month"  GWM
 SG_ GpsUtcYr_No_Actl : 55|5@0+ (1,2010) [2010|2041] "Year"  GWM

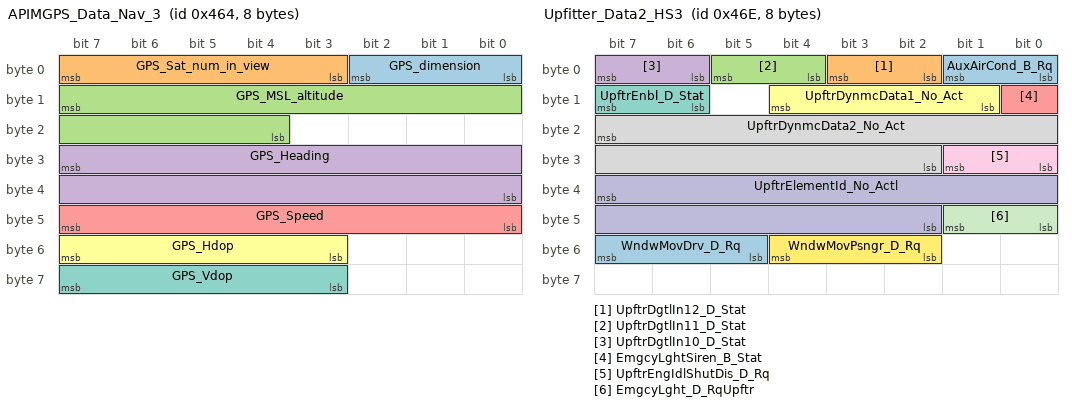
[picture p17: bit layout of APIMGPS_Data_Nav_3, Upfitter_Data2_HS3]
BO_ 1124 APIMGPS_Data_Nav_3: 8 APIM_CIM
 SG_ GPS_dimension : 2|3@0+ (1,0) [0|7] "SED"  GWM
 SG_ GPS_Sat_num_in_view : 7|5@0+ (1,0) [0|31] "unitless"  GWM
 SG_ GPS_MSL_altitude : 15|12@0+ (10,-20460) [-20460|20490] "feet"  GWM
 SG_ GPS_Heading : 31|16@0+ (0.01,0) [0|655.35] "degrees"  GWM
 SG_ GPS_Speed : 47|8@0+ (1,0) [0|255] "MPH"  GWM
 SG_ GPS_Hdop : 55|5@0+ (0.2,0) [0|6.2] "unitless"  GWM
 SG_ GPS_Vdop : 63|5@0+ (0.2,0) [0|6.2] "unitless"  GWM

BO_ 1128 BatteryCharge_Data2_HS3: 8 GWM
 SG_ ChrgrSrvcRqd_B_Rq : 0|1@0+ (1,0) [0|1] "SED"  APIM_CDC,APIM_CIM,IPC
 SG_ ChrgrInPwMde_D_Actl : 4|4@0+ (1,0) [0|15] "SED" Vector__XXX
 SG_ ChrgCordLck_D_Stat : 7|3@0+ (1,0) [0|7] "SED"  APIM,APIM_CDC,APIM_CIM,APIM_CISM
 SG_ ChrgCordChlng1_No_Actl : 15|8@0+ (1,0) [0|255] "unitless" Vector__XXX
 SG_ ChrgCordChlng2_No_Actl : 23|8@0+ (1,0) [0|255] "unitless" Vector__XXX
 SG_ BptTgl_B_Complt : 29|1@0+ (1,0) [0|1] "SED" Vector__XXX
 SG_ ChrgrClntFlw_D_Rq : 31|2@0+ (1,0) [0|3] "SED" Vector__XXX
 SG_ ChrgrAvailEvnt_B_Stat : 32|1@0+ (1,0) [0|1] "SED" Vector__XXX
 SG_ ChrgChngEvnt_B_Stat : 33|1@0+ (1,0) [0|1] "SED" Vector__XXX
 SG_ ChrgCrdLck_D_Falt : 41|2@0+ (1,0) [0|3] "SED"  APIM,APIM_CDC,APIM_CIM,APIM_CISM,IPC
 SG_ ChrgrS2Swtch_B_Stat : 42|1@0+ (1,0) [0|1] "SED" Vector__XXX
 SG_ ChrgPortDrOpen_B_Stat : 43|1@0+ (1,0) [0|1] "SED"  APIM_CDC,APIM_CIM,IPC
 SG_ CoolFanChrgr_D_Rq : 45|2@0+ (1,0) [0|3] "SED" Vector__XXX
 SG_ PlgStatEvnt_B_Stat : 46|1@0+ (1,0) [0|1] "SED" Vector__XXX
 SG_ ChrgrCnnctPwr_B_Stat : 47|1@0+ (1,0) [0|1] "SED" Vector__XXX
 SG_ DgtlCommGtwyMde_D_Rq : 48|4@0+ (1,0) [0|15] "SED" Vector__XXX
 SG_ ExtChrgNowButtn_B_Rq : 49|1@0+ (1,0) [0|1] "SED" Vector__XXX
 SG_ ChrgrDcOvrVolt_B_Falt : 50|1@0+ (1,0) [0|1] "SED" Vector__XXX
 SG_ AcChrgRdy_B_Stat : 51|1@0+ (1,0) [0|1] "SED" Vector__XXX
 SG_ ChrgrDcOvrCurnt_B_Falt : 56|1@0+ (1,0) [0|1] "SED" Vector__XXX
 SG_ ChrgrPncEnbl_D_Stat : 58|2@0+ (1,0) [0|3] "SED" Vector__XXX
 SG_ ChrgrCc2Cnnct_B_Falt : 59|1@0+ (1,0) [0|1] "SED" Vector__XXX
 SG_ ChrgPortDcTeMx_B_Falt : 60|1@0+ (1,0) [0|1] "SED" Vector__XXX

BO_ 1134 Upfitter_Data2_HS3: 8 GWM
 SG_ AuxAirCond_B_Rq : 1|2@0+ (1,0) [0|3] "SED" Vector__XXX
 SG_ UpftrDgtlIn12_D_Stat : 3|2@0+ (1,0) [0|3] "SED" Vector__XXX
 SG_ UpftrDgtlIn11_D_Stat : 5|2@0+ (1,0) [0|3] "SED" Vector__XXX
 SG_ UpftrDgtlIn10_D_Stat : 7|2@0+ (1,0) [0|3] "SED" Vector__XXX
 SG_ EmgcyLghtSiren_B_Stat : 8|1@0+ (1,0) [0|1] "SED" Vector__XXX
 SG_ UpftrDynmcData1_No_Act : 12|4@0+ (1,0) [0|15] "unitless"  APIM,APIM_CDC
 SG_ UpftrEnbl_D_Stat : 15|2@0+ (1,0) [0|3] "SED" Vector__XXX
 SG_ UpftrDynmcData2_No_Act : 23|14@0+ (1,0) [0|16383] "unitless"  APIM,APIM_CDC
 SG_ UpftrEngIdlShutDis_D_Rq : 25|2@0+ (1,0) [0|3] "SED" Vector__XXX
 SG_ UpftrElementId_No_Actl : 39|14@0+ (1,0) [0|16383] "unitless"  APIM,APIM_CDC
 SG_ EmgcyLght_D_RqUpftr : 41|2@0+ (1,0) [0|3] "SED" Vector__XXX
 SG_ WndwMovPsngr_D_Rq : 52|3@0+ (1,0) [0|7] "SED" Vector__XXX
 SG_ WndwMovDrv_D_Rq : 55|3@0+ (1,0) [0|7] "SED" Vector__XXX

BO_ 1137 Cluster_HEV_Data10_HS3: 8 GWM
 SG_ RngPerChrgAvg_L_Dsply : 7|12@0+ (0.1,0) [0|409.5] "km"  APIM,APIM_CDC,APIM_CIM,APIM_CISM,IPC
 SG_ RngPerChrgLbl_L_Dsply : 11|12@0+ (0.1,0) [0|409.5] "km"  APIM_CDC,APIM_CIM,APIM_CISM,IPC
 SG_ RngImpctDrv_Pc_Dsply : 31|10@0+ (0.2,-102) [-102|102.6] "percent"  APIM_CDC,APIM_CIM,APIM_CISM,IPC
 SG_ RngImpctClim_Pc_Dsply : 37|10@0+ (0.2,-102) [-102|102.6] "percent"  APIM_CDC,APIM_CIM,APIM_CISM,IPC
 SG_ RngImpctExt_Pc_Dsply : 43|10@0+ (0.2,-102) [-102|102.6] "percent"  APIM_CDC,APIM_CIM,APIM_CISM,IPC
 SG_ RngImpctTot_Pc_Dsply : 49|10@0+ (0.2,-102) [-102|102.6] "percent"  APIM_CDC,APIM_CIM,APIM_CISM,IPC

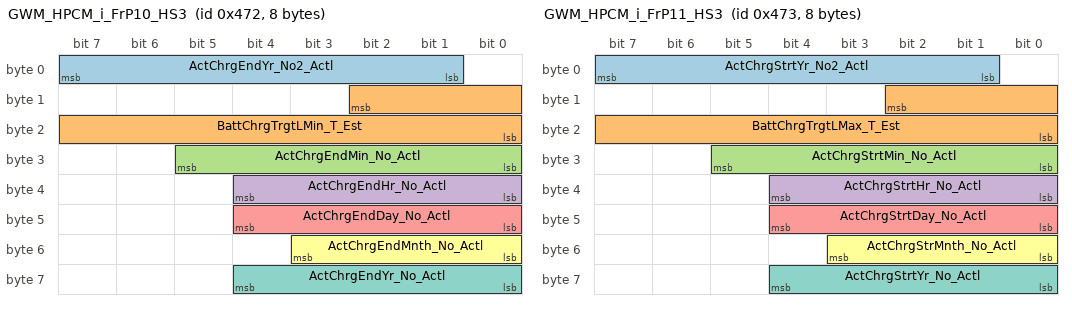
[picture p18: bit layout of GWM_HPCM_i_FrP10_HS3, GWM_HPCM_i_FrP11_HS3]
BO_ 1138 GWM_HPCM_i_FrP10_HS3: 8 GWM
 SG_ ActChrgEndYr_No2_Actl : 7|7@0+ (1,2017) [2017|2144] "year"  APIM,APIM_CDC,APIM_CIM,APIM_CISM,IPC
 SG_ BattChrgTrgtLMin_T_Est : 10|11@0+ (1,0) [0|2047] "minute"  APIM,APIM_CDC,APIM_CIM,APIM_CISM
 SG_ ActChrgEndMin_No_Actl : 29|6@0+ (1,0) [0|63] "minute"  APIM,APIM_CDC,APIM_CIM,APIM_CISM,IPC
 SG_ ActChrgEndHr_No_Actl : 36|5@0+ (1,0) [0|31] "hour"  APIM,APIM_CDC,APIM_CIM,APIM_CISM,IPC
 SG_ ActChrgEndDay_No_Actl : 44|5@0+ (1,1) [1|31] "day"  APIM,APIM_CDC,APIM_CIM,APIM_CISM,IPC
 SG_ ActChrgEndMnth_No_Actl : 51|4@0+ (1,1) [1|16] "month"  APIM,APIM_CDC,APIM_CIM,APIM_CISM,IPC
 SG_ ActChrgEndYr_No_Actl : 60|5@0+ (1,2010) [2010|2041] "year"  APIM,APIM_CDC,APIM_CIM,APIM_CISM,IPC

BO_ 1139 GWM_HPCM_i_FrP11_HS3: 8 GWM
 SG_ ActChrgStrtYr_No2_Actl : 7|7@0+ (1,2017) [2017|2144] "year"  APIM,APIM_CDC,APIM_CIM,APIM_CISM,IPC
 SG_ BattChrgTrgtLMax_T_Est : 10|11@0+ (1,0) [0|2047] "minute"  APIM,APIM_CDC,APIM_CIM,APIM_CISM
 SG_ ActChrgStrtMin_No_Actl : 29|6@0+ (1,0) [0|63] "minute"  APIM,APIM_CDC,APIM_CIM,APIM_CISM,IPC
 SG_ ActChrgStrtHr_No_Actl : 36|5@0+ (1,0) [0|31] "hour"  APIM,APIM_CDC,APIM_CIM,APIM_CISM,HUD_ADV,IPC
 SG_ ActChrgStrtDay_No_Actl : 44|5@0+ (1,1) [1|32] "day"  APIM,APIM_CDC,APIM_CIM,APIM_CISM,IPC
 SG_ ActChrgStrMnth_No_Actl : 51|4@0+ (1,1) [1|16] "month"  APIM,APIM_CDC,APIM_CIM,APIM_CISM,IPC
 SG_ ActChrgStrtYr_No_Actl : 60|5@0+ (1,2010) [2010|2041] "year"  APIM,APIM_CDC,APIM_CIM,APIM_CISM,IPC

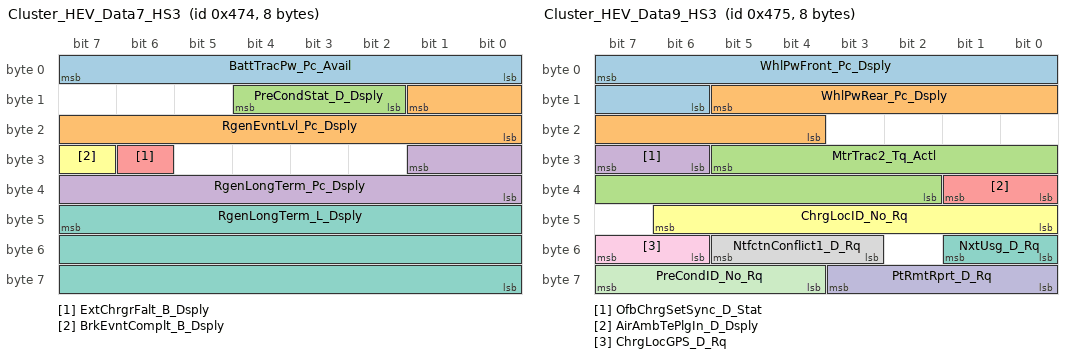
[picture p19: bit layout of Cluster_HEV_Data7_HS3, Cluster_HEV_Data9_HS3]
BO_ 1140 Cluster_HEV_Data7_HS3: 8 GWM
 SG_ BattTracPw_Pc_Avail : 7|8@0+ (0.5,0) [0|127.5] "percent"  APIM_CDC,APIM_CIM,IPC
 SG_ RgenEvntLvl_Pc_Dsply : 9|10@0+ (0.1,0) [0|102.3] "percent"  APIM_CDC,APIM_CIM,IPC
 SG_ PreCondStat_D_Dsply : 12|3@0+ (1,0) [0|7] "SED"  IPC
 SG_ RgenLongTerm_Pc_Dsply : 25|10@0+ (0.1,0) [0|102.3] "percent"  APIM_CDC,APIM_CIM,IPC
 SG_ ExtChrgrFalt_B_Dsply : 30|1@0+ (1,0) [0|1] "SED"  APIM_CDC,APIM_CIM,IPC
 SG_ BrkEvntComplt_B_Dsply : 31|1@0+ (1,0) [0|1] "SED"  APIM_CDC,APIM_CIM,IPC
 SG_ RgenLongTerm_L_Dsply : 47|24@0+ (0.1,0) [0|1677721.5] "km"  APIM_CDC,APIM_CIM,IPC

BO_ 1141 Cluster_HEV_Data9_HS3: 8 GWM
 SG_ WhlPwFront_Pc_Dsply : 7|10@0+ (0.2,-102.2) [-102.2|102.4] "percent"  APIM_CDC,APIM_CIM,IPC
 SG_ WhlPwRear_Pc_Dsply : 13|10@0+ (0.2,-102.2) [-102.2|102.4] "percent"  APIM_CDC,APIM_CIM,IPC
 SG_ MtrTrac2_Tq_Actl : 29|12@0+ (1,-2047) [-2047|2048] "Nm" Vector__XXX
 SG_ OfbChrgSetSync_D_Stat : 31|2@0+ (1,0) [0|3] "SED"  APIM,APIM_CDC,APIM_CIM,APIM_CISM
 SG_ AirAmbTePlgIn_D_Dsply : 33|2@0+ (1,0) [0|3] "SED"  APIM_CDC,APIM_CIM,APIM_CISM,IPC
 SG_ ChrgLocID_No_Rq : 46|7@0+ (1,0) [0|127] "unitless"  IPC
 SG_ NxtUsg_D_Rq : 49|2@0+ (1,0) [0|3] "SED"  IPC
 SG_ NtfctnConflict1_D_Rq : 53|3@0+ (1,0) [0|7] "SED"  APIM,APIM_CDC,APIM_CIM,APIM_CISM
 SG_ ChrgLocGPS_D_Rq : 55|2@0+ (1,0) [0|3] "SED"  IPC
 SG_ PtRmtRprt_D_Rq : 59|4@0+ (1,0) [0|15] "SED"  IPC
 SG_ PreCondID_No_Rq : 63|4@0+ (1,0) [0|15] "unitless"  IPC

BO_ 1142 ConsTip_Data_HS3: 8 GWM
 SG_ ConsTipA_No_Dsply : 17|10@0+ (0.1,0) [0|102.3] "percent"  APIM,APIM_CDC,APIM_CIM,APIM_CISM,IPC
 SG_ ConsTipMsg3_D_Dsply : 21|4@0+ (1,0) [0|15] "SED"  APIM,APIM_CDC,APIM_CIM,APIM_CISM,IPC
 SG_ ConsTipDecel_No_Dsply : 33|10@0+ (0.1,0) [0|102.3] "percent"  APIM,APIM_CDC,APIM_CIM,APIM_CISM,IPC
 SG_ ConsTipMsg2_D_Dsply : 37|4@0+ (1,0) [0|15] "SED"  APIM,APIM_CDC,APIM_CIM,APIM_CISM,IPC
 SG_ ConsTipV_No_Dsply : 49|10@0+ (0.1,0) [0|102.3] "percent"  APIM,APIM_CDC,APIM_CIM,APIM_CISM,IPC
 SG_ ConsTipMsg1_D_Dsply : 53|4@0+ (1,0) [0|15] "SED"  APIM,APIM_CDC,APIM_CIM,APIM_CISM,IPC

BO_ 1143 ConsTip_Data2_HS3: 8 GWM
 SG_ EffAvgChrg_Pc_Dsply : 17|10@0+ (0.1,0) [0|102.3] "percent"  APIM_CDC,APIM_CIM,APIM_CISM,IPC
 SG_ AirCondClntLo_Te_Actl : 39|8@0+ (1,-60) [-60|195] "degC" Vector__XXX
 SG_ AirCondFluidLo_P_Actl : 47|8@0+ (0.125,0) [0|31.875] "bar" Vector__XXX
 SG_ ConsTipTot_Pc_Dsply : 49|10@0+ (0.1,0) [0|102.3] "percent"  APIM_CDC,APIM_CIM,IPC
 SG_ ConsTipUnitPt_D_Dsply : 51|2@0+ (1,0) [0|3] "SED"  APIM,APIM_CDC,APIM_CIM,APIM_CISM,IPC
 SG_ ChrgCompltMsgTxt_D_Rq : 53|2@0+ (1,0) [0|3] "SED"  APIM,APIM_CDC,APIM_CIM,APIM_CISM,IPC

BO_ 1144 MHT_EV_Wakeup_HS3: 8 GWM
 SG_ WakeAlarm0_T_Rq : 7|15@0+ (1,0) [0|32767] "minute" Vector__XXX
 SG_ BattTracDrvSustn_B_Rq : 8|1@0+ (1,0) [0|1] "SED" Vector__XXX
 SG_ HtrnCnnctPwr_B_Stat : 16|1@0+ (1,0) [0|1] "SED" Vector__XXX
 SG_ PtcHtr_D_Stat : 18|2@0+ (1,0) [0|3] "SED" Vector__XXX
 SG_ HtrnClntFlw_D_Rq : 20|2@0+ (1,0) [0|3] "SED" Vector__XXX
 SG_ WakeAlarm0_B_Typ : 21|1@0+ (1,0) [0|1] "SED" Vector__XXX
 SG_ ChrgNowEvnt_B_Stat : 22|1@0+ (1,0) [0|1] "SED" Vector__XXX
 SG_ CabinDrvSustn_B_Rq : 23|1@0+ (1,0) [0|1] "SED" Vector__XXX
 SG_ BrkAppl_D_RqPt : 25|2@0+ (1,0) [0|3] "SED" Vector__XXX
 SG_ HtrnDcdcDis_B_Rq : 26|1@0+ (1,0) [0|1] "SED" Vector__XXX
 SG_ BattTracChillerOn_B_Rq : 27|1@0+ (1,0) [0|1] "SED" Vector__XXX
 SG_ BattTracChiller_D_Stat : 29|2@0+ (1,0) [0|3] "SED" Vector__XXX
 SG_ BattClntVlvOvrrd_D_Rq : 31|2@0+ (1,0) [0|3] "SED" Vector__XXX
 SG_ PreCondBatt_B_Actl : 32|1@0+ (1,0) [0|1] "SED" Vector__XXX
 SG_ BattChrgTrgtSoC_D_Rq : 35|3@0+ (1,0) [0|7] "Percent"  APIM_CDC,APIM_CIM,APIM_CISM,IPC
 SG_ HeatCoreSovRear_B_Rq : 36|1@0+ (1,0) [0|1] "SED" Vector__XXX
 SG_ CabnEvapSovRear_B_Rq : 37|1@0+ (1,0) [0|1] "SED" Vector__XXX
 SG_ CabnEvapSovFront_B_Rq : 38|1@0+ (1,0) [0|1] "SED" Vector__XXX
 SG_ BattChlrSov_B_Rq : 39|1@0+ (1,0) [0|1] "SED" Vector__XXX
 SG_ FstChrgCmplt_T_Est : 41|10@0+ (1,0) [0|1023] "minute"  APIM,APIM_CDC,APIM_CIM,APIM_CISM,IPC
 SG_ BattTracClimtDis_B_Stat : 42|1@0+ (1,0) [0|1] "SED" Vector__XXX
 SG_ ULoBattTrnsfrSustn_B_Rq : 43|1@0+ (1,0) [0|1] "SED" Vector__XXX
 SG_ ULoBattTransfer_D_Stat : 46|3@0+ (1,0) [0|7] "SED" Vector__XXX
 SG_ BattTracClntVlv_B_Rq : 47|1@0+ (1,0) [0|1] "SED" Vector__XXX
 SG_ BattMtrTeGage_B_Dsply : 56|1@0+ (1,0) [0|1] "SED"  IPC
 SG_ AwdLckMde_D_Stat : 59|3@0+ (1,0) [0|7] "SED" Vector__XXX
 SG_ BattTracCool_B_Actl : 60|1@0+ (1,0) [0|1] "SED" Vector__XXX
 SG_ BattChrgInhbt_D2_Rq : 63|3@0+ (1,0) [0|7] "SED" Vector__XXX

BO_ 1145 HEV_ChargeStat_HS3: 8 GWM
 SG_ NxtUsgSocEst_Pc_Dsply : 7|8@0+ (0.5,0) [0|127.5] "unitless"  APIM,APIM_CDC,APIM_CIM,APIM_CISM
 SG_ VehElRngeNut_L_Dsply : 11|12@0+ (0.1,0) [0|409.5] "km"  APIM,APIM_CDC,APIM_CIM,APIM_CISM,IPC
 SG_ ChargeNowDuration_St : 31|8@0+ (0.1,0) [0|25.5] "hour"  APIM,APIM_CDC,APIM_CIM,APIM_CISM,IPC
 SG_ EstmChrgTimeLP_St : 39|8@0+ (0.1,0) [0|25.5] "hour"  APIM,APIM_CDC,APIM_CIM,APIM_CISM,IPC
 SG_ EstmChrgTimeHP_St : 47|8@0+ (0.1,0) [0|25.5] "hour"  APIM,APIM_CDC,APIM_CIM,APIM_CISM,IPC
 SG_ VehElRngeNut_L2_Dsply : 55|13@0+ (0.1,0) [0|819.1] "km"  APIM,APIM_CDC,APIM_CIM,APIM_CISM

BO_ 1146 TrailerInfo_ITRM: 8 TRM_ITRM
 SG_ TrlrAidCtl_U_RqDrv : 31|12@0+ (0.00125,0) [0|5.11875] "volt"  GWM
 SG_ TrlrAidSwtch_D_RqDrv : 35|2@0+ (1,0) [0|3] "SED"  GWM

BO_TX_BU_ 1000 : ACM,APIM_CIM,APIM_CISM;
BO_TX_BU_ 1002 : APIM,APIM_CDC,APIM_CIM,APIM_CISM;
BO_TX_BU_ 1008 : APIM,APIM_CDC,APIM_CIM,APIM_CISM;
BO_TX_BU_ 1009 : APIM,APIM_CDC,APIM_CIM,APIM_CISM;
BO_TX_BU_ 1019 : APIM_CDC,IPC;
BO_TX_BU_ 1020 : APIM,APIM_CDC,APIM_CIM,APIM_CISM;
BO_TX_BU_ 1049 : APIM,APIM_CDC,APIM_CIM,APIM_CISM;
BO_TX_BU_ 1072 : APIM_CDC,APIM_CIM,APIM_CISM,IPC;
BO_TX_BU_ 1076 : APIM_CDC,APIM_CIM,IPC;
BO_TX_BU_ 1109 : APIM,APIM_CDC,APIM_CIM,APIM_CISM;
BO_TX_BU_ 1114 : APIM_CDC,APIM_CIM,APIM_CISM,IPC;
BO_TX_BU_ 1116 : APIM,APIM_CDC,APIM_CIM,APIM_CISM;
BO_TX_BU_ 1118 : APIM,APIM_CDC,APIM_CIM,APIM_CISM;
BO_TX_BU_ 1119 : APIM,APIM_CDC,APIM_CIM,APIM_CISM;
BO_TX_BU_ 1122 : APIM,APIM_CIM,APIM_CISM;
BO_TX_BU_ 1123 : APIM,APIM_CIM,APIM_CISM;
BO_TX_BU_ 1124 : APIM,APIM_CIM,APIM_CISM;
CM_ BO_ 1009 "APIM Tx";
CM_ BO_ 1106 " new RCM Serial Trailer Aid (TrailerAid_Stat1) 48 bits";
CM_ BO_ 1122 "HS3 APIM Sync Gen3 Tx 0x462.  FrameGateway to 0x465 on HS1, HS2, HS3 and MS1.";
CM_ BO_ 1123 "HS3 APIM Sync Gen3 Tx 0x463.  FrameGateway to 0x466 on HS1, HS2, HS3 and MS1.";
CM_ BO_ 1124 "HS3 APIM Sync Gen3 Tx 0x464.  FrameGateway to 0x467 on HS1, HS2, HS3 and MS1.";
BA_DEF_ BO_  "E2EDataId" INT 0 65535;
BA_DEF_ BO_  "E2EDataLength" INT 0 512;
BA_DEF_ BO_  "E2EProfile" STRING ;
BA_DEF_ BO_  "GenMsgRoutingTimeoutTime" INT 0 5000;
BA_DEF_ BO_  "MessageGateway" ENUM  "No","Yes";
BA_DEF_ BO_  "VFrameFormat" ENUM  "StandardCAN","ExtendedCAN","reserved","reserved","reserved","reserved","reserved","reserved","reserved","reserved","reserved","reserved","reserved","reserved","StandardCAN_FD","ExtendedCAN_FD";
BA_DEF_ SG_  "ECGUsedRxSignal" ENUM  "No","Yes";
BA_DEF_ SG_  "ECGUsedTxSignal" ENUM  "No","Yes";
BA_DEF_ SG_  "GenSigInactiveValue" INT 0 100000;
BA_DEF_ SG_  "GenSigSendType" ENUM  "Cyclic","OnWrite","vector_leerstring","OnChange","vector_leerstring","IfActive","vector_leerstring","NoSigSendType";
BA_DEF_ BO_  "NetworkInitialization" ENUM  "No","Yes";
BA_DEF_ SG_  "GenSigStartValue" HEX 0 268435455;
BA_DEF_ BO_  "GenMsgStartDelayTime" INT 0 10000;
BA_DEF_ SG_  "WakeupSignal" ENUM  "No","Yes";
BA_DEF_ BO_  "GenMsgNrOfRepetition" INT 0 100;
BA_DEF_ BO_  "GenMsgDelayTime" INT 0 1000;
BA_DEF_ BO_  "GenMsgCycleTime" INT 0 100000;
BA_DEF_ BO_  "GenMsgSendType" ENUM  "FixedPeriodic","Event","EnabledPeriodic","NotUsed","NotUsed","EventPeriodic","NotUsed","NotUsed","NoMsgSendType";
BA_DEF_ BO_  "FrameRouting" STRING ;
BA_DEF_ BO_  "TpTxIndex" INT 0 536870911;
BA_DEF_ BO_  "OvtpPushApplication" ENUM  "FALSE","TRUE";
BA_DEF_ BO_  "SCP_FreshnessValueLength" INT 0 512;
BA_DEF_ BO_  "SCP_FreshnessValueTxLength" INT 0 512;
BA_DEF_ BO_  "SCP_AuthInfoTxLength" INT 0 512;
BA_DEF_ BO_  "NmAsrMessage" ENUM  "No","Yes";
BA_DEF_ BO_  "DiagState" ENUM  "No","Yes";
BA_DEF_ BO_  "DiagRequest" ENUM  "No","Yes";
BA_DEF_ BO_  "DiagResponse" ENUM  "No","Yes";
BA_DEF_ BO_  "GenMsgILSupport" ENUM  "No","Yes";
BA_DEF_ SG_  "SystemSignalLongSymbol" STRING ;
BA_DEF_ BO_  "SystemMessageLongSymbol" STRING ;
BA_DEF_DEF_  "E2EDataId" 1;
BA_DEF_DEF_  "E2EDataLength" 0;
BA_DEF_DEF_  "E2EProfile" "";
BA_DEF_DEF_  "GenMsgRoutingTimeoutTime" 0;
BA_DEF_DEF_  "MessageGateway" "No";
BA_DEF_DEF_  "VFrameFormat" "StandardCAN";
BA_DEF_DEF_  "ECGUsedRxSignal" "No";
BA_DEF_DEF_  "ECGUsedTxSignal" "No";
BA_DEF_DEF_  "GenSigInactiveValue" 0;
BA_DEF_DEF_  "GenSigSendType" "NoSigSendType";
BA_DEF_DEF_  "NetworkInitialization" "Yes";
BA_DEF_DEF_  "GenSigStartValue" 0;
BA_DEF_DEF_  "GenMsgStartDelayTime" 0;
BA_DEF_DEF_  "WakeupSignal" "No";
BA_DEF_DEF_  "GenMsgNrOfRepetition" 1;
BA_DEF_DEF_  "GenMsgDelayTime" 20;
BA_DEF_DEF_  "GenMsgCycleTime" 0;
BA_DEF_DEF_  "GenMsgSendType" "NoMsgSendType";
BA_DEF_DEF_  "FrameRouting" "";
BA_DEF_DEF_  "TpTxIndex" 0;
BA_DEF_DEF_  "OvtpPushApplication" "FALSE";
BA_DEF_DEF_  "SCP_FreshnessValueLength" 64;
BA_DEF_DEF_  "SCP_FreshnessValueTxLength" 11;
BA_DEF_DEF_  "SCP_AuthInfoTxLength" 53;
BA_DEF_DEF_  "NmAsrMessage" "No";
BA_DEF_DEF_  "DiagState" "No";
BA_DEF_DEF_  "DiagRequest" "No";
BA_DEF_DEF_  "DiagResponse" "No";
BA_DEF_DEF_  "GenMsgILSupport" "Yes";
BA_DEF_DEF_  "SystemSignalLongSymbol" "";
BA_DEF_DEF_  "SystemMessageLongSymbol" "";
BA_ "FrameRouting" BO_ 995 "FD1_CAN,0x3E3;";
BA_ "GenMsgSendType" BO_ 996 5;
BA_ "GenMsgCycleTime" BO_ 996 1000;
BA_ "FrameRouting" BO_ 997 "FD3_CAN,0x3E5;FD1_CAN,0x3E5;";
BA_ "FrameRouting" BO_ 998 "FD3_CAN,0x3E6;";
BA_ "FrameRouting" BO_ 999 "MS1_CAN,0x3E7;";
BA_ "GenMsgSendType" BO_ 1000 5;
BA_ "GenMsgCycleTime" BO_ 1000 1000;
BA_ "FrameRouting" BO_ 1001 "HS2_CAN,0x3E9;";
BA_ "GenMsgSendType" BO_ 1002 5;
BA_ "GenMsgCycleTime" BO_ 1002 1000;
BA_ "FrameRouting" BO_ 1004 "FD1_CAN,0x3EB;";
BA_ "FrameRouting" BO_ 1006 "FD3_CAN,0x3EE;FD1_CAN,0x3EE;";
BA_ "GenMsgSendType" BO_ 1007 5;
BA_ "GenMsgCycleTime" BO_ 1007 1000;
BA_ "GenMsgSendType" BO_ 1008 5;
BA_ "GenMsgCycleTime" BO_ 1008 1000;
BA_ "GenMsgSendType" BO_ 1009 5;
BA_ "GenMsgCycleTime" BO_ 1009 1000;
BA_ "FrameRouting" BO_ 1011 "FD1_CAN,0x3F3;";
BA_ "FrameRouting" BO_ 1012 "FD1_CAN,0x3F4;";
BA_ "FrameRouting" BO_ 1013 "FD1_CAN,0x3F5;";
BA_ "GenMsgSendType" BO_ 1014 5;
BA_ "GenMsgCycleTime" BO_ 1014 1000;
BA_ "FrameRouting" BO_ 1015 "MS1_CAN,0x3F7;";
BA_ "FrameRouting" BO_ 1016 "FD1_CAN,0x3F8;";
BA_ "FrameRouting" BO_ 1018 "MS2_CAN,0x3FA;";
BA_ "GenMsgSendType" BO_ 1019 5;
BA_ "GenMsgCycleTime" BO_ 1019 1000;
BA_ "GenMsgSendType" BO_ 1020 5;
BA_ "GenMsgCycleTime" BO_ 1020 1000;
BA_ "FrameRouting" BO_ 1021 "MS2_CAN,0x3FD;";
BA_ "FrameRouting" BO_ 1022 "MS2_CAN,0x3FE;";
BA_ "FrameRouting" BO_ 1034 "FD1_CAN,0x40A;";
BA_ "FrameRouting" BO_ 1036 "HS2_CAN,0x40C;";
BA_ "FrameRouting" BO_ 1040 "FD1_CAN,0x410;";
BA_ "FrameRouting" BO_ 1041 "HS2_CAN,0x411;";
BA_ "FrameRouting" BO_ 1042 "FD1_CAN,0x412;";
BA_ "FrameRouting" BO_ 1043 "FD1_CAN,0x413;";
BA_ "FrameRouting" BO_ 1045 "FD1_CAN,0x415;";
BA_ "FrameRouting" BO_ 1046 "FD1_CAN,0x416;";
BA_ "FrameRouting" BO_ 1047 "FD3_CAN,0x417;FD1_CAN,0x417;";
BA_ "GenMsgSendType" BO_ 1049 5;
BA_ "GenMsgCycleTime" BO_ 1049 1000;
BA_ "FrameRouting" BO_ 1050 "MS1_CAN,0x41A;";
BA_ "FrameRouting" BO_ 1052 "FD1_CAN,0x41C;";
BA_ "FrameRouting" BO_ 1054 "FD1_CAN,0x41E;";
BA_ "FrameRouting" BO_ 1055 "FD1_CAN,0x41F;";
BA_ "FrameRouting" BO_ 1056 "FD1_CAN,0x420;";
BA_ "FrameRouting" BO_ 1057 "FD1_CAN,0x421;";
BA_ "FrameRouting" BO_ 1059 "FD1_CAN,0x42C;";
BA_ "FrameRouting" BO_ 1060 "FD1_CAN,0x424;";
BA_ "GenMsgSendType" BO_ 1068 5;
BA_ "GenMsgDelayTime" BO_ 1068 10;
BA_ "GenMsgCycleTime" BO_ 1068 250;
BA_ "FrameRouting" BO_ 1069 "FD1_CAN,0x42D;";
BA_ "FrameRouting" BO_ 1071 "FD1_CAN,0x42F;";
BA_ "GenMsgSendType" BO_ 1072 5;
BA_ "GenMsgCycleTime" BO_ 1072 100;
BA_ "GenMsgSendType" BO_ 1076 5;
BA_ "GenMsgCycleTime" BO_ 1076 100;
BA_ "FrameRouting" BO_ 1084 "FD1_CAN,0x43C;";
BA_ "FrameRouting" BO_ 1086 "FD1_CAN,0x43E;";
BA_ "FrameRouting" BO_ 1087 "FD1_CAN,0x43F;";
BA_ "FrameRouting" BO_ 1088 "FD1_CAN,0x440;";
BA_ "FrameRouting" BO_ 1090 "FD1_CAN,0x442;";
BA_ "GenMsgSendType" BO_ 1091 5;
BA_ "GenMsgCycleTime" BO_ 1091 1000;
BA_ "FrameRouting" BO_ 1092 "HS2_CAN,0x444;";
BA_ "GenMsgSendType" BO_ 1093 0;
BA_ "GenMsgCycleTime" BO_ 1093 100;
BA_ "FrameRouting" BO_ 1095 "FD1_CAN,0x447;";
BA_ "FrameRouting" BO_ 1098 "FD1_CAN,0x44A;";
BA_ "FrameRouting" BO_ 1100 "FD1_CAN,0x44C;";
BA_ "FrameRouting" BO_ 1101 "FD1_CAN,0x44D;";
BA_ "FrameRouting" BO_ 1102 "FD1_CAN,0x44E;";
BA_ "FrameRouting" BO_ 1104 "FD3_CAN,0x450;";
BA_ "FrameRouting" BO_ 1105 "FD1_CAN,0x451;FD3_CAN,0x451;";
BA_ "FrameRouting" BO_ 1106 "HS2_CAN,0x452;FD1_CAN,0x452;";
BA_ "GenMsgSendType" BO_ 1109 5;
BA_ "GenMsgCycleTime" BO_ 1109 100;
BA_ "FrameRouting" BO_ 1112 "HS2_CAN,0x458;";
BA_ "FrameRouting" BO_ 1113 "FD3_CAN,0x459;FD1_CAN,0x459;";
BA_ "GenMsgSendType" BO_ 1114 5;
BA_ "GenMsgCycleTime" BO_ 1114 1000;
BA_ "GenMsgSendType" BO_ 1115 5;
BA_ "GenMsgCycleTime" BO_ 1115 1000;
BA_ "GenMsgSendType" BO_ 1116 5;
BA_ "GenMsgCycleTime" BO_ 1116 1000;
BA_ "GenMsgSendType" BO_ 1118 1;
BA_ "GenMsgSendType" BO_ 1119 1;
BA_ "FrameRouting" BO_ 1120 "HS2_CAN,0x460;";
BA_ "FrameRouting" BO_ 1121 "HS2_CAN,0x461;";
BA_ "GenMsgSendType" BO_ 1122 1;
BA_ "GenMsgSendType" BO_ 1123 1;
BA_ "GenMsgSendType" BO_ 1124 1;
BA_ "FrameRouting" BO_ 1128 "HS2_CAN,0x45E;";
BA_ "FrameRouting" BO_ 1134 "FD2_CAN,0x46E;";
BA_ "FrameRouting" BO_ 1137 "FD1_CAN,0x471;";
BA_ "FrameRouting" BO_ 1138 "FD1_CAN,0x472;";
BA_ "FrameRouting" BO_ 1139 "FD1_CAN,0x473;";
BA_ "FrameRouting" BO_ 1140 "FD1_CAN,0x474;";
BA_ "FrameRouting" BO_ 1141 "FD1_CAN,0x475;";
BA_ "FrameRouting" BO_ 1142 "FD1_CAN,0x476;";
BA_ "FrameRouting" BO_ 1143 "FD1_CAN,0x477;";
BA_ "FrameRouting" BO_ 1144 "FD1_CAN,0x478;";
BA_ "FrameRouting" BO_ 1145 "FD1_CAN,0x352;";
BA_ "GenMsgSendType" BO_ 1146 0;
BA_ "GenMsgCycleTime" BO_ 1146 50;
BA_ "GenSigStartValue" SG_ 995 PersIndexBcm_D_Actl 4;
BA_ "GenSigSendType" SG_ 996 FeatConfigHudActl 3;
BA_ "GenSigSendType" SG_ 996 FeatNoHudActl 3;
BA_ "GenSigSendType" SG_ 996 PersIndexHud_D_Actl 3;
BA_ "GenSigStartValue" SG_ 997 PersTurnSglView_D_Stat 3;
BA_ "GenSigStartValue" SG_ 997 PersIndexCcm_D_Actl 4;
BA_ "GenSigStartValue" SG_ 998 PersIndexSccm_D_Actl 4;
BA_ "GenSigStartValue" SG_ 999 PersIndexFcim_D_Actl 4;
BA_ "GenSigSendType" SG_ 1000 AHU_Shaker_St 3;
BA_ "GenSigSendType" SG_ 1000 MyKeyVolumeLimitMode 3;
BA_ "GenSigSendType" SG_ 1000 ACM_BeltminderAudioSt 3;
BA_ "GenSigSendType" SG_ 1000 MyKeyVolumeLimitUp 3;
BA_ "GenSigSendType" SG_ 1000 ThermalReduction_St 3;
BA_ "GenSigSendType" SG_ 1000 AHU_Bezel_Diag_St 3;
BA_ "GenSigSendType" SG_ 1002 CntrStkKeycodeActl 3;
BA_ "GenSigSendType" SG_ 1002 FeatConfigApimActl 3;
BA_ "GenSigSendType" SG_ 1002 FeatNoApimActl 3;
BA_ "WakeupSignal" SG_ 1002 CntrStk_D_RqRecall 1;
BA_ "GenSigSendType" SG_ 1002 CntrStk_D_RqRecall 3;
BA_ "GenSigStartValue" SG_ 1002 CntrStk_D_RqAssoc 3;
BA_ "GenSigSendType" SG_ 1002 CntrStk_D_RqAssoc 3;
BA_ "GenSigStartValue" SG_ 1002 PersIndexApim_D_Actl 4;
BA_ "GenSigSendType" SG_ 1002 PersIndexApim_D_Actl 3;
BA_ "GenSigStartValue" SG_ 1004 PersNo_D_Actl 4;
BA_ "GenSigStartValue" SG_ 1004 PersNoPos_D_Actl 4;
BA_ "GenSigStartValue" SG_ 1004 PersConflict_D_Actl 1;
BA_ "GenSigStartValue" SG_ 1006 PersIndexIpmb_D_Actl 4;
BA_ "GenSigSendType" SG_ 1007 FeatConfigIpc2Actl 3;
BA_ "GenSigSendType" SG_ 1007 FeatNoIpc2Actl 3;
BA_ "GenSigStartValue" SG_ 1007 PersIndexIpc2_D_Actl 4;
BA_ "GenSigSendType" SG_ 1007 PersIndexIpc2_D_Actl 3;
BA_ "GenSigSendType" SG_ 1008 RearMnuCtlLck_B_Rq 3;
BA_ "GenSigSendType" SG_ 1008 CPM_MediaPlayerSrc_St 3;
BA_ "GenSigSendType" SG_ 1008 SelectedNumOfPresets 3;
BA_ "GenSigSendType" SG_ 1008 MultimediaSrc_D_Stat 3;
BA_ "GenSigSendType" SG_ 1008 MultimediaShuf_D_Stat 3;
BA_ "GenSigSendType" SG_ 1008 MultimediaRepeat_D_Stat 3;
BA_ "GenSigSendType" SG_ 1009 APIM_ActiveTrackNum_St 3;
BA_ "GenSigSendType" SG_ 1009 APIM_NumberofTracks_St 3;
BA_ "GenSigSendType" SG_ 1009 TrlrAidCancl_B_Rq 3;
BA_ "GenSigSendType" SG_ 1009 AutoHoldSwtch_D_Stat3 3;
BA_ "GenSigSendType" SG_ 1009 RearAudioCtlLck_D_Rq 3;
BA_ "GenSigSendType" SG_ 1009 TrlrAidSetup_D_Stat 3;
BA_ "GenSigSendType" SG_ 1009 ValetMode_D_Stat 3;
BA_ "GenSigStartValue" SG_ 1009 CenterStackRing_D_Actl 2;
BA_ "GenSigSendType" SG_ 1009 CenterStackRing_D_Actl 3;
BA_ "GenSigSendType" SG_ 1009 ChrgCordUnlock_B_Rq 3;
BA_ "GenSigSendType" SG_ 1009 TrlrTrgtAcquire_D_Rq 3;
BA_ "GenSigStartValue" SG_ 1011 ChrgLocLattFrct_An_Uns 1048575;
BA_ "GenSigStartValue" SG_ 1011 ChrgLocLongFrct_An_Uns 1048575;
BA_ "GenSigStartValue" SG_ 1012 ChrgLocLattFrct_An_Sav 1048575;
BA_ "GenSigStartValue" SG_ 1012 ChrgLocLongFrct_An_Sav 1048575;
BA_ "GenSigStartValue" SG_ 1014 WrlssAcsyChrgr_D_Stat 1;
BA_ "GenSigSendType" SG_ 1014 WrlssAcsyChrgr_D_Stat 3;
BA_ "GenSigStartValue" SG_ 1014 WrlssAcsyChrg_Pc_Actl 126;
BA_ "GenSigStartValue" SG_ 1016 ChrgGoTHr_T_Stat 30;
BA_ "GenSigStartValue" SG_ 1018 TrlrTireILF_P_Actl 65533;
BA_ "GenSigStartValue" SG_ 1018 TrlrTireILM_P_Actl 65533;
BA_ "GenSigStartValue" SG_ 1018 TrlrTireILR_P_Actl 65533;
BA_ "GenSigSendType" SG_ 1019 FeatConfigIpcActl 3;
BA_ "GenSigSendType" SG_ 1019 FeatNoIpcActl 3;
BA_ "GenSigStartValue" SG_ 1019 PersIndexIpc_D_Actl 4;
BA_ "GenSigSendType" SG_ 1019 PersIndexIpc_D_Actl 3;
BA_ "GenSigSendType" SG_ 1020 CtrStkFeat2ConfigActl 3;
BA_ "GenSigSendType" SG_ 1020 CtrStkFeat2NoActl 3;
BA_ "GenSigSendType" SG_ 1020 CtrStkDsplyOp2_D_Rq 3;
BA_ "GenSigStartValue" SG_ 1020 CtrStkPersIndex2_D_Actl 4;
BA_ "GenSigSendType" SG_ 1020 CtrStkPersIndex2_D_Actl 3;
BA_ "GenSigStartValue" SG_ 1021 TrlrTireIRF_P_Actl 65533;
BA_ "GenSigStartValue" SG_ 1021 TrlrTireIRM_P_Actl 65533;
BA_ "GenSigStartValue" SG_ 1021 TrlrTireIRR_P_Actl 65533;
BA_ "GenSigStartValue" SG_ 1022 TrlrTireILF_T_Actl 253;
BA_ "GenSigStartValue" SG_ 1022 TrlrTireILM_T_Actl 253;
BA_ "GenSigStartValue" SG_ 1022 TrlrTireILR_T_Actl 253;
BA_ "GenSigStartValue" SG_ 1022 TrlrTireIRF_T_Actl 253;
BA_ "GenSigStartValue" SG_ 1022 TrlrTireIRM_T_Actl 253;
BA_ "GenSigStartValue" SG_ 1022 TrlrTireIRR_T_Actl 253;
BA_ "GenSigStartValue" SG_ 1040 BattTrac_I2_EstVsc 262142;
BA_ "GenSigStartValue" SG_ 1040 VehSimSnd_Pc_Rq 511;
BA_ "GenSigStartValue" SG_ 1040 RoadGrd_Pc_Est 1023;
BA_ "GenSigStartValue" SG_ 1043 IndvMdeSel_No_Rq 15;
BA_ "GenSigStartValue" SG_ 1043 IndvMdeSusp_No_Stat 15;
BA_ "GenSigStartValue" SG_ 1043 IndvMdeSte_No_Stat 15;
BA_ "GenSigStartValue" SG_ 1045 VehYawLin_W_Rq 4094;
BA_ "GenSigStartValue" SG_ 1045 VehYawNonLin_W_Rq 4094;
BA_ "GenSigStartValue" SG_ 1045 VehStab_D_Stat 14;
BA_ "GenSigStartValue" SG_ 1046 StabCtlBrk_B_Avail 1;
BA_ "GenSigStartValue" SG_ 1046 BpedMove_D_Actl 3;
BA_ "GenSigStartValue" SG_ 1046 HsaMde_D_Mem 1;
BA_ "GenSigStartValue" SG_ 1046 RearDiffLck_Tq2_RqMx 4094;
BA_ "GenSigStartValue" SG_ 1047 EsaOn_B_Stat 1;
BA_ "GenSigSendType" SG_ 1049 SelDrvMdePage_B_Stat 3;
BA_ "GenSigSendType" SG_ 1049 SelDrvMdeCnfm_D_Stat2 3;
BA_ "GenSigStartValue" SG_ 1049 SelDrvMde_D_RqDrv 31;
BA_ "GenSigSendType" SG_ 1049 SelDrvMde_D_RqDrv 3;
BA_ "GenSigStartValue" SG_ 1049 RearDiffLck_D_RqDrv3 2;
BA_ "GenSigSendType" SG_ 1049 RearDiffLck_D_RqDrv3 3;
BA_ "GenSigStartValue" SG_ 1049 FrontDiffLck_D_RqDrv3 2;
BA_ "GenSigSendType" SG_ 1049 FrontDiffLck_D_RqDrv3 3;
BA_ "GenSigSendType" SG_ 1049 CamraFrnt_B_RqMnu 3;
BA_ "GenSigSendType" SG_ 1049 TurnAsstSwtch_D_Stat 3;
BA_ "GenSigSendType" SG_ 1049 SelDrvMdeTxtRst_B_Rq2 3;
BA_ "GenSigSendType" SG_ 1049 DcacAllZoneBttn_B_Stat 3;
BA_ "GenSigSendType" SG_ 1049 DcacChime_D_Rq 3;
BA_ "GenSigSendType" SG_ 1049 PersTurnSglView_D_RqMnu 3;
BA_ "GenSigSendType" SG_ 1049 TrailCtlSwtch_B_Stat4 3;
BA_ "GenSigSendType" SG_ 1049 StabBarCnncButtn_D_Sta3 3;
BA_ "GenSigSendType" SG_ 1049 TrlrRngId_No_RqReset 3;
BA_ "ECGUsedRxSignal" SG_ 1049 TrlrRngId_No_RqReset 1;
BA_ "GenSigSendType" SG_ 1049 TrlrId_No_ActlMnu 3;
BA_ "GenSigSendType" SG_ 1049 LnchCtl_D_Rq2 3;
BA_ "GenSigSendType" SG_ 1049 DcacZone3PwBttn_B_Stat 3;
BA_ "GenSigSendType" SG_ 1049 DcacZone2PwBttn_B_Stat 3;
BA_ "GenSigSendType" SG_ 1049 DcacPwResetBtn2_B_Stat 3;
BA_ "GenSigSendType" SG_ 1049 DcacPwOffButtn2_B_Stat 3;
BA_ "GenSigSendType" SG_ 1049 DcacPwHiButtn2_B_Stat 3;
BA_ "GenSigSendType" SG_ 1049 DcacGfciTestBtn2_B_Stat 3;
BA_ "GenSigSendType" SG_ 1049 LnchCtl_N_Rq2 3;
BA_ "GenSigSendType" SG_ 1049 Fba_D_Rq 3;
BA_ "GenSigStartValue" SG_ 1049 ExtLghtAnmtn_D_Rq 1;
BA_ "GenSigSendType" SG_ 1049 ExtLghtAnmtn_D_Rq 3;
BA_ "ECGUsedRxSignal" SG_ 1049 ExtLghtAnmtn_D_Rq 1;
BA_ "GenSigSendType" SG_ 1049 DrvSlipCtlMde_B_Rq6 3;
BA_ "GenSigStartValue" SG_ 1050 Outside_Air_Temp_Stat 254;
BA_ "WakeupSignal" SG_ 1050 GlvBoxRleas_No_Actl 1;
BA_ "GenSigStartValue" SG_ 1050 CabnAmb_Te2_Actl 84;
BA_ "GenSigStartValue" SG_ 1050 RearDiffLck_D_RqDrv4 2;
BA_ "GenSigStartValue" SG_ 1050 CabnThrml_Te_Actl 40;
BA_ "GenSigStartValue" SG_ 1052 AwdCnnct_D_Stat 1;
BA_ "WakeupSignal" SG_ 1054 BrkMdeInhbt_B_RqDsply 1;
BA_ "GenSigStartValue" SG_ 1054 BrkLineLck_D_Stat 4;
BA_ "GenSigStartValue" SG_ 1054 SelDrvMdeAwd_D_Rq 31;
BA_ "GenSigStartValue" SG_ 1055 EcoCochA_Pc_Dsply 255;
BA_ "GenSigStartValue" SG_ 1055 EcoCochCrus_Pc_Dsply 255;
BA_ "GenSigStartValue" SG_ 1055 EcoCochDecel_Pc_Dsply 255;
BA_ "GenSigStartValue" SG_ 1055 EcoCochIdlFuel_Pc_Dsply 255;
BA_ "GenSigStartValue" SG_ 1055 EcoCochShif_Pc_Dsply 255;
BA_ "GenSigStartValue" SG_ 1055 EcoCochInst_Pc_Dsply 100;
BA_ "GenSigStartValue" SG_ 1056 VehVActlBrk_No_Corr 254;
BA_ "GenSigStartValue" SG_ 1056 AwdMde_D_RqBrk 5;
BA_ "GenSigStartValue" SG_ 1056 ActvDrvMde_D2_Stat 31;
BA_ "GenSigStartValue" SG_ 1056 SelDrvMde_D2_Rq 31;
BA_ "GenSigStartValue" SG_ 1057 FohEng_D_Rq 2;
BA_ "GenSigStartValue" SG_ 1057 FUEL_ALCOHOL_PERCNT 255;
BA_ "WakeupSignal" SG_ 1059 PwSysULoFalt_D_Stat 1;
BA_ "WakeupSignal" SG_ 1059 Shed_Feature_Group_ID 1;
BA_ "WakeupSignal" SG_ 1059 Shed_Level_Req 1;
BA_ "GenSigStartValue" SG_ 1060 RearDiffOil_Te_Actl 77;
BA_ "GenSigStartValue" SG_ 1060 EngExhMdeQuiet_D_Stat 2;
BA_ "GenSigSendType" SG_ 1068 TrlrAidMsgTxt_D_Rq 3;
BA_ "ECGUsedTxSignal" SG_ 1068 TrlrAidMsgTxt_D_Rq 1;
BA_ "WakeupSignal" SG_ 1069 ReFuelSysStat_D_Dsply 1;
BA_ "GenSigStartValue" SG_ 1071 CluPdlPosPcMeas_D_Qf 1;
BA_ "GenSigStartValue" SG_ 1071 EngMnfld3_P_Actl 254;
BA_ "WakeupSignal" SG_ 1072 ePRNDL_MODE 1;
BA_ "GenSigSendType" SG_ 1072 ePRNDL_MODE 3;
BA_ "GenSigSendType" SG_ 1072 NtrlTowMdeEnbl_B_RqDrv 3;
BA_ "GenSigSendType" SG_ 1072 LscmbbStat_B_Actl 3;
BA_ "ECGUsedRxSignal" SG_ 1072 LscmbbStat_B_Actl 1;
BA_ "GenSigSendType" SG_ 1072 EngIdlShutDown_B_RqDrv 3;
BA_ "GenSigSendType" SG_ 1072 ManRgen_D_Rq 3;
BA_ "GenSigSendType" SG_ 1072 MetricActv_B_Actl 3;
BA_ "ECGUsedRxSignal" SG_ 1072 MetricActv_B_Actl 1;
BA_ "GenSigSendType" SG_ 1072 AccDeny_B_RqIpc 3;
BA_ "ECGUsedRxSignal" SG_ 1072 OdometerMasterValue 1;
BA_ "GenSigSendType" SG_ 1072 DrvSlipCtlMde_D_Rq 3;
BA_ "ECGUsedRxSignal" SG_ 1072 DrvSlipCtlMde_D_Rq 1;
BA_ "GenSigSendType" SG_ 1072 DrvSlipCtlMde_B_Rq2 3;
BA_ "GenSigStartValue" SG_ 1072 AccEnbl_B_RqDrv 1;
BA_ "GenSigSendType" SG_ 1072 AccEnbl_B_RqDrv 3;
BA_ "GenSigSendType" SG_ 1072 Fda_B_Stat 3;
BA_ "GenSigSendType" SG_ 1072 TRAILER_BRAKE_CONFIG 3;
BA_ "GenSigSendType" SG_ 1072 MetricActvTe_B_Actl 3;
BA_ "WakeupSignal" SG_ 1072 Power_Liftgate_Mode_Cmd 1;
BA_ "GenSigSendType" SG_ 1072 Power_Liftgate_Mode_Cmd 3;
BA_ "GenSigSendType" SG_ 1072 KeyTypeChngMykey_D_Rq 3;
BA_ "GenSigSendType" SG_ 1072 HaDsplyCpblty_B_Stat 3;
BA_ "GenSigSendType" SG_ 1072 EngOilLife_B_RqReset 3;
BA_ "GenSigSendType" SG_ 1072 FrostWarn_D_Stat 3;
BA_ "GenSigSendType" SG_ 1072 StopStrtDrvMde_D_RqMnu 3;
BA_ "GenSigSendType" SG_ 1072 DrvPerfMde_D_Rq 3;
BA_ "GenSigSendType" SG_ 1072 ReducedGuard_D_Rq 3;
BA_ "GenSigSendType" SG_ 1072 ParkDetect_Stat 3;
BA_ "GenSigStartValue" SG_ 1072 HsaMde_D_Rq 1;
BA_ "GenSigSendType" SG_ 1072 HsaMde_D_Rq 3;
BA_ "GenSigSendType" SG_ 1072 BulbChkActv_B_Stat 3;
BA_ "GenSigSendType" SG_ 1072 TRLR_SWAY_CONFIG_CMD 3;
BA_ "GenSigSendType" SG_ 1072 TrlrBrkMde_D_Rq 3;
BA_ "GenSigSendType" SG_ 1072 PtDrvMde_D_Rq 3;
BA_ "GenSigSendType" SG_ 1072 PrkLckCtlEnbl_D_RqIpc 3;
BA_ "ECGUsedRxSignal" SG_ 1076 FuelLvl_Pc_Dsply 1;
BA_ "GenSigSendType" SG_ 1076 OdoTripRx_B_Actl 3;
BA_ "GenSigSendType" SG_ 1076 FogLghtRearButtn_B_Rq 3;
BA_ "GenSigSendType" SG_ 1076 FogLghtFrontButtn_B_Rq 3;
BA_ "GenSigSendType" SG_ 1076 TirePReset_B_Rq 3;
BA_ "GenSigSendType" SG_ 1076 DieslFuelBio_B_ActlDrv 3;
BA_ "GenSigSendType" SG_ 1076 HILL_DESC_SW 3;
BA_ "GenSigSendType" SG_ 1076 AutoRgen_D_Rq 3;
BA_ "GenSigSendType" SG_ 1076 FUEL_SENSOR_NUM 3;
BA_ "GenSigStartValue" SG_ 1076 W2S_LAMP_OK 1;
BA_ "GenSigSendType" SG_ 1076 W2S_LAMP_OK 3;
BA_ "GenSigSendType" SG_ 1076 DrvSlipCtlMde_B_RqMyKey 3;
BA_ "GenSigSendType" SG_ 1076 FuelSecndActv_B_Actl 3;
BA_ "GenSigStartValue" SG_ 1076 Veh_V_CompLimMx 4093;
BA_ "GenSigSendType" SG_ 1076 FuelLvlWarn_D_Actl 3;
BA_ "ECGUsedRxSignal" SG_ 1076 FuelLvlWarn_D_Actl 1;
BA_ "GenSigStartValue" SG_ 1084 BattULo2_Te_Actl 127;
BA_ "GenSigStartValue" SG_ 1084 BattULoChrg_U_RqMx 34;
BA_ "GenSigStartValue" SG_ 1084 BattULoChrg_URate_RqMx 5;
BA_ "GenSigStartValue" SG_ 1086 EngIpcDsplyCht_Te_Actl 75;
BA_ "GenSigStartValue" SG_ 1087 CrnkInhbtActv_B_Stat 1;
BA_ "WakeupSignal" SG_ 1088 ChrgStat_D2_Dsply 1;
BA_ "GenSigStartValue" SG_ 1088 BattDcChrgRms_I_Lim 32766;
BA_ "GenSigStartValue" SG_ 1088 TrlrRng_L_Dsply 8190;
BA_ "GenSigStartValue" SG_ 1088 HvacPrecond_Te_Rq 2;
BA_ "WakeupSignal" SG_ 1088 HvacPrecondMode2_D_Rq 1;
BA_ "WakeupSignal" SG_ 1088 HvacPrecondBlwr2_D_Rq 1;
BA_ "GenSigStartValue" SG_ 1090 Inv1Ain_I_ActlMntr 32765;
BA_ "GenSigStartValue" SG_ 1090 VehElRnge_L_Dsply 4093;
BA_ "GenSigSendType" SG_ 1091 WakeAlarm2_B_Typ 3;
BA_ "GenSigSendType" SG_ 1091 TrlrAlarmSpprt_D_Stat 3;
BA_ "GenSigStartValue" SG_ 1091 WakeAlarm2_T_Rq 32767;
BA_ "GenSigSendType" SG_ 1091 WakeAlarm2_T_Rq 3;
BA_ "GenSigStartValue" SG_ 1092 BattTracInsltn_R_Actl 255;
BA_ "GenSigStartValue" SG_ 1092 BattTracMnCell_Te_Actl 254;
BA_ "GenSigStartValue" SG_ 1092 BattTracMxCell_Te_Actl 254;
BA_ "WakeupSignal" SG_ 1095 HeadLghtOn_D_Rq 1;
BA_ "GenSigStartValue" SG_ 1095 HeadLghtOn_D_Rq 1;
BA_ "GenSigStartValue" SG_ 1098 EcoCochInstTot_Pc_Dsply 255;
BA_ "ECGUsedRxSignal" SG_ 1098 DcacPwOn_D_Stat 1;
BA_ "GenSigStartValue" SG_ 1100 GrossTrainWeight_M_Est 254;
BA_ "GenSigStartValue" SG_ 1100 RearDiffSumpOil_Te_Est 254;
BA_ "GenSigStartValue" SG_ 1100 WakeAlarm1_T_Rq 32767;
BA_ "WakeupSignal" SG_ 1100 WakeAlarm1_B_Typ 1;
BA_ "GenSigStartValue" SG_ 1102 SelDrvMdePos02_D_Stat 31;
BA_ "GenSigStartValue" SG_ 1102 SelDrvMdePos01_D_Stat 31;
BA_ "GenSigStartValue" SG_ 1102 SelDrvMdePos03_D_Stat 31;
BA_ "GenSigStartValue" SG_ 1102 SelDrvMdePos05_D_Stat 31;
BA_ "GenSigStartValue" SG_ 1102 SelDrvMdePos04_D_Stat 31;
BA_ "GenSigStartValue" SG_ 1102 SelDrvMdePos06_D_Stat 31;
BA_ "GenSigStartValue" SG_ 1102 SelDrvMdePos12_D_Stat 31;
BA_ "GenSigStartValue" SG_ 1102 SelDrvMdePos07_D_Stat 31;
BA_ "GenSigStartValue" SG_ 1102 SelDrvMdePos11_D_Stat 31;
BA_ "GenSigStartValue" SG_ 1102 SelDrvMdePos09_D_Stat 31;
BA_ "GenSigStartValue" SG_ 1102 SelDrvMdePos10_D_Stat 31;
BA_ "GenSigStartValue" SG_ 1102 SelDrvMdePos08_D_Stat 31;
BA_ "WakeupSignal" SG_ 1105 BrkDecel_B_RqRba 1;
BA_ "GenSigStartValue" SG_ 1105 Rba_D_Stat 1;
BA_ "WakeupSignal" SG_ 1105 BrkEnbl_B_RqRba 1;
BA_ "GenSigSendType" SG_ 1109 PassRstrnIndB_Stat 3;
BA_ "GenSigSendType" SG_ 1109 eCallConfirmation 3;
BA_ "GenSigSendType" SG_ 1109 PassRstrnIndA_D_Stat 3;
BA_ "GenSigStartValue" SG_ 1109 DcacPwOn_D_RqMnu 2;
BA_ "GenSigSendType" SG_ 1109 DcacPwOn_D_RqMnu 3;
BA_ "GenSigStartValue" SG_ 1112 BattTrac2_E_Max 4094;
BA_ "GenSigStartValue" SG_ 1112 BattTracDelta_Te_Actl 254;
BA_ "GenSigStartValue" SG_ 1113 HitchToVehAxle_L_Calc 255;
BA_ "GenSigSendType" SG_ 1114 TrailCtlSwtch_B_Stat2 3;
BA_ "GenSigSendType" SG_ 1114 TrlBrkInitOut_D_Rq 3;
BA_ "GenSigSendType" SG_ 1115 HudPersChng_D_Stat 3;
BA_ "ECGUsedRxSignal" SG_ 1115 HudPersChng_D_Stat 1;
BA_ "GenSigSendType" SG_ 1115 HUD_BTIncomingCall_Rq 3;
BA_ "GenSigSendType" SG_ 1115 HUD_TextMessage_Rq 3;
BA_ "GenSigSendType" SG_ 1115 HUD_BTEndTelService_Rq 3;
BA_ "WakeupSignal" SG_ 1115 HudPersFeatCnt_No_Actl 1;
BA_ "GenSigSendType" SG_ 1115 HudPersFeatCnt_No_Actl 3;
BA_ "ECGUsedRxSignal" SG_ 1115 HudPersFeatCnt_No_Actl 1;
BA_ "GenSigSendType" SG_ 1115 HUD_BTInCallOptions_Rq 3;
BA_ "GenSigSendType" SG_ 1115 HudPersFeat_No_Actl 3;
BA_ "ECGUsedRxSignal" SG_ 1115 HudPersFeat_No_Actl 1;
BA_ "GenSigSendType" SG_ 1115 HudPersFeatVal_No_Actl 3;
BA_ "ECGUsedRxSignal" SG_ 1115 HudPersFeatVal_No_Actl 1;
BA_ "GenSigSendType" SG_ 1115 HudPersSrvc_D_Res 3;
BA_ "ECGUsedRxSignal" SG_ 1115 HudPersSrvc_D_Res 1;
BA_ "WakeupSignal" SG_ 1115 HudPersSrvcId_No_Actl 1;
BA_ "GenSigSendType" SG_ 1115 HudPersSrvcId_No_Actl 3;
BA_ "ECGUsedRxSignal" SG_ 1115 HudPersSrvcId_No_Actl 1;
BA_ "GenSigSendType" SG_ 1116 TrlrRvrseCancl_B_Rq 3;
BA_ "GenSigSendType" SG_ 1116 TrlrAidSetup_D2_Rq 3;
BA_ "GenSigSendType" SG_ 1116 TrlrAidEnbl_D2_Rq 3;
BA_ "GenSigSendType" SG_ 1116 TrlrAnOffstDir_D_Mem 3;
BA_ "GenSigSendType" SG_ 1116 TlightTest_D_Mnu 3;
BA_ "ECGUsedRxSignal" SG_ 1116 TlightTest_D_Mnu 1;
BA_ "GenSigSendType" SG_ 1116 TrlrIdType_D_Stat 3;
BA_ "GenSigSendType" SG_ 1118 LocationServices_1 1;
BA_ "ECGUsedRxSignal" SG_ 1118 LocationServices_1 1;
BA_ "GenSigSendType" SG_ 1119 LocationServices_2 1;
BA_ "ECGUsedRxSignal" SG_ 1119 LocationServices_2 1;
BA_ "GenSigStartValue" SG_ 1120 AwdLck_D_RqDrv 2;
BA_ "GenSigStartValue" SG_ 1120 RearDiffLck_D_RqDrv 2;
BA_ "GenSigStartValue" SG_ 1120 AwdMde_D_RqDrv 5;
BA_ "GenSigStartValue" SG_ 1120 FrontDiffLck_D_RqDrv 2;
BA_ "GenSigStartValue" SG_ 1121 OffRdSwtch_D_RqMnu 2;
BA_ "ECGUsedRxSignal" SG_ 1122 GPS_Latitude_Degrees 1;
BA_ "GenSigSendType" SG_ 1122 GpsHsphLongEast_D_Actl 1;
BA_ "ECGUsedRxSignal" SG_ 1122 GpsHsphLongEast_D_Actl 1;
BA_ "ECGUsedRxSignal" SG_ 1122 GPS_Latitude_Minutes 1;
BA_ "ECGUsedRxSignal" SG_ 1122 GPS_Latitude_Min_dec 1;
BA_ "ECGUsedRxSignal" SG_ 1122 GpsHsphLattSth_D_Actl 1;
BA_ "ECGUsedRxSignal" SG_ 1122 GPS_Longitude_Degrees 1;
BA_ "ECGUsedRxSignal" SG_ 1122 GPS_Longitude_Minutes 1;
BA_ "ECGUsedRxSignal" SG_ 1122 GPS_Longitude_Min_dec 1;
BA_ "ECGUsedRxSignal" SG_ 1123 Gps_B_Falt 1;
BA_ "ECGUsedRxSignal" SG_ 1123 GPS_UTC_hours 1;
BA_ "ECGUsedRxSignal" SG_ 1123 GPS_UTC_minutes 1;
BA_ "ECGUsedRxSignal" SG_ 1123 GPS_UTC_seconds 1;
BA_ "ECGUsedRxSignal" SG_ 1123 GPS_Compass_direction 1;
BA_ "GenSigStartValue" SG_ 1123 GpsUtcDay_No_Actl 1;
BA_ "ECGUsedRxSignal" SG_ 1123 GpsUtcDay_No_Actl 1;
BA_ "GenSigSendType" SG_ 1123 GPS_Actual_vs_Infer_pos 1;
BA_ "ECGUsedRxSignal" SG_ 1123 GPS_Actual_vs_Infer_pos 1;
BA_ "GenSigStartValue" SG_ 1123 GpsUtcMnth_No_Actl 1;
BA_ "ECGUsedRxSignal" SG_ 1123 GpsUtcMnth_No_Actl 1;
BA_ "ECGUsedRxSignal" SG_ 1123 GpsUtcYr_No_Actl 1;
BA_ "ECGUsedRxSignal" SG_ 1124 GPS_dimension 1;
BA_ "ECGUsedRxSignal" SG_ 1124 GPS_MSL_altitude 1;
BA_ "ECGUsedRxSignal" SG_ 1124 GPS_Heading 1;
BA_ "ECGUsedRxSignal" SG_ 1124 GPS_Speed 1;
BA_ "GenSigSendType" SG_ 1124 GPS_Vdop 1;
BA_ "GenSigStartValue" SG_ 1128 ChrgrPncEnbl_D_Stat 3;
BA_ "GenSigStartValue" SG_ 1134 AuxAirCond_B_Rq 1;
BA_ "GenSigStartValue" SG_ 1137 RngPerChrgAvg_L_Dsply 4093;
BA_ "GenSigStartValue" SG_ 1137 RngPerChrgLbl_L_Dsply 4093;
BA_ "GenSigStartValue" SG_ 1137 RngImpctDrv_Pc_Dsply 1022;
BA_ "GenSigStartValue" SG_ 1137 RngImpctClim_Pc_Dsply 1022;
BA_ "GenSigStartValue" SG_ 1137 RngImpctExt_Pc_Dsply 1022;
BA_ "GenSigStartValue" SG_ 1137 RngImpctTot_Pc_Dsply 1022;
BA_ "GenSigStartValue" SG_ 1138 ActChrgEndDay_No_Actl 1;
BA_ "GenSigStartValue" SG_ 1138 ActChrgEndMnth_No_Actl 1;
BA_ "GenSigStartValue" SG_ 1139 ActChrgStrtDay_No_Actl 1;
BA_ "GenSigStartValue" SG_ 1139 ActChrgStrMnth_No_Actl 1;
BA_ "GenSigStartValue" SG_ 1140 RgenEvntLvl_Pc_Dsply 1022;
BA_ "GenSigStartValue" SG_ 1141 WhlPwFront_Pc_Dsply 511;
BA_ "GenSigStartValue" SG_ 1141 WhlPwRear_Pc_Dsply 511;
BA_ "GenSigStartValue" SG_ 1141 MtrTrac2_Tq_Actl 4095;
BA_ "WakeupSignal" SG_ 1141 PtRmtRprt_D_Rq 1;
BA_ "GenSigStartValue" SG_ 1143 AirCondFluidLo_P_Actl 254;
BA_ "GenSigStartValue" SG_ 1143 ConsTipTot_Pc_Dsply 1022;
BA_ "GenSigStartValue" SG_ 1144 WakeAlarm0_T_Rq 32767;
BA_ "WakeupSignal" SG_ 1144 HeatCoreSovRear_B_Rq 1;
BA_ "WakeupSignal" SG_ 1144 CabnEvapSovRear_B_Rq 1;
BA_ "WakeupSignal" SG_ 1144 CabnEvapSovFront_B_Rq 1;
BA_ "WakeupSignal" SG_ 1144 BattChlrSov_B_Rq 1;
BA_ "GenSigStartValue" SG_ 1144 BattChrgInhbt_D2_Rq 1;
BA_ "GenSigStartValue" SG_ 1145 VehElRngeNut_L2_Dsply 8190;
BA_ "GenSigStartValue" SG_ 1146 TrlrAidCtl_U_RqDrv 4093;
VAL_ 995 KeyAssocCmplt_B_Rq 0 "No" 1 "Yes" ;
VAL_ 995 FobAssocChime_B_Rq 0 "Off" 1 "On" ;
VAL_ 995 PersIndexBcm_D_Actl 0 "PERS_1" 1 "PERS_2" 2 "PERS_3" 3 "PERS_4" 4 "Vehicle" 5 "Unused_1" 6 "Unused_2" 7 "Unused_3" ;
VAL_ 995 LightAmbIntsty_No_Actl 0 "Off" ;
VAL_ 997 PersTurnSglView_D_Stat 0 "Null" 1 "Disabled" 2 "Enabled" 3 "NotConfigured" ;
VAL_ 997 PersIndexCcm_D_Actl 0 "PERS_1" 1 "PERS_2" 2 "PERS_3" 3 "PERS_4" 4 "Vehicle" 5 "Unused_1" 6 "Unused_2" 7 "Unused_3" ;
VAL_ 998 PersIndexSccm_D_Actl 0 "PERS_1" 1 "PERS_2" 2 "PERS_3" 3 "PERS_4" 4 "Vehicle" 5 "Unused_1" 6 "Unused_2" 7 "Unused_3" ;
VAL_ 999 PersIndexFcim_D_Actl 0 "PERS_1" 1 "PERS_2" 2 "PERS_3" 3 "PERS_4" 4 "Vehicle" 5 "Unused_1" 6 "Unused_2" 7 "Unused_3" ;
VAL_ 1000 AHU_Shaker_St 0 "Inactive" 1 "Active" ;
VAL_ 1000 MyKeyVolumeLimitMode 0 "Invalid" 1 "Off" 2 "On" ;
VAL_ 1000 ACM_BeltminderAudioSt 0 "Invalid" 1 "Off" 2 "On" ;
VAL_ 1000 MyKeyVolumeLimitUp 0 "Invalid" 1 "Updated" 2 "NotUpdated" ;
VAL_ 1000 ThermalReduction_St 0 "Null" 1 "NoAudioReduction" 2 "1dB_AudioReduction" 3 "2dB_AudioReduction" 4 "3dB_AudioReduction" 5 "4dB_AudioReduction" 6 "5dB_AudioReduction" 7 "6dB_AudioReduction" 8 "7dB_AudioReduction" 9 "8dB_AudioReduction" 10 "9dB_AudioReduction" 11 "10dB_AudioReduction" 12 "11dB_AudioReduction" 13 "12dB_AudioReduction" 14 "13dB_AudioReduction" 15 "Reserved" ;
VAL_ 1000 AHU_Bezel_Diag_St 0 "Inactive_NOP" 1 "SoftwarePartNumber" 2 "HardwarePartNumber" 3 "CalibrationPartNumber" 4 "SpeakerWalkAround" 5 "SDARSESNNumber" 6 "SignalStrength" 15 "Reserved" ;
VAL_ 1001 AirSuspMsgTxt_D_Rq2 0 "NoMessage" 1 "Override" 2 "Faulty" 3 "NotUsed" ;
VAL_ 1001 PersIndexSuma_D_Actl 0 "PERS_1" 1 "PERS_2" 2 "PERS_3" 3 "PERS_4" 4 "Vehicle" 5 "Unused_1" 6 "Unused_2" 7 "Unused_3" ;
VAL_ 1002 CntrStk_D_RqRecall 0 "Null" 1 "PERS_1" 2 "PERS_2" 3 "PERS_3" 4 "PERS_4" 5 "Vehicle" 6 "Unused_1" 7 "Unused_2" ;
VAL_ 1002 CntrStk_D_RqAssoc 0 "Check_KeyCode" 1 "Erase_KeyCode" 2 "Key" 3 "Null" 4 "RKE" 5 "Set_Keycode" 6 "Cancel" 7 "Unused_2" ;
VAL_ 1002 PersIndexApim_D_Actl 0 "PERS_1" 1 "PERS_2" 2 "PERS_3" 3 "PERS_4" 4 "Vehicle" 5 "Unused_1" 6 "Unused_2" 7 "Unused_3" ;
VAL_ 1004 PersNo_D_Actl 0 "PERS_1" 1 "PERS_2" 2 "PERS_3" 3 "PERS_4" 4 "Vehicle" 5 "NotDetermined" 6 "Unused_2" 7 "Unused_3" ;
VAL_ 1004 Pers1Key_D_Stat 0 "Null" 1 "KeyAssociated" 2 "KeyUnAssociated" 3 "NotUsed_1" ;
VAL_ 1004 AssocConfirm_D_Actl 0 "None" 1 "Disassociate" 2 "Duplicate" 3 "Erase" 4 "In_Progress" 5 "Keycode_Accepted" 6 "Keycode_Rejected" 7 "Associate" ;
VAL_ 1004 PersNoPos_D_Actl 0 "PERS_1" 1 "PERS_2" 2 "PERS_3" 3 "PERS_4" 4 "Vehicle" 5 "Unused_1" 6 "Unused_2" 7 "Unused_3" ;
VAL_ 1004 PersSetupAccessCtrl 0 "Full" 1 "Limited" ;
VAL_ 1004 PersSetupRestr_D_Actl 0 "Factory" 1 "Vehicle" 2 "Moveable_Person" 3 "Non_Moveable_Person" ;
VAL_ 1004 PersConflict_D_Actl 0 "No_Conflict" 1 "Conflict" ;
VAL_ 1004 Pers3Key_D_Stat 0 "Null" 1 "KeyAssociated" 2 "KeyUnAssociated" 3 "NotUsed_1" ;
VAL_ 1004 Pers2Key_D_Stat 0 "Null" 1 "KeyAssociated" 2 "KeyUnAssociated" 3 "NotUsed_1" ;
VAL_ 1004 VehKeyActv_D_Stat 0 "NoKeyActive" 1 "Key1Active" 2 "Key2Active" 3 "Key3Active" 4 "Key4Active" 5 "Key5Active" 6 "Key6Active" 7 "Key7Active" 8 "Key8Active" 9 "NotUsed1" 10 "NotUsed2" 11 "NotUsed3" 12 "NotUsed4" 13 "NotUsed5" 14 "NotUsed6" 15 "NotUsed7" ;
VAL_ 1004 Pers4Key_D_Stat 0 "Null" 1 "KeyAssociated" 2 "KeyUnAssociated" 3 "NotUsed_1" ;
VAL_ 1004 EmPrflNo_D_Stat 0 "Null" 1 "Pers1" 2 "Pers2" 3 "Pers3" 4 "Pers4" 5 "NotUsed_1" 6 "NotUsed_2" 7 "NotUsed_3" ;
VAL_ 1004 EmPrflKeyAssoc_D_Stat 0 "Null" 1 "KeyAssociationEntered" 2 "KeyAssociationExited" 3 "KeyDisassociated" 4 "KeyAlreadyInUse" 5 "KeyAssociateSuccess" 6 "KeyAssociateFailed" 7 "WrongDevice" ;
VAL_ 1004 TailLghtLoadMde_D_Stat 0 "NoTailLightActive" 1 "PayloadModeActive" 2 "HitchLoadModeActive" 3 "FalrModeActive" 4 "TailLightModeOverride" 5 "NotUsed_1" 6 "NotUsed_2" 7 "Faulty" ;
VAL_ 1004 PersRecallSrc_D_Actl 0 "Null" 1 "CenterStack" 2 "KeyFob" 3 "RemoteStart" 4 "MemorySwitch" 5 "NotUsed_1" 6 "NotUsed_2" 7 "NotUsed_3" ;
VAL_ 1006 PersIndexIpmb_D_Actl 0 "PERS_1" 1 "PERS_2" 2 "PERS_3" 3 "PERS_4" 4 "Vehicle" 5 "Unused_1" 6 "Unused_2" 7 "Unused_3" ;
VAL_ 1007 PersIndexIpc2_D_Actl 0 "PERS_1" 1 "PERS_2" 2 "PERS_3" 3 "PERS_4" 4 "Vehicle" 5 "Unused_1" 6 "Unused_2" 7 "Unused_3" ;
VAL_ 1008 RearMnuCtlLck_B_Rq 0 "Unlock" 1 "Lock" ;
VAL_ 1008 CPM_MediaPlayerSrc_St 0 "NoDataExists" 1 "SourceID1" 2 "SourceID2" 3 "SourceID3" 4 "SourceID4" 5 "SourceID5" 6 "SourceID6" 7 "SourceID7" 8 "SourceID8" 9 "SourceID9" 10 "SourceID10" 11 "SourceID11" 12 "SourceID12" 13 "SourceID13" 14 "SourceID14" 15 "SourceID15" 16 "SourceID16" 17 "Reserved1" 18 "Reserved2" 19 "Reserved3" 20 "Reserved4" 21 "Reserved5" 22 "Reserved6" 23 "Reserved7" 24 "Reserved8" 25 "Reserved9" 26 "Reserved10" 27 "Reserved11" 28 "Reserved12" 29 "Reserved13" 30 "Reserved14" 31 "Empty" ;
VAL_ 1008 SelectedNumOfPresets 0 "Inactive" 1 "Preset1" 2 "Preset2" 3 "Preset3" 4 "Preset4" 30 "Preset30" 31 "Reserved" ;
VAL_ 1008 MultimediaSrc_D_Stat 0 "Null" 1 "AudioVideoln" 2 "Usb" 3 "SdCard" 4 "WiFi" 5 "BluetoothAudio" 6 "LineIn" 7 "AppLink" 8 "CarPlay" 9 "AndroidAuto" 10 "BaiduCarlife" ;
VAL_ 1008 MultimediaShuf_D_Stat 0 "Null" 1 "Off" 2 "On" 3 "NotUsed" ;
VAL_ 1008 MultimediaRepeat_D_Stat 0 "Null" 1 "RepeatOne" 2 "RepeatOff" 3 "RepeatOn" ;
VAL_ 1008 NavIod_D_Stat 0 "FeatureNotAvailable" 1 "FeatureAvailButNoOuput" 2 "OutputOn" 3 "CruiseMode_2D" 4 "NavigationMode_2D" 5 "NavigationMode_AR" 6 "NotUsed_1" 7 "NotUsed_2" 8 "NotUsed_3" 9 "NotUsed_4" 10 "NotUsed_5" 11 "NotUsed_6" 12 "NotUsed_7" 13 "NotUsed_8" 14 "NotUsed_9" 15 "Faulty" ;
VAL_ 1009 TrlrAidCancl_B_Rq 0 "Null" 1 "Cancel" ;
VAL_ 1009 AutoHoldSwtch_D_Stat3 0 "Not_Pressed" 1 "Pressed" 2 "NotUsed" 3 "Faulty" ;
VAL_ 1009 RearAudioCtlLck_D_Rq 0 "Null" 1 "Lock" 2 "Unlock" ;
VAL_ 1009 TrlrAidSetup_D_Stat 0 "Null" 1 "BeginSetup" 2 "EndSetup" 3 "EnterParameters" 4 "NotUsed_1" 5 "NotUsed_2" 6 "NotUsed_3" 7 "Faulty" ;
VAL_ 1009 ValetMode_D_Stat 0 "Null" 1 "Off" 2 "On" 3 "NotUsed" ;
VAL_ 1009 CenterStackRing_D_Actl 0 "Null" 1 "Off" 2 "On" 3 "LimitedOn" ;
VAL_ 1009 ChrgCordUnlock_B_Rq 0 "NoRequest" 1 "Request" ;
VAL_ 1009 TrlrTrgtAcquire_D_Rq 0 "Inactive" 1 "StartAcquisition" 2 "AcquisitionSuccessful" 3 "RetryAcquisition" 4 "CancelAcquisition" 5 "ActivateRVCforTBA" 6 "NotUsed_1" 7 "NotUsed_2" ;
VAL_ 1011 ChrgLocLattPostv_B_Uns 0 "No" 1 "Yes" ;
VAL_ 1011 VehShutDownMsgTxt_D_Rq 0 "NoMessage" 1 "ShutdownWarning" 2 "ProhibitedRestart" 3 "NotUsed" ;
VAL_ 1011 ChrgLocLongPostv_B_Uns 0 "No" 1 "Yes" ;
VAL_ 1012 ChrgLocLattPostv_B_Sav 0 "No" 1 "Yes" ;
VAL_ 1012 AirCondRec_B_RqVehEl 0 "No" 1 "Yes" ;
VAL_ 1012 ChrgLocSaved_B_Dsply 0 "No" 1 "Yes" ;
VAL_ 1012 ChrgNowCurnt_B_Dsply 0 "Off" 1 "On" ;
VAL_ 1012 ChrgLocLongPostv_B_Sav 0 "No" 1 "Yes" ;
VAL_ 1013 ChrgNowEnbl_B_Saved 0 "Off" 1 "On" ;
VAL_ 1013 ChrgLocIdUnsAck_B_Stat 0 "No" 1 "Yes" ;
VAL_ 1013 ChrgToPcWkndSav_D_Stat 0 "Percent_100" 1 "Percent_95" 2 "Percent_90" 3 "Percent_85" 4 "Percent_80" 5 "Percent_70" 6 "Percent_60" 7 "Percent_50" ;
VAL_ 1013 ChrgToPcWkdySav_D_Stat 0 "Percent_100" 1 "Percent_95" 2 "Percent_90" 3 "Percent_85" 4 "Percent_80" 5 "Percent_70" 6 "Percent_60" 7 "Percent_50" ;
VAL_ 1014 WrlssAcsyChrgr_D_Stat 0 "Null" 1 "ChargingNotInProgress" 2 "ChargingInProgress" 3 "ChargingComplete" 4 "MetalObjectDetected" 5 "Overheat" 6 "Misalignment" 7 "NotUsed" ;
VAL_ 1014 WrlssAcsyChrg_Pc_Actl 126 "NoDataExists" 127 "Faulty" ;
VAL_ 1015 SelDrvMdeSwtch_D_Stat7 0 "NotPressed" 1 "SwitchState1" 2 "SwitchState2" 3 "Faulty" ;
VAL_ 1015 E_Frt_Btn_Status_1st 0 "None_Pressed" 1 "Panel_Pressed" 2 "Panel_Floor_Pressed" 3 "Floor_Pressed" 4 "Floor_Ws_Pressed" 5 "AC_Pressed" 6 "Dual_Pressed" 7 "LHS_Temp_Inc_Pressed" 8 "LHS_Temp_Dec_Pressed" 9 "RHS_Temp_Inc_Pressed" 10 "RHS_Temp_Dec_Pressed" 11 "Blwr_Inc_Pressed" 12 "Blwr_Dec_Pressed" 13 "Auto_Pressed" 14 "Max_AC_Pressed" 15 "Recirc_Pressed" 16 "Outside_Pressed" 17 "Auto_Recirc_Pressed" 18 "Htd_Frt_Wsh_Pressed" 19 "Windscreen_Pressed" 20 "Pnl_Ws_Pressed" 21 "Pnl_Flr_Ws_Pressed" 22 "Rear_Defrost_Pressed" 23 "Front_Power_Pressed" 24 "My_Temp_Pressed" 25 "Max_Defrost_Pressed" 26 "LHS_Htd_Seat_Pressed" 27 "RHS_Htd_Seat_Pressed" 28 "LHS_Cld_Seat_Pressed" 29 "RHS_Cld_Seat_Pressed" 30 "Htg_Strg_Whl_Pressed" 31 "Defrost_Pressed" 32 "FrontMnu_Pressed" 33 "RearMnu_Pressed" 34 "Heat_Pressed" 35 "AAR_Pressed" 36 "MdeMnu_Pressed" 37 "DrvrFcsdMde_Pressed" 38 "LHS_Seat_Off_Pressed" 39 "LHS_Htd_Seat1_Pressed" 40 "LHS_Htd_Seat2_Pressed" 41 "LHS_Htd_Seat3_Pressed" 42 "LHS_Auto_Seat_Pressed" 43 "RHS_Seat_Off_Pressed" 44 "RHS_Htd_Seat1_Pressed" 45 "RHS_Htd_Seat2_Pressed" 46 "RHS_Htd_Seat3_Pressed" 47 "RHS_Auto_Seat_Pressed" 48 "LHS_Cld_Seat1_Pressed" 49 "LHS_Cld_Seat2_Pressed" 50 "LHS_Cld_Seat3_Pressed" 51 "RHS_Cld_Seat1_Pressed" 52 "RHS_Cld_Seat2_Pressed" 53 "RHS_Cld_Seat3_Pressed" 54 "AUTO_Lo_Pressed" 55 "AUTO_Med_Pressed" 56 "AUTO_Hi_Pressed" 57 "AUTO_Inc_Pressed" 58 "AUTO_Dec_Pressed" 59 "NotUsed_1" 60 "NotUsed_2" 61 "NotUsed_3" 62 "NotUsed_4" 63 "NotUsed_5" ;
VAL_ 1015 E_Frt_Btn_Status_2nd 0 "None_Pressed" 1 "Panel_Pressed" 2 "Panel_Floor_Pressed" 3 "Floor_Pressed" 4 "Floor_Ws_Pressed" 5 "AC_Pressed" 6 "Dual_Pressed" 7 "LHS_Temp_Inc_Pressed" 8 "LHS_Temp_Dec_Pressed" 9 "RHS_Temp_Inc_Pressed" 10 "RHS_Temp_Dec_Pressed" 11 "Blwr_Inc_Pressed" 12 "Blwr_Dec_Pressed" 13 "Auto_Pressed" 14 "Max_AC_Pressed" 15 "Recirc_Pressed" 16 "Outside_Pressed" 17 "Auto_Recirc_Pressed" 18 "Htd_Frt_Wsh_Pressed" 19 "Windscreen_Pressed" 20 "Pnl_Ws_Pressed" 21 "Pnl_Flr_Ws_Pressed" 22 "Rear_Defrost_Pressed" 23 "Front_Power_Pressed" 24 "My_Temp_Pressed" 25 "Max_Defrost_Pressed" 26 "LHS_Htd_Seat_Pressed" 27 "RHS_Htd_Seat_Pressed" 28 "LHS_Cld_Seat_Pressed" 29 "RHS_Cld_Seat_Pressed" 30 "Htg_Strg_Whl_Pressed" 31 "Defrost_Pressed" 32 "FrontMnu_Pressed" 33 "RearMnu_Pressed" 34 "Heat_Pressed" 35 "AAR_Pressed" 36 "MdeMnu_Pressed" 37 "DrvrFcsdMde_Pressed" 38 "LHS_Seat_Off_Pressed" 39 "LHS_Htd_Seat1_Pressed" 40 "LHS_Htd_Seat2_Pressed" 41 "LHS_Htd_Seat3_Pressed" 42 "LHS_Auto_Seat_Pressed" 43 "RHS_Seat_Off_Pressed" 44 "RHS_Htd_Seat1_Pressed" 45 "RHS_Htd_Seat2_Pressed" 46 "RHS_Htd_Seat3_Pressed" 47 "RHS_Auto_Seat_Pressed" 48 "LHS_Cld_Seat1_Pressed" 49 "LHS_Cld_Seat2_Pressed" 50 "LHS_Cld_Seat3_Pressed" 51 "RHS_Cld_Seat1_Pressed" 52 "RHS_Cld_Seat2_Pressed" 53 "RHS_Cld_Seat3_Pressed" 54 "AUTO_Lo_Pressed" 55 "AUTO_Med_Pressed" 56 "AUTO_Hi_Pressed" 57 "AUTO_Inc_Pressed" 58 "AUTO_Dec_Pressed" 59 "NotUsed_1" 60 "NotUsed_2" 61 "NotUsed_3" 62 "NotUsed_4" 63 "NotUsed_5" ;
VAL_ 1016 ChrgGoTTouch_B_Stat 0 "Off" 1 "On" ;
VAL_ 1016 ChrgGoTExtHtrEnbl_B_Rq 0 "NoRequest" 1 "Request" ;
VAL_ 1016 ChrgGoTExtHtr_B_Stat 0 "Off" 1 "On" ;
VAL_ 1016 ChrgGoTAllOn_B_Stat 0 "Off" 1 "On" ;
VAL_ 1016 ChrgGoTTouchEnbl_B_Rq 0 "NoRequest" 1 "Request" ;
VAL_ 1016 ChrgGoTPrcond_D_Stat 0 "Off" 1 "Low" 2 "Medium" 3 "High" ;
VAL_ 1016 ChrgGoTHr_T_Stat 30 "NoDataExists" 31 "Faulty" ;
VAL_ 1016 ChrgGoTMnte_D_Stat 0 "Minute_0" 1 "Minute_5" 2 "Minute_10" 3 "Minute_15" 4 "Minute_20" 5 "Minute_25" 6 "Minute_30" 7 "Minute_35" 8 "Minute_40" 9 "Minute_45" 10 "Minute_50" 11 "Minute_55" 12 "NotUsed_1" 13 "NotUsed_2" 14 "NotUsed_3" 15 "NotUsed_4" ;
VAL_ 1016 EngStrtChimeSet_D_St 0 "Null" 1 "Off" 2 "On" 3 "NotUsed" ;
VAL_ 1016 ChrgGoTElement_B_Dsply 0 "No" 1 "Yes" ;
VAL_ 1018 TrlrTireILF_P_Actl 65534 "Invalid" 65535 "NotSupported" ;
VAL_ 1018 TrlrTireILM_P_Actl 65534 "Invalid" 65535 "NotSupported" ;
VAL_ 1018 TrlrTireILR_P_Actl 65534 "Invalid" 65535 "NotSupported" ;
VAL_ 1018 TrlrTireSensILM_D_Stat 0 "Unknown" 1 "Normal" 2 "Low" 3 "Fault" 4 "Alert" 5 "NotUsed1" 6 "NotUsed2" 7 "NotUsed3" 8 "NotUsed4" 9 "NotUsed5" 10 "NotUsed6" 11 "NotUsed7" 12 "NotUsed8" 13 "NotUsed9" 14 "NotUsed10" 15 "NotSupported" ;
VAL_ 1018 TrlrTireSensILF_D_Stat 0 "Unknown" 1 "Normal" 2 "Low" 3 "Fault" 4 "Alert" 5 "NotUsed1" 6 "NotUsed2" 7 "NotUsed3" 8 "NotUsed4" 9 "NotUsed5" 10 "NotUsed6" 11 "NotUsed7" 12 "NotUsed8" 13 "NotUsed9" 14 "NotUsed10" 15 "NotSupported" ;
VAL_ 1018 TrlrTireSensILR_D_Stat 0 "Unknown" 1 "Normal" 2 "Low" 3 "Fault" 4 "Alert" 5 "NotUsed1" 6 "NotUsed2" 7 "NotUsed3" 8 "NotUsed4" 9 "NotUsed5" 10 "NotUsed6" 11 "NotUsed7" 12 "NotUsed8" 13 "NotUsed9" 14 "NotUsed10" 15 "NotSupported" ;
VAL_ 1019 PersIndexIpc_D_Actl 0 "PERS_1" 1 "PERS_2" 2 "PERS_3" 3 "PERS_4" 4 "Vehicle" 5 "Unused_1" 6 "Unused_2" 7 "Unused_3" ;
VAL_ 1020 CtrStkDsplyOp2_D_Rq 0 "Null" 1 "Query" 2 "Set" 3 "Upload" 4 "Restore" 5 "Copy" 6 "Unused_1" 7 "Unused_2" ;
VAL_ 1020 CtrStkPersIndex2_D_Actl 0 "PERS_1" 1 "PERS_2" 2 "PERS_3" 3 "PERS_4" 4 "Vehicle" 5 "Unused_1" 6 "Unused_2" 7 "Unused_3" ;
VAL_ 1021 TrlrTireIRF_P_Actl 65534 "Invalid" 65535 "NotSupported" ;
VAL_ 1021 TrlrTireIRM_P_Actl 65534 "Invalid" 65535 "NotSupported" ;
VAL_ 1021 TrlrTireIRR_P_Actl 65534 "Invalid" 65535 "NotSupported" ;
VAL_ 1021 TrlrTireSensIRM_D_Stat 0 "Unknown" 1 "Normal" 2 "Low" 3 "Fault" 4 "Alert" 5 "NotUsed1" 6 "NotUsed2" 7 "NotUsed3" 8 "NotUsed4" 9 "NotUsed5" 10 "NotUsed6" 11 "NotUsed7" 12 "NotUsed8" 13 "NotUsed9" 14 "NotUsed10" 15 "NotSupported" ;
VAL_ 1021 TrlrTireSensIRF_D_Stat 0 "Unknown" 1 "Normal" 2 "Low" 3 "Fault" 4 "Alert" 5 "NotUsed1" 6 "NotUsed2" 7 "NotUsed3" 8 "NotUsed4" 9 "NotUsed5" 10 "NotUsed6" 11 "NotUsed7" 12 "NotUsed8" 13 "NotUsed9" 14 "NotUsed10" 15 "NotSupported" ;
VAL_ 1021 TrlrTireSensIRR_D_Stat 0 "Unknown" 1 "Normal" 2 "Low" 3 "Fault" 4 "Alert" 5 "NotUsed1" 6 "NotUsed2" 7 "NotUsed3" 8 "NotUsed4" 9 "NotUsed5" 10 "NotUsed6" 11 "NotUsed7" 12 "NotUsed8" 13 "NotUsed9" 14 "NotUsed10" 15 "NotSupported" ;
VAL_ 1022 TrlrTireILF_T_Actl 254 "Invalid" 255 "NotSupported" ;
VAL_ 1022 TrlrTireILM_T_Actl 254 "Invalid" 255 "NotSupported" ;
VAL_ 1022 TrlrTireILR_T_Actl 254 "Invalid" 255 "NotSupported" ;
VAL_ 1022 TrlrTireIRF_T_Actl 254 "Invalid" 255 "NotSupported" ;
VAL_ 1022 TrlrTireIRM_T_Actl 254 "Invalid" 255 "NotSupported" ;
VAL_ 1022 TrlrTireIRR_T_Actl 254 "Invalid" 255 "NotSupported" ;
VAL_ 1022 TrlrTireTSensIRF_D_Stat 0 "NotAvailable" 1 "Normal" 2 "HighTempWarning" 3 "Faulty" ;
VAL_ 1022 TrlrTireTSensILR_D_Stat 0 "NotAvailable" 1 "Normal" 2 "HighTempWarning" 3 "Faulty" ;
VAL_ 1022 TrlrTireTSensILM_D_Stat 0 "NotAvailable" 1 "Normal" 2 "HighTempWarning" 3 "Faulty" ;
VAL_ 1022 TrlrTireTSensILF_D_Stat 0 "NotAvailable" 1 "Normal" 2 "HighTempWarning" 3 "Faulty" ;
VAL_ 1022 TrlrTireTSensIRR_D_Stat 0 "NotAvailable" 1 "Normal" 2 "HighTempWarning" 3 "Faulty" ;
VAL_ 1022 TrlrTireTSensIRM_D_Stat 0 "NotAvailable" 1 "Normal" 2 "HighTempWarning" 3 "Faulty" ;
VAL_ 1036 OnbSnd_D_Stat 0 "Inactive" 1 "Active" 2 "Overridden" 3 "Faulty" ;
VAL_ 1036 PdstrnAlrt_B_Falt 0 "No" 1 "Yes" ;
VAL_ 1040 BattTrac_I2_EstVsc 262142 "NoDataExists" 262143 "Faulty" ;
VAL_ 1040 ElCmprEnbl_B_Rq 0 "Disable" 1 "Enable" ;
VAL_ 1040 ElCmpr2Enbl_B_Rq 0 "Disable" 1 "Enable" ;
VAL_ 1040 RoadGrd_Pc_Est 1023 "Faulty" ;
VAL_ 1041 ElCmpr_Pw_Actl 255 "Invalid" ;
VAL_ 1041 ElCmpr_N_Actl 255 "Invalid" ;
VAL_ 1041 ElCmpr_D_Stat 0 "Comp_Off" 1 "Comp_On" 2 "Comp_Degraded" 3 "Comp_Stopped_Self_Protect" 4 "Comp_Shutdown" 5 "Comp_Off_TrgtSpd_OutRange" 6 "Comp_Off_ActlSpd_Abnormal" 7 "Signal_Invalid" ;
VAL_ 1041 ElCmprOverTe_D_Stat 0 "Undefined" 1 "Normal" 2 "OverTempWarning" 3 "OverTempStop" ;
VAL_ 1041 ElCmprUHi_D_Stat 0 "Undetermined" 1 "InRange" 2 "Undervoltage" 3 "Overvoltage" ;
VAL_ 1041 ElCmprLostComm_D_Falt 0 "Not_Diagnose_Yet" 1 "Fail" 2 "Pass" 3 "NotUsed" ;
VAL_ 1041 ElCmprInnrErr_D_Falt 0 "Not_Diagnose_Yet" 1 "Fail" 2 "Pass" 3 "NotUsed" ;
VAL_ 1041 ElCmprBattURng_D_Falt 0 "Not_Diagnose_Yet" 1 "Fail" 2 "Pass" 3 "NotUsed" ;
VAL_ 1041 ElCmprBattSysU_D_Falt 0 "Not_Diagnose_Yet" 1 "Fail" 2 "Pass" 3 "NotUsed" ;
VAL_ 1041 ElCmprSysU_D_Falt 0 "Not_Diagnose_Yet" 1 "Fail" 2 "Pass" 3 "NotUsed" ;
VAL_ 1041 ElCmprPerfErr_D_Falt 0 "Not_Diagnose_Yet" 1 "Fail" 2 "Pass" 3 "NotUsed" ;
VAL_ 1041 ElCmprOverTe_D_Falt 0 "Not_Diagnose_Yet" 1 "Fail" 2 "Pass" 3 "NotUsed" ;
VAL_ 1041 ElCmprOverLoad_D_Falt 0 "Not_Diagnose_Yet" 1 "Fail" 2 "Pass" 3 "NotUsed" ;
VAL_ 1042 VehPtch_An_Dsply 126 "NoDataExists" 127 "Faulty" ;
VAL_ 1042 VehRol_An_Dsply 126 "NoDataExists" 127 "Faulty" ;
VAL_ 1042 RearDiffLck_Tq_RqMn 4095 "Faulty" ;
VAL_ 1043 OrtaSwtchLamp_B_Rq 0 "Off" 1 "On" ;
VAL_ 1043 OrtaMsgTxt_D_Rq 0 "NoMessage" 1 "Message1" 2 "Message2" 3 "Message3" 4 "Message4" 5 "Message5" 6 "Message6" 7 "Message7" 8 "Message8" 9 "Message9" 10 "Message10" 11 "Message11" 12 "Message12" 13 "Message13" 14 "Message14" 15 "Message15" ;
VAL_ 1043 OrtaMde_D_Ind 0 "Off" 1 "StandbyLeft" 2 "StandbyRight" 3 "ActiveLeft" 4 "ActiveRight" 5 "NotUsed_1" 6 "NotUsed_2" 7 "Faulty" ;
VAL_ 1043 IndvMdeSel_D_Stat 0 "NoDriveModeChangeRequest" 1 "DriveModeChangeSelection" 2 "DriveModeChangeRequest" 3 "NotUsed" ;
VAL_ 1043 TrailOnePdlMsgTxt_D_Rq 0 "NoMessage" 1 "Message1" 2 "Message2" 3 "Message3" 4 "Message4" 5 "Message5" 6 "Message6" 7 "Message7" ;
VAL_ 1043 TrailOnePdlMde_D_Ind 0 "Off" 1 "Fault" 2 "Active" 3 "Standby" 4 "NotUsed_1" 5 "NotUsed_2" 6 "NotUsed_3" 7 "NotUsed_4" ;
VAL_ 1043 IndvMdeMsgTxt_D_Rq 0 "NoMessage" 1 "Message1" 2 "Message2" 3 "Message3" 4 "Message4" 5 "Message5" 6 "Message6" 7 "Message7" 8 "Message8" 9 "Message9" 10 "Message10" 11 "Message11" 12 "Message12" 13 "Message13" 14 "Message14" 15 "Message15" ;
VAL_ 1043 PrkBrkPerfActv_B_Stat 0 "Inactive" 1 "Active" ;
VAL_ 1043 PrkBrkPerfMde_D_Stat 0 "Off" 1 "On" 2 "NotUsed" 3 "Faulty" ;
VAL_ 1043 IndvMde5_B_Avail 0 "NotAvailable" 1 "Available" ;
VAL_ 1043 IndvMde4_B_Avail 0 "NotAvailable" 1 "Available" ;
VAL_ 1043 IndvMde3_B_Avail 0 "NotAvailable" 1 "Available" ;
VAL_ 1043 IndvMde2_B_Avail 0 "NotAvailable" 1 "Available" ;
VAL_ 1043 IndvMde1_B_Avail 0 "NotAvailable" 1 "Available" ;
VAL_ 1043 WhlSpareMsgTxt_D_Rq 0 "NoMessage" 1 "DoNotDriveAbove80kph" 2 "PleaseChangeYourSpareTire" 3 "NotUsed" ;
VAL_ 1043 PrkBrkApplCpblty_B_Stat 0 "Degraded" 1 "Ok" ;
VAL_ 1043 SelDrvMdeHmi02_D_Rq 0 "SelDrvMde01" 1 "SelDrvMde02" 2 "SelDrvMde03" 3 "SelDrvMde04" 4 "SelDrvMde05" 5 "SelDrvMde06" 6 "SelDrvMde07" 7 "SelDrvMde08" 8 "SelDrvMde09" 9 "SelDrvMde10" 10 "SelDrvMde11" 11 "SelDrvMde12" 12 "SelDrvMde13" 13 "SelDrvMde14" 14 "SelDrvMde15" 15 "SelDrvMde16" 16 "SelDrvMde17" 17 "SelDrvMde18" 18 "SelDrvMde19" 19 "SelDrvMde20" 20 "SelDrvMde21" 21 "SelDrvMde22" 22 "SelDrvMde23" 23 "SelDrvMde24" 24 "SelDrvMde25" 25 "SelDrvMde26" 26 "SelDrvMde27" 27 "SelDrvMde28" 28 "SelDrvMde29" 29 "SelDrvMde30" 30 "SelDrvMde31" 31 "Faulty" ;
VAL_ 1043 WhlSpareDetct_D_Dsply 0 "NotActive" 1 "Active" 2 "DetectedAtVehicleFrontLeft" 3 "DetectedAtVehicleFrntRight" 4 "DetectedAtVehicleRearLeft" 5 "DetectedAtVehicleRearRight" 6 "NotUsed_1" 7 "NotUsed_2" ;
VAL_ 1043 SelDrvMdeHmi04_D_Rq 0 "SelDrvMde01" 1 "SelDrvMde02" 2 "SelDrvMde03" 3 "SelDrvMde04" 4 "SelDrvMde05" 5 "SelDrvMde06" 6 "SelDrvMde07" 7 "SelDrvMde08" 8 "SelDrvMde09" 9 "SelDrvMde10" 10 "SelDrvMde11" 11 "SelDrvMde12" 12 "SelDrvMde13" 13 "SelDrvMde14" 14 "SelDrvMde15" 15 "SelDrvMde16" 16 "SelDrvMde17" 17 "SelDrvMde18" 18 "SelDrvMde19" 19 "SelDrvMde20" 20 "SelDrvMde21" 21 "SelDrvMde22" 22 "SelDrvMde23" 23 "SelDrvMde24" 24 "SelDrvMde25" 25 "SelDrvMde26" 26 "SelDrvMde27" 27 "SelDrvMde28" 28 "SelDrvMde29" 29 "SelDrvMde30" 30 "SelDrvMde31" 31 "Faulty" ;
VAL_ 1043 PrkBrkPerfMsgTxt_D_Rq 0 "NoMessage" 1 "Message1" 2 "Message2" 3 "Message3" 4 "Message4" 5 "Message5" 6 "Message6" 7 "Message7" 8 "Message8" 9 "Message9" 10 "Message10" 11 "Message11" 12 "Message12" 13 "Message13" 14 "Message14" 15 "Message15" 16 "Message16" 17 "Message17" 18 "Message18" 19 "Message19" 20 "Message20" 21 "Message21" 22 "Message22" 23 "Message23" 24 "Message24" 25 "Message25" 26 "Message26" 27 "Message27" 28 "Message28" 29 "Message29" 30 "Message30" 31 "Message31" ;
VAL_ 1045 BrkFluidLvl_D_Stat 0 "OK" 1 "Low" 2 "Unknown" 3 "Invalid" ;
VAL_ 1045 VehVActlBrk_D_Qf 0 "Faulty" 1 "No_Data_Exists" 2 "Not_Within_Specifications" 3 "OK" ;
VAL_ 1045 VehYawLin_W_Rq 4094 "Unknown" 4095 "Fault" ;
VAL_ 1045 LsmcBrkDecel_D_Stat 0 "Off" 1 "On" 2 "FaultExt" 3 "FaultDegraded" 4 "Denied" 5 "NotUsed_1" 6 "NotUsed_2" 7 "NotUsed_3" ;
VAL_ 1045 VehYawNonLin_W_Rq 4094 "Unknown" 4095 "Fault" ;
VAL_ 1045 VehStab_D_Stat 0 "Linear" 1 "Oversteer" 2 "Understeer" 3 "Countersteer" 4 "Post_Transition" 5 "Post_Oversteer" 6 "Straight" 7 "High_SSRA_no_OS" 8 "Combined_OS_and_US" 9 "NotUsed2" 10 "NotUsed3" 11 "NotUsed4" 12 "NotUsed5" 13 "NotUsed6" 14 "No_Data_Exists" 15 "Faulty" ;
VAL_ 1046 StabCtlBrk_B_Avail 0 "No" 1 "Yes" ;
VAL_ 1046 Abs_B_Falt 0 "No" 1 "Yes" ;
VAL_ 1046 BpedMove_D_Actl 0 "AutonomousBrkPedalMove" 1 "NoAutonomousBrkPdlMovement" 2 "DriverApplyingBrakePedal" 3 "Unknown" ;
VAL_ 1046 DrvHdcMsg_D_Rq 0 "No_Message" 1 "On" 2 "Off" 3 "Select_Gear" 4 "System_Fault" 5 "Temporarily_Unavailable" 6 "Speed_too_High" 7 "Undefined" ;
VAL_ 1046 DrvHdcLampInfo_D_Rq 0 "Off" 1 "On" 2 "Slow_Flash" 3 "Fast_Flash" ;
VAL_ 1046 BrkLamp_B_Rq 0 "No" 1 "Yes" ;
VAL_ 1046 ChimeBrk_B_Rq 0 "No" 1 "Yes" ;
VAL_ 1046 TCMode 0 "Inactive" 1 "Active" ;
VAL_ 1046 BrkPrkBrkDynmc_B_Actl 0 "Inactive" 1 "Active" ;
VAL_ 1046 TRLR_SWAY_EVNT_IN_PROG 0 "No" 1 "Yes" ;
VAL_ 1046 TRLR_SWAY_CONFIG_STAT 0 "Off" 1 "On" ;
VAL_ 1046 BrkBstrVac_B_Rq 0 "No" 1 "Yes" ;
VAL_ 1046 HdcMde_D_Actl 0 "Undefined" 1 "Off" 2 "Not_Active_Braking" 3 "Active_Braking" 4 "NotEnabled_SpdLimitExceed" 5 "NotEnabled_WrongGearSel" 6 "Temporarily_Unavailable" 7 "Fault" ;
VAL_ 1046 HsaMde_D_Mem 0 "Off" 1 "Automatic" 2 "Manual" 3 "Undefined" ;
VAL_ 1046 DrvHdcWarnInfo_D_Rq 0 "Lamp_Off_Continuously" 1 "Lamp_Flashing" 2 "Lamp_On_Continuously" 3 "Undefined" ;
VAL_ 1046 PrkBrkDynmc_D_Allw 0 "Used_at_Start_Up" 1 "EPB_ECD_Possible" 2 "EPB_ECD_NotPossible" 3 "NotUsed" ;
VAL_ 1046 RearDiffElckrOpen_B_Rq 0 "No" 1 "Yes" ;
VAL_ 1046 DrvSlipCtlLamp_D_Rq 0 "Off" 1 "On" 2 "Slow_Flash" 3 "Fast_Flash" ;
VAL_ 1046 DrvSlipCtlMde_D_Ind 0 "Default_Mode" 1 "App_Specific_Off_Mode_1" 2 "App_Specific_Off_Mode_2" 3 "App_Specific_Off_Mode_3" ;
VAL_ 1046 HILL_DESC_MC 0 "Normal" 1 "Off_Road" 2 "Enabled" 3 "Disabled" 4 "Active" 5 "Abort_Apply_Brakes" 6 "Cooling_Down" 7 "Fault_Detected" ;
VAL_ 1046 RearDiffLck_Tq2_RqMx 4095 "Faulty" ;
VAL_ 1046 DrvAntiLckLamp_D_Rq 0 "Off" 1 "On" 2 "Slow_Flash" 3 "Fast_Flash" ;
VAL_ 1047 TrlrAidMsgTxt_D2_Rq 0 "NoMessage" 1 "Message1" 2 "Message2" 3 "Message3" 4 "Message4" 5 "Message5" 6 "Message6" 7 "Message7" 8 "Message8" 9 "Message9" 10 "Message10" 11 "Message11" 12 "Message12" 13 "Message13" 14 "Message14" 15 "Message15" 16 "Message16" 17 "Message17" 18 "Message18" 19 "Message19" 20 "Message20" 21 "Message21" 22 "Message22" 23 "Message23" 24 "Message24" 25 "Message25" 26 "Message26" 27 "Message27" 28 "Message28" 29 "Message29" 30 "Message30" 31 "Message31" 35 "Message35" 40 "Message40" 45 "Message45" 50 "Message50" 55 "Message55" 60 "Message60" 61 "Message61" 62 "Message62" 63 "Message63" ;
VAL_ 1047 SelDrvMdeSte_D_Stat 0 "NotAvailable" 1 "Available" 2 "TemporarilyNotAvailable" 3 "Faulty" ;
VAL_ 1047 EsaOn_B_Stat 0 "Off" 1 "On" ;
VAL_ 1047 TrlrAidEnbl_D2_Stat 0 "Inactive" 1 "TbaActive" 2 "TbaSetup" 3 "TbaOffTrgSetup" 4 "TbaOffTrgActive" 5 "TbaActiveExpertAvail" 6 "TbaActiveExpertActive" 7 "NotUsed_1" ;
VAL_ 1047 TrlrAidSetup_D2_Stat 0 "Null" 1 "TbaActive" 2 "SetupPrepForAcquisition" 3 "SetupStartAcquisition" 4 "TbaTadMonitor" 5 "SetupAcquisitionSuccess" 6 "NotUsed_1" 7 "NotUsed_2" ;
VAL_ 1049 SelDrvMdePage_B_Stat 0 "Inactive" 1 "Active" ;
VAL_ 1049 SelDrvMdeCnfm_D_Stat2 0 "Null" 1 "NotAccepted" 2 "Accepted" 3 "NotUsed" ;
VAL_ 1049 SelDrvMde_D_RqDrv 0 "SelDrvMde01" 1 "SelDrvMde02" 2 "SelDrvMde03" 3 "SelDrvMde04" 4 "SelDrvMde05" 5 "SelDrvMde06" 6 "SelDrvMde07" 7 "SelDrvMde08" 8 "SelDrvMde09" 9 "SelDrvMde10" 10 "SelDrvMde11" 11 "SelDrvMde12" 12 "SelDrvMde13" 13 "SelDrvMde14" 14 "SelDrvMde15" 15 "SelDrvMde16" 16 "SelDrvMde17" 17 "SelDrvMde18" 18 "SelDrvMde19" 19 "SelDrvMde20" 20 "SelDrvMde21" 21 "SelDrvMde22" 22 "SelDrvMde23" 23 "SelDrvMde24" 24 "SelDrvMde25" 25 "SelDrvMde26" 26 "SelDrvMde27" 27 "SelDrvMde28" 28 "SelDrvMde29" 29 "SelDrvMde30" 30 "SelDrvMde31" 31 "Faulty" ;
VAL_ 1049 RearDiffLck_D_RqDrv3 0 "Off" 1 "On" 2 "NoRequest" 3 "Faulty" ;
VAL_ 1049 FrontDiffLck_D_RqDrv3 0 "Off" 1 "On" 2 "NoRequest" 3 "Faulty" ;
VAL_ 1049 CamraFrnt_B_RqMnu 0 "Off" 1 "On" ;
VAL_ 1049 TurnAsstSwtch_D_Stat 0 "Not_Pressed" 1 "Pressed" 2 "NotUsed" 3 "Faulty" ;
VAL_ 1049 SelDrvMdeTxtRst_B_Rq2 0 "No" 1 "Yes" ;
VAL_ 1049 DcacAllZoneBttn_B_Stat 0 "Not_Pressed" 1 "Pressed" ;
VAL_ 1049 DcacChime_D_Rq 0 "NoChime" 1 "InformationChime" 2 "SoftChime" 3 "NotUsed" ;
VAL_ 1049 PersTurnSglView_D_RqMnu 0 "Null" 1 "Disable" 2 "Enable" 3 "NotUsed" ;
VAL_ 1049 TrailCtlSwtch_B_Stat4 0 "Not_Pressed" 1 "Pressed" ;
VAL_ 1049 StabBarCnncButtn_D_Sta3 0 "Not_Pressed" 1 "Pressed" 2 "NotUsed" 3 "Faulty" ;
VAL_ 1049 LnchCtl_D_Rq2 0 "LC_Off" 1 "LC_On" 2 "NotUsed1" 3 "NotUsed2" ;
VAL_ 1049 DcacZone3PwBttn_B_Stat 0 "Not_Pressed" 1 "Pressed" ;
VAL_ 1049 DcacZone2PwBttn_B_Stat 0 "Not_Pressed" 1 "Pressed" ;
VAL_ 1049 DcacPwResetBtn2_B_Stat 0 "Not_Pressed" 1 "Pressed" ;
VAL_ 1049 DcacPwOffButtn2_B_Stat 0 "Not_Pressed" 1 "Pressed" ;
VAL_ 1049 DcacPwHiButtn2_B_Stat 0 "Not_Pressed" 1 "Pressed" ;
VAL_ 1049 DcacGfciTestBtn2_B_Stat 0 "Not_Pressed" 1 "Pressed" ;
VAL_ 1049 Chrgr_Pw_EstMx 510 "NoDataExists" 511 "Faulty" ;
VAL_ 1049 Fba_D_Rq 0 "Null" 1 "Off" 2 "On" 3 "NotUsed" ;
VAL_ 1049 ExtLghtAnmtn_D_Rq 0 "Null" 1 "Type1" 2 "Type2" 3 "Type3" 4 "Type4" 5 "Type5" 6 "Type6" 7 "NotUsed_1" 8 "NotUsed_2" 9 "NotUsed_3" 10 "NotUsed_4" 11 "NotUsed_5" 12 "NotUsed_6" 13 "NotUsed_7" 14 "NotUsed_8" 15 "Faulty" ;
VAL_ 1049 DrvSlipCtlMde_B_Rq6 0 "Not_Pressed" 1 "Pressed" ;
VAL_ 1050 Outside_Air_Temp_Stat 254 "Unknown" 255 "Invalid" ;
VAL_ 1050 CamraFrntBttn_D_Stat 0 "Not_Pressed" 1 "Pressed" ;
VAL_ 1050 DrvSlipCtlMde_B_Rq 0 "Not_Pressed" 1 "Pressed" ;
VAL_ 1050 SteWhlHeat_D_Rq 0 "Off" 1 "Level_1_Heating_LS" 2 "Level_1_Heating" 3 "Level_2_Heating_LS" 4 "Level_2_Heating" 5 "Level_3_Heating_LS" 6 "Level_3_Heating" 7 "Reserved_1" 8 "Reserved_2" 9 "Reserved_3" 10 "NotUsed1" 11 "NotUsed2" 12 "NotUsed3" 13 "NotUsed4" 14 "NotUsed5" 15 "NotUsed6" ;
VAL_ 1050 MirrorHeatOn_B_Rq 0 "False" 1 "True" ;
VAL_ 1050 Remote_Start_QuietMode 0 "Not_Quiet" 1 "Quiet" ;
VAL_ 1050 TrailCtlSwtch_B_Stat 0 "Not_Pressed" 1 "Pressed" ;
VAL_ 1050 EcoInhbt_B_RqHvac 0 "No" 1 "Yes" ;
VAL_ 1050 PrkAidSwtch_D_RqDrv 0 "Not_Pressed" 1 "Pressed" ;
VAL_ 1050 AutoHoldSwtch_D_Stat 0 "Not_Pressed" 1 "Pressed" 2 "NotUsed" 3 "Faulty" ;
VAL_ 1050 LpdbDfrstRearOn_B_Rq 0 "Off" 1 "On" ;
VAL_ 1050 LpdbDfrstFrOn_B_Rq 0 "Off" 1 "On" ;
VAL_ 1050 LpdbDfrstFlOn_B_Rq 0 "Off" 1 "On" ;
VAL_ 1050 LpdbAuxBlwr_B_Rq 0 "Off" 1 "On" ;
VAL_ 1050 HtrCoreRearSov_D_Stat 0 "Off" 1 "On" 2 "FailedOff" 3 "FailedOn" 4 "FailedPositionNotKnown" 5 "NotUsed_1" 6 "NotUsed_2" 7 "NotUsed_3" ;
VAL_ 1050 CamraRearBttn_D_Stat 0 "Not_Pressed" 1 "Pressed" ;
VAL_ 1050 LpdbPtc3_B_Rq 0 "Off" 1 "On" ;
VAL_ 1050 LpdbPtc2_B_Rq 0 "Off" 1 "On" ;
VAL_ 1050 LpdbPtc1_B_Rq 0 "Off" 1 "On" ;
VAL_ 1050 LpdbHeatWiprPrk_B_Rq 0 "Off" 1 "On" ;
VAL_ 1050 CabnAmb_Te2_Actl 255 "Fault" ;
VAL_ 1050 RearDiffLck_D_RqDrv4 0 "Off" 1 "On" 2 "NoRequest" 3 "Faulty" ;
VAL_ 1052 AwdLeft_Tq_Est 4094 "Unknown" 4095 "Fault" ;
VAL_ 1052 AwdLeft_Tq_Rq 4094 "Unknown" 4095 "Fault" ;
VAL_ 1052 AwdRight_Tq_Est 4094 "Unknown" 4095 "Fault" ;
VAL_ 1052 AwdRight_Tq_Rq 4094 "Unknown" 4095 "Fault" ;
VAL_ 1052 AwdLck_Tq_Actl 4094 "Unknown" 4095 "Fault" ;
VAL_ 1052 AwdLckTqNeg_B_Actl 0 "Inactive" 1 "Active" ;
VAL_ 1052 AwdDcnntSlipTrgt_B_Rq 0 "NoRequest" 1 "Request" ;
VAL_ 1052 AwdCnnct_D_Stat 0 "Disconnected" 1 "Connected" 2 "Disconnecting" 3 "Connecting" ;
VAL_ 1054 AutoHoldSwMde_B_Ind 0 "Off" 1 "On" ;
VAL_ 1054 AutoHoldMsgTxt_D_Rq 0 "NoMessage" 1 "Message1" 2 "Message2" 3 "Message3" 4 "Message4" 5 "Message5" 6 "Message6" 7 "Message7" 8 "Message8" 9 "Message9" 10 "Message10" 11 "Message11" 12 "Message12" 13 "Message13" 14 "Message14" 15 "Message15" ;
VAL_ 1054 BrkDrvMde_D_Stat 0 "Normal" 1 "Sport" 2 "Snow_Wet" 3 "Track" 4 "DragOrMudAndSand" 5 "Baja" 6 "RockCrawl" 7 "Faulty" ;
VAL_ 1054 BrkMdeInhbt_B_RqDsply 0 "No" 1 "Yes" ;
VAL_ 1054 DrvSlipCtlMdeMsg_D_Rq 0 "NoMessage" 1 "Message1" 2 "Message2" 3 "Message3" 4 "Message4" 5 "Message5" 6 "Message6" 7 "Message7" 8 "Message8" 9 "Message9" 10 "Message10" 11 "Message11" 12 "Message12" 13 "Message13" 14 "Message14" 15 "Message15" 16 "Message16" 17 "Message17" 18 "Message18" 19 "Message19" 20 "Message20" 21 "Message21" 22 "Message22" 23 "Message23" 24 "Message24" 25 "Message25" 26 "Message26" 27 "Message27" 28 "Message28" 29 "Message29" 30 "Message30" 31 "Message31" ;
VAL_ 1054 AutoHoldMde_D_Ind 0 "Off" 1 "Indication_1" 2 "Indication_2" 3 "Indication_3" ;
VAL_ 1054 HdcOn_B_Ind 0 "Off" 1 "On" ;
VAL_ 1054 BrkBstrVac_D_Stat 0 "NoBoosterVacuumMonitor" 1 "BoosterVacSensor" 2 "BoosterVacEstimator" 3 "NotUsed" ;
VAL_ 1054 BrkLineLck_D_Stat 0 "Available" 1 "Initiated" 2 "Engaged" 3 "Off" 4 "NotAvailable" 5 "NotUsed_1" 6 "NotUsed_2" 7 "NotUsed_3" ;
VAL_ 1054 DrvSlipCtlOffLamp_D_Rq 0 "Off" 1 "On" 2 "Slow_Flash" 3 "Fast_Flash" ;
VAL_ 1054 BrkBstrLoLampOn_B_Rq 0 "Off" 1 "On" ;
VAL_ 1054 SelDrvMdeAwd_D_Rq 0 "NormalMode" 1 "Normal_2H" 2 "Normal_4A" 3 "Normal_4L" 4 "SportMode" 5 "TowHaulMode" 6 "GrassGravelSnow" 7 "EconomyMode" 8 "SandMode" 9 "MudRutsMode" 10 "RockCrawlMode" 11 "SportAdaptiveMode" 12 "HighSpeedDesertMode_Baja" 13 "NotAvailable" 14 "RoughRoadMode" 15 "TrackMode" 16 "EvNowMode" 17 "EvLaterChargeMode" 18 "DragMode" 19 "OnePedalDrive" 20 "CustomMode" 21 "NotUsed_8" 22 "NotUsed_9" 23 "NotUsed_10" 24 "NotUsed_11" 25 "NotUsed_12" 26 "NotUsed_13" 27 "NotUsed_14" 28 "NotUsed_15" 29 "NotUsed_16" 30 "NotUsed_17" 31 "Faulty" ;
VAL_ 1054 BrkPadMsgTxt_D_Rq 0 "Null" 1 "ReplacePads" 2 "PadsOk" 3 "Faulty" ;
VAL_ 1054 ApaBrk_D_Stat 0 "Closed" 1 "Open" 2 "Active" 3 "Denied" ;
VAL_ 1054 SelDrvMdeChassis_D_Rq 0 "NormalMode" 1 "NormalAdaptiveMode" 2 "EconomyMode" 3 "SportMode" 4 "SportAdaptiveMode" 5 "ComfortMode" 6 "ComfortAdaptiveMode" 7 "LowMuMode" 8 "MudAndRutsMode" 9 "SandMode" 10 "RockCrawlMode" 11 "TowHaulMode" 12 "HighSpeedDesertMode" 13 "TrackMode" 14 "RoughRoadMode" 15 "DragMode" 16 "OnePedalDrive" 17 "NotUsed4" 18 "NotUsed5" 19 "NotUsed6" 20 "NotUsed7" 21 "NotUsed8" 22 "NotUsed9" 23 "NotUsed10" 24 "NotUsed11" 25 "NotUsed12" 26 "NotUsed13" 27 "NotUsed14" 28 "NotUsed15" 29 "NotUsed16" 30 "NotUsed17" 31 "Faulty" ;
VAL_ 1054 OnePdlDrvDeny_B_Stat 0 "No" 1 "Yes" ;
VAL_ 1054 SelDrvMdeChassis2_D_Rq 0 "NormalMode" 1 "NormalAdaptiveMode" 2 "EconomyMode" 3 "SportMode" 4 "SportAdaptiveMode" 5 "ComfortMode" 6 "ComfortAdaptiveMode" 7 "LowMuMode" 8 "MudAndRutsMode" 9 "SandMode" 10 "RockCrawlMode" 11 "TowHaulMode" 12 "HighSpeedDesertMode" 13 "TrackMode" 14 "RoughRoadMode" 15 "DragMode" 16 "OnePedalDrive" 17 "NotUsed4" 18 "NotUsed5" 19 "NotUsed6" 20 "NotUsed7" 21 "NotUsed8" 22 "NotUsed9" 23 "NotUsed10" 24 "NotUsed11" 25 "NotUsed12" 26 "NotUsed13" 27 "NotUsed14" 28 "NotUsed15" 29 "NotUsed16" 30 "NotUsed17" 31 "Faulty" ;
VAL_ 1054 CtaBrk_D_Stat 0 "Closed" 1 "Open" 2 "Active" 3 "Denied" ;
VAL_ 1054 FrontDiffElckrOpen_B_Rq 0 "No" 1 "Yes" ;
VAL_ 1054 TrailCtlMsgTxt_D_Rq 0 "NoMessage" 1 "Message1" 2 "Message2" 3 "Message3" 4 "Message4" 5 "Message5" 6 "Message6" 7 "Message7" 8 "Message8" 9 "Message9" 10 "Message10" 11 "Message11" 12 "Message12" 13 "Message13" 14 "Message14" 15 "Message15" ;
VAL_ 1054 TrailCtl_D_Stat 0 "Off" 1 "EnabledDescent" 2 "Active" 3 "StandbyOverride" 4 "StandbyOverThreshold" 5 "EnabledDeny" 6 "DescentOnly" 7 "Faulty" ;
VAL_ 1054 TrailOnePdlTqLm_B_Actl 0 "No" 1 "Yes" ;
VAL_ 1054 SelDrvMdeChassis3_D_Rq 0 "NormalMode" 1 "NormalAdaptiveMode" 2 "EconomyMode" 3 "SportMode" 4 "SportAdaptiveMode" 5 "ComfortMode" 6 "ComfortAdaptiveMode" 7 "LowMuMode" 8 "MudAndRutsMode" 9 "SandMode" 10 "RockCrawlMode" 11 "TowHaulMode" 12 "HighSpeedDesertMode" 13 "TrackMode" 14 "RoughRoadMode" 15 "DragMode" 16 "OnePedalDrive" 17 "NotUsed4" 18 "NotUsed5" 19 "NotUsed6" 20 "NotUsed7" 21 "NotUsed8" 22 "NotUsed9" 23 "NotUsed10" 24 "NotUsed11" 25 "NotUsed12" 26 "NotUsed13" 27 "NotUsed14" 28 "NotUsed15" 29 "NotUsed16" 30 "NotUsed17" 31 "Faulty" ;
VAL_ 1054 RbaBrk_D_Stat 0 "Closed" 1 "Open" 2 "Active" 3 "Denied" ;
VAL_ 1055 EcoCochInstNeg_B_Dsply 0 "False" 1 "True" ;
VAL_ 1056 VehVActlBrk_No_Corr 254 "NoDataExists" 255 "Faulty" ;
VAL_ 1056 SelDrvMdeHmi03_D_Rq 0 "SelDrvMde01" 1 "SelDrvMde02" 2 "SelDrvMde03" 3 "SelDrvMde04" 4 "SelDrvMde05" 5 "SelDrvMde06" 6 "SelDrvMde07" 7 "SelDrvMde08" 8 "SelDrvMde09" 9 "SelDrvMde10" 10 "SelDrvMde11" 11 "SelDrvMde12" 12 "SelDrvMde13" 13 "SelDrvMde14" 14 "SelDrvMde15" 15 "SelDrvMde16" 16 "SelDrvMde17" 17 "SelDrvMde18" 18 "SelDrvMde19" 19 "SelDrvMde20" 20 "SelDrvMde21" 21 "SelDrvMde22" 22 "SelDrvMde23" 23 "SelDrvMde24" 24 "SelDrvMde25" 25 "SelDrvMde26" 26 "SelDrvMde27" 27 "SelDrvMde28" 28 "SelDrvMde29" 29 "SelDrvMde30" 30 "SelDrvMde31" 31 "Faulty" ;
VAL_ 1056 PrkBrkMsgTxt_D2_Rq 0 "No_Message" 1 "Message_1" 2 "Message_2" 3 "Message_3" 4 "Message_4" 5 "Message_5" 6 "Message_6" 7 "Message_7" ;
VAL_ 1056 SelDrvMdeMsgTxt_D_Rq 0 "NoMessage" 1 "Message1" 2 "Message2" 3 "Message3" 4 "Message4" 5 "Message5" 6 "Message6" 7 "Message7" 8 "Message8" 9 "Message9" 10 "Message10" 11 "Message11" 12 "Message12" 13 "Message13" 14 "Message14" 15 "Message15" ;
VAL_ 1056 SelDrvMdeMsgTxt2_D_Rq 0 "NoMessage" 1 "Message1" 2 "Message2" 3 "Message3" 4 "Message4" 5 "Message5" 6 "Message6" 7 "Message7" 8 "Message8" 9 "Message9" 10 "Message10" 11 "Message11" 12 "Message12" 13 "Message13" 14 "Message14" 15 "Message15" ;
VAL_ 1056 SelDrvMdePos01_B_Avail 0 "NotAvailable" 1 "Available" ;
VAL_ 1056 SelDrvMde_D_Stat 0 "NoDriveModeChangeRequest" 1 "DriveModeChangeSelection" 2 "DriveModeChangeRequest" 3 "NotUsed" ;
VAL_ 1056 SelDrvMdePt_D_Rq 0 "NormalMode" 1 "SportMode" 2 "NotAvailable_02" 3 "TowHaulMode" 4 "NotAvailable_04" 5 "GrassGravelSnow" 6 "EconomyMode" 7 "SandMode" 8 "MudRutsMode" 9 "RockCrawlMode" 10 "NotAvailable_10" 11 "NotAvailable_11" 12 "NotAvailable_12" 13 "NotAvailable_13" 14 "SportAdaptiveMode" 15 "HighSpeedDesertMode_Baja" 16 "DragMode" 17 "EvNowMode" 18 "EvLaterChargerMode" 19 "OnePedalDrive" 20 "TrackMode" 21 "CustomMode" 22 "ComfortMode" 23 "NotUsed_1" 24 "NotUsed_2" 25 "NotUsed_3" 26 "NotUsed_4" 27 "NotUsed_5" 28 "NotUsed_6" 29 "NotUsed_7" 30 "NotUsed_8" 31 "Faulty" ;
VAL_ 1056 SelDrvMdePos02_B_Avail 0 "NotAvailable" 1 "Available" ;
VAL_ 1056 AwdMde_D_RqBrk 0 "FourByTwo" 1 "FourByFourAuto" 2 "FourByFourHigh" 3 "FourByFourLow" 4 "Neutral" 5 "NoRequest" 6 "NotUsed2" 7 "Faulty" ;
VAL_ 1056 AutoEpbDsply_D_Stat 0 "NotAvailable" 1 "Available" 2 "GreyedOut" 3 "NotUsed" ;
VAL_ 1056 SelDrvMdePos10_B_Avail 0 "NotAvailable" 1 "Available" ;
VAL_ 1056 SelDrvMdePos09_B_Avail 0 "NotAvailable" 1 "Available" ;
VAL_ 1056 SelDrvMdePos08_B_Avail 0 "NotAvailable" 1 "Available" ;
VAL_ 1056 SelDrvMdePos07_B_Avail 0 "NotAvailable" 1 "Available" ;
VAL_ 1056 SelDrvMdePos06_B_Avail 0 "NotAvailable" 1 "Available" ;
VAL_ 1056 SelDrvMdePos05_B_Avail 0 "NotAvailable" 1 "Available" ;
VAL_ 1056 SelDrvMdePos04_B_Avail 0 "NotAvailable" 1 "Available" ;
VAL_ 1056 SelDrvMdePos03_B_Avail 0 "NotAvailable" 1 "Available" ;
VAL_ 1056 AutoEpbButtnOn_B_Stat 0 "Off" 1 "On" ;
VAL_ 1056 ActvDrvMde_D2_Stat 0 "SelDrvMde01" 1 "SelDrvMde02" 2 "SelDrvMde03" 3 "SelDrvMde04" 4 "SelDrvMde05" 5 "SelDrvMde06" 6 "SelDrvMde07" 7 "SelDrvMde08" 8 "SelDrvMde09" 9 "SelDrvMde10" 10 "SelDrvMde11" 11 "SelDrvMde12" 12 "SelDrvMde13" 13 "SelDrvMde14" 14 "SelDrvMde15" 15 "SelDrvMde16" 16 "SelDrvMde17" 17 "SelDrvMde18" 18 "SelDrvMde19" 19 "SelDrvMde20" 20 "SelDrvMde21" 21 "SelDrvMde22" 22 "SelDrvMde23" 23 "SelDrvMde24" 24 "SelDrvMde25" 25 "SelDrvMde26" 26 "SelDrvMde27" 27 "SelDrvMde28" 28 "SelDrvMde29" 29 "SelDrvMde30" 30 "SelDrvMde31" 31 "Faulty" ;
VAL_ 1056 SelDrvMdePos12_B_Avail 0 "NotAvailable" 1 "Available" ;
VAL_ 1056 SelDrvMdePos11_B_Avail 0 "NotAvailable" 1 "Available" ;
VAL_ 1056 AutoEpbMsgTxt_D_Rq 0 "NoMessage" 1 "Message1" 2 "Message2" 3 "Message3" 4 "Message4" 5 "Message5" 6 "Message6" 7 "Message7" ;
VAL_ 1056 SelDrvMde_D2_Rq 0 "SelDrvMde01" 1 "SelDrvMde02" 2 "SelDrvMde03" 3 "SelDrvMde04" 4 "SelDrvMde05" 5 "SelDrvMde06" 6 "SelDrvMde07" 7 "SelDrvMde08" 8 "SelDrvMde09" 9 "SelDrvMde10" 10 "SelDrvMde11" 11 "SelDrvMde12" 12 "SelDrvMde13" 13 "SelDrvMde14" 14 "SelDrvMde15" 15 "SelDrvMde16" 16 "SelDrvMde17" 17 "SelDrvMde18" 18 "SelDrvMde19" 19 "SelDrvMde20" 20 "SelDrvMde21" 21 "SelDrvMde22" 22 "SelDrvMde23" 23 "SelDrvMde24" 24 "SelDrvMde25" 25 "SelDrvMde26" 26 "SelDrvMde27" 27 "SelDrvMde28" 28 "SelDrvMde29" 29 "SelDrvMde30" 30 "SelDrvMde31" 31 "Faulty" ;
VAL_ 1057 FohEng_D_Rq 0 "Disable_Stop" 1 "AutoEnable_ParkDisable" 2 "AutoDisable_ParkEnable" 3 "AutoEnable_ParkEnable" ;
VAL_ 1057 ECMMILRequest 0 "Off" 1 "On" 2 "Flash" 3 "Not_Used" ;
VAL_ 1057 VehVLimStat_D_Actl 0 "Off" 1 "Standby" 2 "Active_but_Not_Limiting" 3 "Active_and_Limiting" 4 "ASL_Fault_Condition" 5 "Undefined_1" 6 "Undefined_2" 7 "Undefined_3" ;
VAL_ 1057 VehVLimActv_B_Actl 0 "Inactive" 1 "Active" ;
VAL_ 1057 EngIdlShutDown_D_Stat 0 "Normal_Operation" 1 "Initiated_Countdown" 2 "Engine_Shutdown" 3 "DelayShutdownActive" ;
VAL_ 1057 EngIdlShutDwnTxt_D_Rq 0 "NoMessage" 1 "FeatureDisabledDueToFault" 2 "EngineShutdownOnPrevDrive" 3 "NotUsed" ;
VAL_ 1057 OilPressureWarning 0 "Normal_Pressure_Lamp_Off" 1 "Low_Pressure_Lamp_On" ;
VAL_ 1057 CoolantFanStepAct 0 "Fan_Cmd_Off" 1 "Step1" 2 "Step2" 3 "Step3" 4 "Step4" 5 "Step5" 6 "Step6" 7 "Step7" 8 "Step8" 9 "Step9" 10 "Step10" 11 "Step11" 12 "Step12" 13 "Step13" 14 "Step14" 15 "Step15" 16 "Step16" 17 "Step17" 18 "Step18" 19 "Step19" 20 "Step20" 21 "Step21" 22 "Step22" 23 "Step23" 24 "Max_Fan_Speed_Req" 25 "Unused1" 26 "Unused2" 27 "Unused3" 28 "Unused4" 29 "Unused5" 30 "Unused6" 31 "Unused7" ;
VAL_ 1057 TrnTotLss_Tq_Est 254 "Unknown" 255 "Fault" ;
VAL_ 1057 TrnTotTq_Rt_Est 65534 "Unknown" 65535 "Fault" ;
VAL_ 1057 AirCondFluidHi_P_Actl 254 "Unknown" 255 "Fault" ;
VAL_ 1057 FUEL_ALCOHOL_PERCNT 255 "Invalid" ;
VAL_ 1059 Shed_Drain_Eng_Off_B 0 "Inactive" 1 "Active" ;
VAL_ 1059 PeriodicElLoad_B_Stat 0 "Inactive" 1 "Active" ;
VAL_ 1059 EngStrtInhbt_B_RqBatt 0 "Dont_Care" 1 "Start_Inhibit" ;
VAL_ 1059 IdleSpeedIncrease_El 0 "No" 1 "Yes" ;
VAL_ 1059 Batt_Crit_SoC_B 0 "Inactive" 1 "Active" ;
VAL_ 1059 Batt_Lo_SoC_B 0 "Inactive" 1 "Active" ;
VAL_ 1059 BattULoChrg_D_Rq 0 "No_Request" 1 "Chrg_Requested_HighCurrent" 2 "Charging_Requested" 3 "Low_Battery_Temperature" ;
VAL_ 1059 Shed_T_Eng_Off_B 0 "Inactive" 1 "Active" ;
VAL_ 1059 PwSysULoFalt_D_Stat 0 "No_Fault" 1 "Cluster_Proveout" 2 "Fault_Nonspecific" 3 "Fault_ReducedOutput" 4 "Fault_NoOutput" 5 "Overvoltage" 6 "LowBatt1_Warning" 7 "LowBatt2_PowerSaveMode" 8 "LowBattVoltDuringPwSrcOn" 9 "BattMonitoringSensorFault" 10 "Not_Used_2" 11 "Not_Used_3" 12 "Not_Used_4" 13 "PSS_Shed2_Contin" 14 "LowBatterySOC" 15 "Not_Used_6" ;
VAL_ 1059 ChargeMode 0 "Conventional_Charging" 1 "Slow_Regen_Allowed" 2 "Fast_Regen_Allowed" 3 "SlowRegenAllowNoDischarge" 4 "Battery_Refresh" 5 "Battery_Identify" 6 "Undefined_1" 7 "Undefined_2" ;
VAL_ 1059 Shed_Feature_Group_ID 0 "No_LSHED1_Features" 1 "Htd_Washer_Fluid" 2 "Htd_StrWhl" 3 "SmartTrlrTowBattCharge" 4 "HtdCoolSeat_RearDriver" 5 "HtdCoolSeat_RearPass" 6 "HtdCoolSeat_FrtPass" 7 "HtdCoolSeat_FrtDriver" 8 "HtdBcklight_HtdMirr" 9 "SpltHtdBcklight_HtdMirr" 10 "Htd_Windscrn" 11 "HvacRearBlwr_First" 12 "HvacRearBlwr_Second" 13 "HvacRearBlwr_Third" 14 "HtdMirr" 15 "Engine_Coolant_Fan" 16 "PtcHeater" 17 "UpFitter_1" 18 "UpFitter_2" 19 "UpFitter_3" 20 "UpFitter_4" 21 "UpFitter_5" 22 "UpFitter_6" 23 "Dcac" 24 "NotUsed_1" 25 "NotUsed_2" 26 "NotUsed_3" 27 "NotUsed_4" 28 "NotUsed_5" 29 "NotUsed_6" 30 "NotUsed_7" 31 "All_LSHED1_Features" ;
VAL_ 1059 Shed_Level_Req 0 "NO_SHED" 1 "SHED1" 2 "SHED2_TRANS" 3 "SHED2_CONTIN" 4 "SOON_ENG_OFF" 5 "SHED_ENG_OFF" 6 "Loads_On" 7 "SHED3" ;
VAL_ 1059 ULoRgenTestMde_B_Rq 0 "NoRequest" 1 "Request" ;
VAL_ 1060 BpedDrvMsgTxt_B_Dsply 0 "Off" 1 "On" ;
VAL_ 1060 RearDiffOil_Te_Actl 511 "Faulty" ;
VAL_ 1060 FuelLvlWarn_D_ActlEng 0 "OK" 1 "Low" 2 "VeryLow" 3 "DteLevel1MyKey" 4 "DteLevel2NonMyKey" 5 "DteLevel3" 6 "DteLevel4" 7 "DteLevel5Lowest" ;
VAL_ 1060 RearDiffOilTeWarn_B_Rq 0 "Off" 1 "On" ;
VAL_ 1060 EngExhMdeQuiet_D_Stat 0 "Null" 1 "LoudExhaust" 2 "QuietExhaust" 3 "Faulty" ;
VAL_ 1060 SelDrvMdePt_D_Stat 0 "NotAvailable" 1 "Available" 2 "TemporarilyNotAvailable" 3 "Faulty" ;
VAL_ 1068 TrlrAidMsgTxt_D_Rq 0 "NoMessage" 1 "Message1" 2 "Message2" 3 "Message3" 4 "Message4" 5 "Message5" 6 "Message6" 7 "Message7" 8 "Message8" 9 "Message9" 10 "Message10" 11 "Message11" 12 "Message12" 13 "Message13" 14 "Message14" 15 "Message15" 16 "Message16" 17 "Message17" 18 "Message18" 19 "Message19" 20 "Message20" 21 "Message21" 22 "Message22" 23 "Message23" 24 "Message24" 25 "Message25" 26 "Message26" 27 "Message27" 28 "Message28" 29 "Message29" 30 "Message30" 31 "Message31" ;
VAL_ 1069 EngAirIn_Te_Actl 1022 "Unknown" 1023 "Fault" ;
VAL_ 1069 EngMsgTxt_D_Rq 0 "No_Message" 1 "Power_Reduced_to_LowerTemp" 2 "Undefined_1" 3 "Undefined_2" ;
VAL_ 1069 ObdWarmUp_B_Complt 0 "No" 1 "Yes" ;
VAL_ 1069 EngOilMaint_B_Stat 0 "Off" 1 "On" ;
VAL_ 1069 ULoSrcOnPlg_B_Cmd 0 "Deactivate" 1 "Activate" ;
VAL_ 1069 TracKeyMdeEnbl_B_Stat 0 "Off" 1 "On" ;
VAL_ 1069 ReFuelSysStat_D_Dsply 0 "Null" 1 "Wait_To_Fuel" 2 "Refuel_Ready" 3 "Close_Fuel_Door" 4 "Refuel_Err" 5 "NotUsed1" 6 "NotUsed2" 7 "NotUsed3" ;
VAL_ 1069 GrllShtrPos_B_Falt 0 "No_Fault" 1 "Fault" ;
VAL_ 1069 GrllShtrPos_D_Cmd 0 "Fully_Closed" 1 "Position1" 2 "Position2" 3 "Position3" 4 "Position4" 5 "Position5" 6 "Position6" 7 "Position7" 8 "Position8" 9 "Position9" 10 "Position10" 11 "Position11" 12 "Position12" 13 "Position13" 14 "Position14" 15 "Fully_Open" ;
VAL_ 1069 SlMde_D_Stat 0 "Null" 1 "Auto_Mode" 2 "Manual_Mode" 3 "IsaNotConfigured" ;
VAL_ 1069 SlMde_D_RqDsply 0 "NoSpeed_LimiterSymbol" 1 "AutoSpeed_LimiterSymbol" 2 "ManualSpeed_LimiterSymbol" 3 "NotUsed" ;
VAL_ 1069 IsaOffst_D_Stat 0 "Zero" 1 "One" 2 "Two" 3 "Three" 4 "Four" 5 "Five" 6 "Six" 7 "Seven" 8 "Eight" 9 "Nine" 10 "Ten" 11 "Eleven" 12 "Twelve" 13 "Thirteen" 14 "Null" 15 "Faulty" ;
VAL_ 1071 CluPdlPosPcMeas_D_Qf 0 "Faulty" 1 "No_Data_Exists" 2 "Not_Within_Specifications" 3 "OK" ;
VAL_ 1071 EngMnfld3_P_Actl 254 "NoDataExists" 255 "Faulty" ;
VAL_ 1072 ePRNDL_MODE 0 "Off" 1 "On" ;
VAL_ 1072 NtrlTowMdeEnbl_B_RqDrv 0 "No" 1 "Yes" ;
VAL_ 1072 LscmbbStat_B_Actl 0 "Off" 1 "On" ;
VAL_ 1072 EngIdlShutDown_B_RqDrv 0 "No_Inibit" 1 "Inhibit" ;
VAL_ 1072 ManRgen_D_Rq 0 "No_Customer_Request" 1 "CustInitManExhFilterClean" 2 "NotUsed1" 3 "NotUsed2" ;
VAL_ 1072 MetricActv_B_Actl 0 "Inactive" 1 "Active" ;
VAL_ 1072 AccDeny_B_RqIpc 0 "No" 1 "Yes" ;
VAL_ 1072 OdometerMasterValue 16777215 "Invalid" ;
VAL_ 1072 DrvSlipCtlMde_D_Rq 0 "Default_Mode" 1 "App_Specific_Off_Mode_1" 2 "App_Specific_Off_Mode_2" 3 "App_Specific_Off_Mode_3" ;
VAL_ 1072 DrvSlipCtlMde_B_Rq2 0 "Not_Pressed" 1 "Pressed" ;
VAL_ 1072 AccEnbl_B_RqDrv 0 "Normal_Cruise" 1 "Adaptive_Cruise" ;
VAL_ 1072 Fda_B_Stat 0 "Off" 1 "On" ;
VAL_ 1072 TRAILER_BRAKE_CONFIG 0 "No" 1 "Yes" ;
VAL_ 1072 MetricActvTe_B_Actl 0 "Inactive" 1 "Active" ;
VAL_ 1072 Power_Liftgate_Mode_Cmd 0 "Disable" 1 "Enable" ;
VAL_ 1072 KeyTypeChngMykey_D_Rq 0 "None" 1 "Request_New_MyKey" 2 "Clear_All_MyKeys" 3 "Search_PE_BackupSlot" ;
VAL_ 1072 HaDsplyCpblty_B_Stat 0 "NotAvailable" 1 "Available" ;
VAL_ 1072 EngOilLife_B_RqReset 0 "No" 1 "Yes" ;
VAL_ 1072 FrostWarn_D_Stat 0 "Off" 1 "On_Red" 2 "On_Amber" 3 "NotUsed" ;
VAL_ 1072 StopStrtDrvMde_D_RqMnu 0 "StopStart_Selected" 1 "StopStart_Deselected" 2 "NotUsed1" 3 "NotUsed2" ;
VAL_ 1072 DrvPerfMde_D_Rq 0 "NoModeSelected" 1 "NotUsed" 2 "Normal" 3 "Sport" ;
VAL_ 1072 ReducedGuard_D_Rq 0 "Null" 1 "Off" 2 "On" 3 "Person_Inside_DSIS" ;
VAL_ 1072 ParkDetect_Stat 0 "Not_Park" 1 "Park" ;
VAL_ 1072 HsaMde_D_Rq 0 "Off" 1 "Automatic" 2 "Manual" 3 "Undefined" ;
VAL_ 1072 BulbChkActv_B_Stat 0 "Inactive" 1 "Active" ;
VAL_ 1072 TRLR_SWAY_CONFIG_CMD 0 "Off" 1 "On" ;
VAL_ 1072 TrlrBrkMde_D_Rq 0 "Electric" 1 "ElectricOverHydraulic" ;
VAL_ 1072 PtDrvMde_D_Rq 0 "Normal" 1 "Sport" 2 "SnowWet" 3 "TowHaulGradeAssist" 4 "Sand" 5 "Baja" 6 "Rock" 7 "Drag" 8 "Track" 9 "NotUsed6" 10 "NotUsed7" 11 "NotUsed8" 12 "NotUsed9" 13 "NotUsed10" 14 "NotUsed11" 15 "Faulty" ;
VAL_ 1072 PrkLckCtlEnbl_D_RqIpc 0 "Null" 1 "Rq_Disable" 2 "Rq_Enable" 3 "Rq_Towing" ;
VAL_ 1076 OdoTripRx_B_Actl 0 "No" 1 "Yes" ;
VAL_ 1076 FogLghtRearButtn_B_Rq 0 "NotPressed" 1 "Pressed" ;
VAL_ 1076 FogLghtFrontButtn_B_Rq 0 "NotPressed" 1 "Pressed" ;
VAL_ 1076 TirePReset_B_Rq 0 "Null" 1 "Reset" ;
VAL_ 1076 DieslFuelBio_B_ActlDrv 0 "Non_Biodiesel_User" 1 "Biodiesel_User" ;
VAL_ 1076 HILL_DESC_SW 0 "Off" 1 "On" ;
VAL_ 1076 AutoRgen_D_Rq 0 "No_Mode_Selected" 1 "AutExhFilterCleanON" 2 "AutExhFilterCleanOFF" 3 "NotUsed" ;
VAL_ 1076 FUEL_SENSOR_NUM 0 "Single_Sensor" 1 "Dual_Sensors" ;
VAL_ 1076 IpcGearDsplyRdy_B_Stat 0 "No" 1 "Yes" ;
VAL_ 1076 W2S_LAMP_OK 0 "No" 1 "Yes" ;
VAL_ 1076 DrvSlipCtlMde_B_RqMyKey 0 "Off" 1 "On" ;
VAL_ 1076 FuelSecndActv_B_Actl 0 "No" 1 "Yes" ;
VAL_ 1076 FuelLvlWarn_D_Actl 0 "OK" 1 "Low" 2 "VeryLow" 3 "NotUsed" ;
VAL_ 1084 BSFault 0 "No_Fault" 1 "Fault" ;
VAL_ 1084 BattULo2_Te_Actl 127 "Fault" ;
VAL_ 1084 BattULoState_D_Qlty 0 "Fault" 1 "Eval_In_Progress" 2 "Not_Within_Specifications" 3 "OK" ;
VAL_ 1086 AwdPtu_Te_Actl 255 "Faulty" ;
VAL_ 1086 FuelPumpPwr_B_Rq 0 "Off" 1 "On" ;
VAL_ 1086 ElLoadCtl_D_Rq 0 "No_Request" 1 "All_Possible_Loads_Off" 2 "AllDriverInvisibleLoadsOn" 3 "StdDriverInvisibleLoadsOn" 4 "HoldAllDrvrInvisibleLoads" 5 "Unused1" 6 "Unused2" 7 "Unused3" ;
VAL_ 1087 AdasLcObtclAbrt_B_Stat 0 "No" 1 "Yes" ;
VAL_ 1087 FapLcInhbt_B_Rq 0 "No" 1 "Yes" ;
VAL_ 1087 FapLcStopHold_B_Rq 0 "No" 1 "Yes" ;
VAL_ 1087 FapLcPrchgBrk_B_Rq 0 "No" 1 "Yes" ;
VAL_ 1087 FapLcObstcl_B_Stat 0 "No" 1 "Yes" ;
VAL_ 1087 FapLcMaxGrdInhbt_B_Stat 0 "No" 1 "Yes" ;
VAL_ 1087 FapLcMaxGrdAbrt_B_Stat 0 "No" 1 "Yes" ;
VAL_ 1087 FapLcActv_B_Stat 0 "No" 1 "Yes" ;
VAL_ 1087 BtsiShifInhbt_B_RqPt 0 "No" 1 "Yes" ;
VAL_ 1087 IgnOffInhbt_B_Stat 0 "No" 1 "Yes" ;
VAL_ 1087 CrnkInhbtHlthRate_B_Rq 0 "Fast" 1 "Slow" ;
VAL_ 1087 CrnkInhbtActv_B_Stat 0 "No" 1 "Yes" ;
VAL_ 1087 BattRgenLoDChrg_D_RqEng 0 "Open" 1 "Closed" 2 "Retain" 3 "Disable" ;
VAL_ 1087 BattRgenLoChrg_D_RqEng 0 "Open" 1 "Closed" 2 "Retain" 3 "Disable" ;
VAL_ 1087 TrlrRngeDsply_B_Stat 0 "Off" 1 "On" ;
VAL_ 1087 RepaLcGrdInhbt_B_Stat 0 "No" 1 "Yes" ;
VAL_ 1087 ClimtCool_D_RqPt 0 "Off" 1 "On" 2 "NotUsed_1" 3 "NotUsed_2" ;
VAL_ 1087 StrtInGearMsgTxt_D_Rq 0 "NoMessage" 1 "Message1" 2 "Message2" 3 "Message3" 4 "Message4" 5 "Message5" 6 "Message6" 7 "Message7" 8 "Message8" 9 "Message9" 10 "Message10" 11 "Message11" 12 "Message12" 13 "Message13" 14 "Message14" 15 "Message15" ;
VAL_ 1087 StopStrtCstm_D_Stat 0 "NotAvailable" 1 "Off" 2 "On" 3 "Faulty" ;
VAL_ 1087 SelDrvMdeCstmPt_D_Stat 0 "NormalMode" 1 "SportMode" 2 "NotAvailable_02" 3 "TowHaulMode" 4 "NotAvailable_04" 5 "GrassGravelSnow" 6 "EconomyMode" 7 "SandMode" 8 "MudRutsMode" 9 "RockCrawlMode" 10 "NotAvailable_10" 11 "NotAvailable_11" 12 "NotAvailable_12" 13 "NotAvailable_13" 14 "SportAdaptiveMode" 15 "HighSpeedDesertMode_Baja" 16 "DragMode" 17 "EvNowMode" 18 "EvLaterChargerMode" 19 "OnePedalDrive" 20 "TrackMode" 21 "CustomMode" 22 "ComfortMode" 23 "NotUsed_1" 24 "NotUsed_2" 25 "NotUsed_3" 26 "NotUsed_4" 27 "NotUsed_5" 28 "NotUsed_6" 29 "NotUsed_7" 30 "NotUsed_8" 31 "Faulty" ;
VAL_ 1087 DcacFaltMsgTxt_D2_Rq 0 "Ok" 1 "Overcurrent" 2 "Gfci" 3 "Temperature" 4 "AcOnOutput" 5 "FuelLow" 6 "BreakerA" 7 "BreakerB" 8 "BreakerC" 9 "PlugWarnDrive" 10 "PlugWarn" 11 "NotAvailable" 12 "Service" 13 "EngineRun" 14 "OvercurrentLP" 15 "HvacOn" 16 "HevDerate" 17 "PowerTakeoff" 18 "FirstRpsWarning" 19 "RpsResetWarning" 20 "RpsResetWarn_ChngDrvToPark" 21 "LowSocRpsWarning" 22 "RpsNewKeyCycleWarning" 23 "PpoUsageWhenVehlsCharging" 24 "DcacbOvercurrent" 25 "DcacbGfci" 26 "DcacbTemperature" 27 "DcacbAcOnOutput" 28 "DcacbNotAvailable" 29 "DcacbService" 30 "DcacbOvercurrentLp" 31 "IpcPlugWarnDrive" 32 "FrontTrnkPlgWarnFullPw" 33 "FrontTrnkPlgWarnDerate" 34 "FrontTrnkPlgWarnDertExceed" 35 "PPO_ESCL_Notification" 36 "PPO_ESCL_NotfnVFL_Error" 37 "VehOnOFFTransitionWarn" 38 "NotUsed_1" 39 "NotUsed_2" 40 "NotUsed_3" 41 "NotUsed_4" 42 "NotUsed_5" 43 "NotUsed_6" 44 "NotUsed_7" 45 "NotUsed_8" 46 "NotUsed_9" 47 "NotUsed_10" 48 "NotUsed_11" 49 "NotUsed_12" 50 "NotUsed_13" 51 "NotUsed_14" 52 "NotUsed_15" 53 "NotUsed_16" 54 "NotUsed_17" 55 "NotUsed_18" 56 "NotUsed_19" 57 "NotUsed_20" 58 "NotUsed_21" 59 "NotUsed_22" 60 "NotUsed_23" 61 "NotUsed_24" 62 "NotUsed_25" 63 "NotUsed_26" ;
VAL_ 1087 EngIdlShutDownT_D_Stat 0 "Null" 1 "IdleMinute_1" 2 "IdleMinutes_2" 3 "IdleMinutes_3" 4 "IdleMinutes_4" 5 "IdleMinutes_5" 6 "IdleMinutes_6" 7 "IdleMinutes_7" 8 "IdleMinutes_8" 9 "IdleMinutes_9" 10 "IdleMinutes_10" 11 "IdleMinutes_11" 12 "IdleMinutes_12" 13 "IdleMinutes_13" 14 "IdleMinutes_14" 15 "IdleMinutes_15" 16 "IdleMinutes_16" 17 "IdleMinutes_17" 18 "IdleMinutes_18" 19 "IdleMinutes_19" 20 "IdleMinutes_20" 21 "IdleMinutes_21" 22 "IdleMinutes_22" 23 "IdleMinutes_23" 24 "IdleMinutes_24" 25 "IdleMinutes_25" 26 "IdleMinutes_26" 27 "IdleMinutes_27" 28 "IdleMinutes_28" 29 "IdleMinutes_29" 30 "IdleMinutes_30" 31 "IdleMinutes_31" 32 "IdleMinutes_32" 33 "IdleMinutes_33" 34 "IdleMinutes_34" 35 "IdleMinutes_35" 36 "IdleMinutes_36" 37 "IdleMinutes_37" 38 "IdleMinutes_38" 39 "IdleMinutes_39" 40 "IdleMinutes_40" 41 "IdleMinutes_41" 42 "IdleMinutes_42" 43 "IdleMinutes_43" 44 "IdleMinutes_44" 45 "IdleMinutes_45" 46 "IdleMinutes_46" 47 "IdleMinutes_47" 48 "IdleMinutes_48" 49 "IdleMinutes_49" 50 "IdleMinutes_50" 51 "IdleMinutes_51" 52 "IdleMinutes_52" 53 "IdleMinutes_53" 54 "IdleMinutes_54" 55 "IdleMinutes_55" 56 "IdleMinutes_56" 57 "IdleMinutes_57" 58 "IdleMinutes_58" 59 "IdleMinutes_59" 60 "IdleMinutes_60" 61 "IdleMinutes_61" 62 "IdleMinutes_62" 63 "IdleMinutes_63" 64 "IdleMinutes_64" 65 "IdleMinutes_65" 66 "IdleMinutes_66" 67 "IdleMinutes_67" 68 "IdleMinutes_68" 69 "IdleMinutes_69" 70 "IdleMinutes_70" 71 "IdleMinutes_71" 72 "IdleMinutes_72" 73 "IdleMinutes_73" 74 "IdleMinutes_74" 75 "IdleMinutes_75" 76 "IdleMinutes_76" 77 "IdleMinutes_77" 78 "IdleMinutes_78" 79 "IdleMinutes_79" 80 "IdleMinutes_80" 81 "IdleMinutes_81" 82 "IdleMinutes_82" 83 "IdleMinutes_83" 84 "IdleMinutes_84" 85 "IdleMinutes_85" 86 "IdleMinutes_86" 87 "IdleMinutes_87" 88 "IdleMinutes_88" 89 "IdleMinutes_89" 90 "IdleMinutes_90" 91 "IdleMinutes_91" 92 "IdleMinutes_92" 93 "IdleMinutes_93" 94 "IdleMinutes_94" 95 "IdleMinutes_95" 96 "IdleMinutes_96" 97 "IdleMinutes_97" 98 "IdleMinutes_98" 99 "IdleMinutes_99" 100 "IdleMinutes_100" 101 "IdleMinutes_101" 102 "IdleMinutes_102" 103 "IdleMinutes_103" 104 "IdleMinutes_104" 105 "IdleMinutes_105" 106 "IdleMinutes_106" 107 "IdleMinutes_107" 108 "IdleMinutes_108" 109 "IdleMinutes_109" 110 "IdleMinutes_110" 111 "IdleMinutes_111" 112 "IdleMinutes_112" 113 "IdleMinutes_113" 114 "IdleMinutes_114" 115 "IdleMinutes_115" 116 "IdleMinutes_116" 117 "IdleMinutes_117" 118 "IdleMinutes_118" 119 "IdleMinutes_119" 120 "IdleMinutes_120" 121 "IdleMinutes_121" 122 "IdleMinutes_122" 123 "IdleMinutes_123" 124 "IdleMinutes_124" 125 "IdleMinutes_125" 126 "IdleMinutes_126" 127 "IdleMinutes_127" 128 "IdleMinutes_128" 129 "IdleMinutes_129" 130 "IdleMinutes_130" 131 "IdleMinutes_131" 132 "IdleMinutes_132" 133 "IdleMinutes_133" 134 "IdleMinutes_134" 135 "IdleMinutes_135" 136 "IdleMinutes_136" 137 "IdleMinutes_137" 138 "IdleMinutes_138" 139 "IdleMinutes_139" 140 "IdleMinutes_140" 141 "IdleMinutes_141" 142 "IdleMinutes_142" 143 "IdleMinutes_143" 144 "IdleMinutes_144" 145 "IdleMinutes_145" 146 "IdleMinutes_146" 147 "IdleMinutes_147" 148 "IdleMinutes_148" 149 "IdleMinutes_149" 150 "IdleMinutes_150" 151 "IdleMinutes_151" 152 "IdleMinutes_152" 153 "IdleMinutes_153" 154 "IdleMinutes_154" 155 "IdleMinutes_155" 156 "IdleMinutes_156" 157 "IdleMinutes_157" 158 "IdleMinutes_158" 159 "IdleMinutes_159" 160 "IdleMinutes_160" 161 "IdleMinutes_161" 162 "IdleMinutes_162" 163 "IdleMinutes_163" 164 "IdleMinutes_164" 165 "IdleMinutes_165" 166 "IdleMinutes_166" 167 "IdleMinutes_167" 168 "IdleMinutes_168" 169 "IdleMinutes_169" 170 "IdleMinutes_170" 171 "IdleMinutes_171" 172 "IdleMinutes_172" 173 "IdleMinutes_173" 174 "IdleMinutes_174" 175 "IdleMinutes_175" 176 "IdleMinutes_176" 177 "IdleMinutes_177" 178 "IdleMinutes_178" 179 "IdleMinutes_179" 180 "IdleMinutes_180" 181 "IdleMinutes_181" 182 "IdleMinutes_182" 183 "IdleMinutes_183" 184 "IdleMinutes_184" 185 "IdleMinutes_185" 186 "IdleMinutes_186" 187 "IdleMinutes_187" 188 "IdleMinutes_188" 189 "IdleMinutes_189" 190 "IdleMinutes_190" 191 "IdleMinutes_191" 192 "IdleMinutes_192" 193 "IdleMinutes_193" 194 "IdleMinutes_194" 195 "IdleMinutes_195" 196 "IdleMinutes_196" 197 "IdleMinutes_197" 198 "IdleMinutes_198" 199 "IdleMinutes_199" 200 "IdleMinutes_200" 201 "IdleMinutes_201" 202 "IdleMinutes_202" 203 "IdleMinutes_203" 204 "IdleMinutes_204" 205 "IdleMinutes_205" 206 "IdleMinutes_206" 207 "IdleMinutes_207" 208 "IdleMinutes_208" 209 "IdleMinutes_209" 210 "IdleMinutes_210" 211 "IdleMinutes_211" 212 "IdleMinutes_212" 213 "IdleMinutes_213" 214 "IdleMinutes_214" 215 "IdleMinutes_215" 216 "IdleMinutes_216" 217 "IdleMinutes_217" 218 "IdleMinutes_218" 219 "IdleMinutes_219" 220 "IdleMinutes_220" 221 "IdleMinutes_221" 222 "IdleMinutes_222" 223 "IdleMinutes_223" 224 "IdleMinutes_224" 225 "IdleMinutes_225" 226 "IdleMinutes_226" 227 "IdleMinutes_227" 228 "IdleMinutes_228" 229 "IdleMinutes_229" 230 "IdleMinutes_230" 231 "IdleMinutes_231" 232 "IdleMinutes_232" 233 "IdleMinutes_233" 234 "IdleMinutes_234" 235 "IdleMinutes_235" 236 "IdleMinutes_236" 237 "IdleMinutes_237" 238 "IdleMinutes_238" 239 "IdleMinutes_239" 240 "IdleMinutes_240" 241 "Selectable_Idle_Not_Active" 242 "Indefinite_Idle" 243 "NotUsed_1" 244 "NotUsed_2" 245 "NotUsed_3" 246 "NotUsed_4" 247 "NotUsed_5" 248 "NotUsed_6" 249 "NotUsed_7" 250 "NotUsed_8" 251 "NotUsed_9" 252 "NotUsed_10" 253 "NotUsed_11" 254 "NotUsed_12" 255 "NotUsed_13" ;
VAL_ 1087 StopStrtImccActv_D_St 0 "Off" 1 "OnNotActive" 2 "OnActive" 3 "OnSuspended" 4 "Deactivated" 5 "NotUsed_1" 6 "NotUsed_2" 7 "NotUsed_3" ;
VAL_ 1087 StopStrtImccTxt_D_Rq 0 "NoMessage" 1 "Message1" 2 "Message2" 3 "Message3" 4 "Message4" 5 "Message5" 6 "Message6" 7 "Message7" ;
VAL_ 1087 StopStrtImccTxt_D_Dspl 0 "NoMessage" 1 "Message1" 2 "Message2" 3 "Message3" 4 "Message4" 5 "Message5" 6 "Message6" 7 "Message7" 8 "Message8" 9 "Message9" 10 "Message10" 11 "Message11" 12 "Message12" 13 "Message13" 14 "Message14" 15 "Message15" ;
VAL_ 1088 ChrgStat_D2_Dsply 0 "NotReady" 1 "FaultInsideCar" 2 "FaultOutsideCar" 3 "EvseNotCompatible" 4 "EvseNotDetected" 5 "EvsePaused" 6 "ChargeScheduled" 7 "ChargingAC" 8 "ChargingDCFastCharge" 9 "ChargingInductive" 10 "ChargingSystemMaintain" 11 "CabinPreconditioning" 12 "DriveConditioning" 13 "ChargeTargetReached" 14 "ChargeStartCommanded" 15 "ChargeStopCommanded" ;
VAL_ 1088 BattDcChrgRms_I_Lim 32766 "NoDataExists" 32767 "Faulty" ;
VAL_ 1088 TrlrRng_L_Dsply 8190 "NoDataExists" 8191 "Faulty" ;
VAL_ 1088 HvacPrecondMode2_D_Rq 0 "Off" 1 "MAX_AC" 2 "Panel" 3 "Panel_Floor" 4 "Floor" 5 "Windshield_Floor" 6 "Windshield" 7 "Windshield_Panel" 8 "Windshield_Panel_Floor" 9 "Max_Defrost" 10 "Auto" 11 "Last_User_Settings" 12 "Low_Blower_Auto" 13 "NotUsed2" 14 "NotUsed3" 15 "NotUsed4" ;
VAL_ 1088 BattChrgInhbt_D_Rq 0 "Enable_Charging" 1 "InhibitChargingThermal" 2 "NotUsed" 3 "MaintainTargetSoc" ;
VAL_ 1088 ChrgTMatch_B_Stat 0 "False" 1 "True" ;
VAL_ 1088 HvacPrecondAC_D_Rq 0 "Off" 1 "On" 2 "Auto" 3 "Last_User_Setting" ;
VAL_ 1088 HvacPrecondBlwr2_D_Rq 0 "Off" 1 "Speed1" 2 "Speed2" 3 "Speed3" 4 "Speed4" 5 "Speed5" 6 "Speed6" 7 "Speed7" 8 "Auto" 9 "Last_User_Setting" 10 "NotUsed1" 11 "NotUsed2" 12 "NotUsed3" 13 "NotUsed4" 14 "NotUsed5" 15 "NotUsed6" ;
VAL_ 1088 HvacPrecondRecirc_D_Rq 0 "Outside" 1 "Recirc" 2 "Auto" 3 "Last_User_Setting" ;
VAL_ 1090 Inv1Ain_I_ActlMntr 32766 "NoDataExists" 32767 "Faulty" ;
VAL_ 1090 HybVehMde_D_ActlMntr 0 "Null" 1 "AllElectric" 2 "HybridElectric" 3 "Fuel" 4 "NotUsed_1" 5 "NotUsed_2" 6 "NoDataExists" 7 "Faulty" ;
VAL_ 1090 ChrgStat_D_ActlMntr 0 "Null" 1 "ChargingInParkingState" 2 "ChargingInDrivingState" 3 "NotCharging" 4 "ChargingCompleted" 5 "NotUsed" 6 "NoDataExists" 7 "Faulty" ;
VAL_ 1090 VehElRnge_L_Dsply 4094 "NoDataExists" 4095 "Fault" ;
VAL_ 1090 Mtr2State_D_ActlMntr 0 "Null" 1 "PowerConsumption" 2 "PowerGeneration" 3 "DeactivationState" 4 "ReadinessState" 5 "NotUsed_1" 6 "NoDataExists" 7 "Faulty" ;
VAL_ 1091 StopLampTrlrOut_B_Stat 0 "Null" 1 "Out" ;
VAL_ 1091 TrlrBattChrg_D_Stat 0 "Null" 1 "Low" 2 "Normal" 3 "Reverse" ;
VAL_ 1091 TrlrLampCtl_D_Stat 0 "Null" 1 "TrlrLampNotCnnctDrvFailure" 2 "TrlrLampCnnctDrvFailure" 3 "NotUsed" ;
VAL_ 1091 TurnLampTrlrRr_B_Stat 0 "Null" 1 "Out" ;
VAL_ 1091 TurnLampTrlrRl_B_Stat 0 "Null" 1 "Out" ;
VAL_ 1091 TrlrLampCnnct_B_Actl 0 "No" 1 "Yes" ;
VAL_ 1091 PoliceAux1Lamp_B_Rq2 0 "Off" 1 "On" ;
VAL_ 1091 CamraRearOn_D2_Stat2 0 "Null" 1 "Deactivate" 2 "Activate" 3 "Decommission" 4 "NotUsed_1" 5 "NotUsed_2" 6 "NotUsed_3" 7 "Faulty" ;
VAL_ 1091 TowBarMsgTxt_D_Rq 0 "Null" 1 "Check_Tow_Bar" 2 "Start_Engine_Swivel" 3 "Error_Dealer_Fix" 4 "TowBar_Ext_No_Trlr" 5 "NotUsed1" 6 "NotUsed2" 7 "NotUsed3" ;
VAL_ 1091 ParkLampTrlrOut_B_Stat 0 "Null" 1 "Out" ;
VAL_ 1091 WakeAlarm2_B_Typ 0 "CanOnly" 1 "CanAndEcuDriveCircuit" ;
VAL_ 1091 TrlrAlarmSpprt_D_Stat 0 "NotSupported" 1 "SupportedByBrakes" 2 "SupportedByLights" 3 "SupportedByBrakesAndLights" ;
VAL_ 1091 PoliceAux4Lamp_B_Rq2 0 "Off" 1 "On" ;
VAL_ 1091 PoliceAux3Lamp_B_Rq2 0 "Off" 1 "On" ;
VAL_ 1091 PoliceAux2Lamp_B_Rq2 0 "Off" 1 "On" ;
VAL_ 1092 BattTracInsltn_R_Actl 255 "Faulty" ;
VAL_ 1092 BattTracMnCell_Te_Actl 254 "NoDataExists" 255 "Faulty" ;
VAL_ 1092 BattTracMxCell_Te_Actl 254 "NoDataExists" 255 "Faulty" ;
VAL_ 1092 BattTracCell_U_Mn 16383 "Faulty" ;
VAL_ 1092 BattTracInsAlrm_B_Stat 0 "Inactive" 1 "Active" ;
VAL_ 1092 BattTracEq_B_Actl 0 "Inactive" 1 "Active" ;
VAL_ 1092 BattTracCell_U_Mx 16383 "Faulty" ;
VAL_ 1092 BattTracTeMx_B_Stat 0 "NotExceeded" 1 "Exceeded" ;
VAL_ 1092 BattTracTeMn_B_Stat 0 "NotExceeded" 1 "Exceeded" ;
VAL_ 1092 BattChrgOvrCurnt_B_Falt 0 "No" 1 "Yes" ;
VAL_ 1092 BattTracUMx_B_Stat 0 "Inactive" 1 "Active" ;
VAL_ 1092 BattTracUMn_B_Stat 0 "Inactive" 1 "Active" ;
VAL_ 1092 BattTracUAlrm_B_Stat 0 "Inactive" 1 "Active" ;
VAL_ 1093 TrlrBrkActCirct_B_Falt 0 "No" 1 "Yes" ;
VAL_ 1093 TrlrBrkMde_D_Actl 0 "Electric" 1 "Electric_Over_Hydraulic" ;
VAL_ 1093 TrlrBrkDsply_B_Rq 0 "No" 1 "Yes" ;
VAL_ 1093 TrlrBrkCtl_B_Falt 0 "No" 1 "Yes" ;
VAL_ 1093 TrlrBrkDcnnt_B_Actl 0 "No" 1 "Yes" ;
VAL_ 1093 TrlrBrkActCnnct_B_Actl 0 "No" 1 "Yes" ;
VAL_ 1093 StopLamp_B_RqTrlrBrk 0 "No" 1 "Yes" ;
VAL_ 1093 TrlBrkInitOut_D_Stat 0 "Null" 1 "Light" 2 "Medium" 3 "Heavy" ;
VAL_ 1095 PepsKeyActv_D_Stat 0 "NoKeyActive" 1 "Key1Active" 2 "Key2Active" 3 "NotUsed1" 4 "Key3Active" 5 "NotUsed2" 6 "NotUsed3" 7 "NotUsed4" 8 "Key4Active" 9 "NotUsed5" 10 "NotUsed6" 11 "NotUsed7" 12 "NotUsed8" 13 "NotUsed9" 14 "NotUsed10" 15 "NotUsed11" ;
VAL_ 1095 Pers1Phone_D_Stat 0 "NoPhoneAssociated" 1 "OnePhoneAssociated" 2 "TwoPhoneAssociated" 3 "ThreePhoneAssociated" 4 "FourPhoneAssociated" 5 "FivePhoneAssociated" 6 "SixPhoneAssociated" 7 "SevenPhoneAssociated" ;
VAL_ 1095 HeadLghtOn_D_Rq 0 "Off" 1 "Low" 2 "High" 3 "DrlLeft" 4 "DrlRight" 5 "DrlBoth" 6 "NotUsed1" 7 "NotUsed2" ;
VAL_ 1095 Pers3Phone_D_Stat 0 "NoPhoneAssociated" 1 "OnePhoneAssociated" 2 "TwoPhoneAssociated" 3 "ThreePhoneAssociated" 4 "FourPhoneAssociated" 5 "FivePhoneAssociated" 6 "SixPhoneAssociated" 7 "SevenPhoneAssociated" ;
VAL_ 1095 Pers2Phone_D_Stat 0 "NoPhoneAssociated" 1 "OnePhoneAssociated" 2 "TwoPhoneAssociated" 3 "ThreePhoneAssociated" 4 "FourPhoneAssociated" 5 "FivePhoneAssociated" 6 "SixPhoneAssociated" 7 "SevenPhoneAssociated" ;
VAL_ 1095 Pers4Phone_D_Stat 0 "NoPhoneAssociated" 1 "OnePhoneAssociated" 2 "TwoPhoneAssociated" 3 "ThreePhoneAssociated" 4 "FourPhoneAssociated" 5 "FivePhoneAssociated" 6 "SixPhoneAssociated" 7 "SevenPhoneAssociated" ;
VAL_ 1098 EdmMsgTxt_D_Rq 0 "NoMessage" 1 "GoodAcceleration" 2 "WorkOnAcceleration" 3 "GoodDeceleration" 4 "WorkOnDeceleration" 5 "GoodEfficientSpeed" 6 "WorkOnEfficientSpeed" 7 "GoodGearShifting" 8 "WorkOnGearShifting" 9 "GoodCompliance" 10 "WorkOnCompliance" 11 "OverallGoodScore" 12 "NotUsed_1" 13 "NotUsed_2" 14 "NotUsed_3" 15 "NotUsed_4" ;
VAL_ 1098 EdmLamp_D_Dsply 0 "NoRecommendation" 1 "FreewayExit" 2 "Crossing" 3 "SpeedLimit" 4 "Curve1" 5 "Curve2" 6 "FreewayJunction" 7 "CoastingShiftToNeutral" 8 "CoastingEngineBrake" 9 "NotUsed_1" 10 "NotUsed_2" 11 "NotUsed_3" 12 "NotUsed_4" 13 "NotUsed_5" 14 "NotUsed_6" 15 "NotUsed_7" ;
VAL_ 1098 EdmSailMdeOn_B_Stat 0 "Off" 1 "On" ;
VAL_ 1098 EdmCmplnc_B_Dsply 0 "No" 1 "Yes" ;
VAL_ 1098 WnchElComp_B_Actv 0 "No" 1 "Yes" ;
VAL_ 1098 DcacPwOn_D_Stat 0 "Off" 1 "On" 2 "Null" 3 "Not Used" ;
VAL_ 1098 AirDamPos_D_Stat 0 "Up" 1 "Down" 2 "NotUsed" 3 "Faulty" ;
VAL_ 1100 GrossTrainWeight_M_Est 254 "NoDataExists" 255 "Faulty" ;
VAL_ 1100 RearDiffSumpOil_Te_Est 254 "NoDataExists" 255 "Faulty" ;
VAL_ 1100 RearDiffLckMsg2_D_Rq 0 "NormalNoMessage_" 1 "LockerSpeed1" 2 "LockerSpeed2" 3 "LockerSpeed3" 4 "LockerSpeed4" 5 "LockerSpeed5" 6 "Locker_Enabled" 7 "Locker_Disabled" 8 "ElsdOverheated" 9 "ElsdRestored" 10 "EsldOff" 11 "LockingFeatureNotAvailable" 12 "ElsdReduced" 13 "NotUsed_1" 14 "NotUsed_2" 15 "NotUsed_3" ;
VAL_ 1100 RearDiffLckLamp_D_Rq2 0 "Off" 1 "On" 2 "Flash" 3 "Triggered" ;
VAL_ 1100 EngTrlrCnnct_D_Stat 0 "NoTrailer" 1 "HeavyTrailer" 2 "UnverifiedTrailer" 3 "NotUsed_1" ;
VAL_ 1100 AutoTowAllw_D_StatMnu 0 "NoSelection" 1 "AutoTowHaulDisabled" 2 "AutoTowHaulEnabled" 3 "TowHaulCommandedOn" ;
VAL_ 1100 EngExhMdeQuiet_D2_Stat 0 "Null" 1 "Stealth" 2 "Normal" 3 "Sport" 4 "Track" 5 "NotUsed_1" 6 "NotUsed_2" 7 "Faulty" ;
VAL_ 1100 SuspVlimMsgTxt_B_Rq 0 "No" 1 "Yes" ;
VAL_ 1100 SpareTireDetct_B_Stat 0 "False" 1 "True" ;
VAL_ 1100 RearDiffMtrRun_B_Stat 0 "NotAllowed" 1 "Allowed" ;
VAL_ 1100 HvacCmprLim_D_Stat 0 "NoLimit" 1 "ECT" 2 "RPM" 3 "PedalPosition" 4 "AvailableTorque" 5 "CompressorHeadPressure" 6 "NotUsed_1" 7 "NotUsed_2" ;
VAL_ 1100 TrailCtlPt_B_Falt 0 "NoFault" 1 "Fault" ;
VAL_ 1100 TrnNtrlIdlInhbt_B_Rq 0 "NoInhibit" 1 "Inhibit" ;
VAL_ 1100 TrnNtrlIdlExit_B_Rq 0 "Inactive" 1 "Active" ;
VAL_ 1100 AutoTowActv_B_Stat 0 "No" 1 "Yes" ;
VAL_ 1100 RvltnMatchAllw_D_Stat 0 "NoSelection" 1 "ChangeWithDriveMode" 2 "RevolutionMatchEnabled" 3 "RevolutionMatchDisabled" ;
VAL_ 1100 Veh_V_DsplyTrailCtlSet 63 "Faulty" ;
VAL_ 1100 WakeAlarm1_B_Typ 0 "CanOnly" 1 "CanAndEcuDriveCircuit" ;
VAL_ 1101 Ptu_Te_Actl 255 "Faulty" ;
VAL_ 1101 RearDiffLckLamp_D_Rq3 0 "Off" 1 "On" 2 "Flash" 3 "Triggered" ;
VAL_ 1101 AwdLckLamp_D_Rq 0 "Off" 1 "On" 2 "Flash" 3 "Triggered" ;
VAL_ 1101 PtLatchActv_B_RqAwd 0 "No" 1 "Yes" ;
VAL_ 1101 PtuFanOn_B_Rq 0 "Off" 1 "On" ;
VAL_ 1102 SelDrvMdePos02_D_Stat 0 "SelDrvMde01" 1 "SelDrvMde02" 2 "SelDrvMde03" 3 "SelDrvMde04" 4 "SelDrvMde05" 5 "SelDrvMde06" 6 "SelDrvMde07" 7 "SelDrvMde08" 8 "SelDrvMde09" 9 "SelDrvMde10" 10 "SelDrvMde11" 11 "SelDrvMde12" 12 "SelDrvMde13" 13 "SelDrvMde14" 14 "SelDrvMde15" 15 "SelDrvMde16" 16 "SelDrvMde17" 17 "SelDrvMde18" 18 "SelDrvMde19" 19 "SelDrvMde20" 20 "SelDrvMde21" 21 "SelDrvMde22" 22 "SelDrvMde23" 23 "SelDrvMde24" 24 "SelDrvMde25" 25 "SelDrvMde26" 26 "SelDrvMde27" 27 "SelDrvMde28" 28 "SelDrvMde29" 29 "SelDrvMde30" 30 "SelDrvMde31" 31 "Faulty" ;
VAL_ 1102 SelDrvMdePos01_D_Stat 0 "SelDrvMde01" 1 "SelDrvMde02" 2 "SelDrvMde03" 3 "SelDrvMde04" 4 "SelDrvMde05" 5 "SelDrvMde06" 6 "SelDrvMde07" 7 "SelDrvMde08" 8 "SelDrvMde09" 9 "SelDrvMde10" 10 "SelDrvMde11" 11 "SelDrvMde12" 12 "SelDrvMde13" 13 "SelDrvMde14" 14 "SelDrvMde15" 15 "SelDrvMde16" 16 "SelDrvMde17" 17 "SelDrvMde18" 18 "SelDrvMde19" 19 "SelDrvMde20" 20 "SelDrvMde21" 21 "SelDrvMde22" 22 "SelDrvMde23" 23 "SelDrvMde24" 24 "SelDrvMde25" 25 "SelDrvMde26" 26 "SelDrvMde27" 27 "SelDrvMde28" 28 "SelDrvMde29" 29 "SelDrvMde30" 30 "SelDrvMde31" 31 "Faulty" ;
VAL_ 1102 SelDrvMdePos03_D_Stat 0 "SelDrvMde01" 1 "SelDrvMde02" 2 "SelDrvMde03" 3 "SelDrvMde04" 4 "SelDrvMde05" 5 "SelDrvMde06" 6 "SelDrvMde07" 7 "SelDrvMde08" 8 "SelDrvMde09" 9 "SelDrvMde10" 10 "SelDrvMde11" 11 "SelDrvMde12" 12 "SelDrvMde13" 13 "SelDrvMde14" 14 "SelDrvMde15" 15 "SelDrvMde16" 16 "SelDrvMde17" 17 "SelDrvMde18" 18 "SelDrvMde19" 19 "SelDrvMde20" 20 "SelDrvMde21" 21 "SelDrvMde22" 22 "SelDrvMde23" 23 "SelDrvMde24" 24 "SelDrvMde25" 25 "SelDrvMde26" 26 "SelDrvMde27" 27 "SelDrvMde28" 28 "SelDrvMde29" 29 "SelDrvMde30" 30 "SelDrvMde31" 31 "Faulty" ;
VAL_ 1102 SelDrvMdePos05_D_Stat 0 "SelDrvMde01" 1 "SelDrvMde02" 2 "SelDrvMde03" 3 "SelDrvMde04" 4 "SelDrvMde05" 5 "SelDrvMde06" 6 "SelDrvMde07" 7 "SelDrvMde08" 8 "SelDrvMde09" 9 "SelDrvMde10" 10 "SelDrvMde11" 11 "SelDrvMde12" 12 "SelDrvMde13" 13 "SelDrvMde14" 14 "SelDrvMde15" 15 "SelDrvMde16" 16 "SelDrvMde17" 17 "SelDrvMde18" 18 "SelDrvMde19" 19 "SelDrvMde20" 20 "SelDrvMde21" 21 "SelDrvMde22" 22 "SelDrvMde23" 23 "SelDrvMde24" 24 "SelDrvMde25" 25 "SelDrvMde26" 26 "SelDrvMde27" 27 "SelDrvMde28" 28 "SelDrvMde29" 29 "SelDrvMde30" 30 "SelDrvMde31" 31 "Faulty" ;
VAL_ 1102 SelDrvMdePos04_D_Stat 0 "SelDrvMde01" 1 "SelDrvMde02" 2 "SelDrvMde03" 3 "SelDrvMde04" 4 "SelDrvMde05" 5 "SelDrvMde06" 6 "SelDrvMde07" 7 "SelDrvMde08" 8 "SelDrvMde09" 9 "SelDrvMde10" 10 "SelDrvMde11" 11 "SelDrvMde12" 12 "SelDrvMde13" 13 "SelDrvMde14" 14 "SelDrvMde15" 15 "SelDrvMde16" 16 "SelDrvMde17" 17 "SelDrvMde18" 18 "SelDrvMde19" 19 "SelDrvMde20" 20 "SelDrvMde21" 21 "SelDrvMde22" 22 "SelDrvMde23" 23 "SelDrvMde24" 24 "SelDrvMde25" 25 "SelDrvMde26" 26 "SelDrvMde27" 27 "SelDrvMde28" 28 "SelDrvMde29" 29 "SelDrvMde30" 30 "SelDrvMde31" 31 "Faulty" ;
VAL_ 1102 SelDrvMdePos06_D_Stat 0 "SelDrvMde01" 1 "SelDrvMde02" 2 "SelDrvMde03" 3 "SelDrvMde04" 4 "SelDrvMde05" 5 "SelDrvMde06" 6 "SelDrvMde07" 7 "SelDrvMde08" 8 "SelDrvMde09" 9 "SelDrvMde10" 10 "SelDrvMde11" 11 "SelDrvMde12" 12 "SelDrvMde13" 13 "SelDrvMde14" 14 "SelDrvMde15" 15 "SelDrvMde16" 16 "SelDrvMde17" 17 "SelDrvMde18" 18 "SelDrvMde19" 19 "SelDrvMde20" 20 "SelDrvMde21" 21 "SelDrvMde22" 22 "SelDrvMde23" 23 "SelDrvMde24" 24 "SelDrvMde25" 25 "SelDrvMde26" 26 "SelDrvMde27" 27 "SelDrvMde28" 28 "SelDrvMde29" 29 "SelDrvMde30" 30 "SelDrvMde31" 31 "Faulty" ;
VAL_ 1102 SelDrvMdePos12_D_Stat 0 "SelDrvMde01" 1 "SelDrvMde02" 2 "SelDrvMde03" 3 "SelDrvMde04" 4 "SelDrvMde05" 5 "SelDrvMde06" 6 "SelDrvMde07" 7 "SelDrvMde08" 8 "SelDrvMde09" 9 "SelDrvMde10" 10 "SelDrvMde11" 11 "SelDrvMde12" 12 "SelDrvMde13" 13 "SelDrvMde14" 14 "SelDrvMde15" 15 "SelDrvMde16" 16 "SelDrvMde17" 17 "SelDrvMde18" 18 "SelDrvMde19" 19 "SelDrvMde20" 20 "SelDrvMde21" 21 "SelDrvMde22" 22 "SelDrvMde23" 23 "SelDrvMde24" 24 "SelDrvMde25" 25 "SelDrvMde26" 26 "SelDrvMde27" 27 "SelDrvMde28" 28 "SelDrvMde29" 29 "SelDrvMde30" 30 "SelDrvMde31" 31 "Faulty" ;
VAL_ 1102 SelDrvMdePos07_D_Stat 0 "SelDrvMde01" 1 "SelDrvMde02" 2 "SelDrvMde03" 3 "SelDrvMde04" 4 "SelDrvMde05" 5 "SelDrvMde06" 6 "SelDrvMde07" 7 "SelDrvMde08" 8 "SelDrvMde09" 9 "SelDrvMde10" 10 "SelDrvMde11" 11 "SelDrvMde12" 12 "SelDrvMde13" 13 "SelDrvMde14" 14 "SelDrvMde15" 15 "SelDrvMde16" 16 "SelDrvMde17" 17 "SelDrvMde18" 18 "SelDrvMde19" 19 "SelDrvMde20" 20 "SelDrvMde21" 21 "SelDrvMde22" 22 "SelDrvMde23" 23 "SelDrvMde24" 24 "SelDrvMde25" 25 "SelDrvMde26" 26 "SelDrvMde27" 27 "SelDrvMde28" 28 "SelDrvMde29" 29 "SelDrvMde30" 30 "SelDrvMde31" 31 "Faulty" ;
VAL_ 1102 SelDrvMdePos11_D_Stat 0 "SelDrvMde01" 1 "SelDrvMde02" 2 "SelDrvMde03" 3 "SelDrvMde04" 4 "SelDrvMde05" 5 "SelDrvMde06" 6 "SelDrvMde07" 7 "SelDrvMde08" 8 "SelDrvMde09" 9 "SelDrvMde10" 10 "SelDrvMde11" 11 "SelDrvMde12" 12 "SelDrvMde13" 13 "SelDrvMde14" 14 "SelDrvMde15" 15 "SelDrvMde16" 16 "SelDrvMde17" 17 "SelDrvMde18" 18 "SelDrvMde19" 19 "SelDrvMde20" 20 "SelDrvMde21" 21 "SelDrvMde22" 22 "SelDrvMde23" 23 "SelDrvMde24" 24 "SelDrvMde25" 25 "SelDrvMde26" 26 "SelDrvMde27" 27 "SelDrvMde28" 28 "SelDrvMde29" 29 "SelDrvMde30" 30 "SelDrvMde31" 31 "Faulty" ;
VAL_ 1102 SelDrvMdePos09_D_Stat 0 "SelDrvMde01" 1 "SelDrvMde02" 2 "SelDrvMde03" 3 "SelDrvMde04" 4 "SelDrvMde05" 5 "SelDrvMde06" 6 "SelDrvMde07" 7 "SelDrvMde08" 8 "SelDrvMde09" 9 "SelDrvMde10" 10 "SelDrvMde11" 11 "SelDrvMde12" 12 "SelDrvMde13" 13 "SelDrvMde14" 14 "SelDrvMde15" 15 "SelDrvMde16" 16 "SelDrvMde17" 17 "SelDrvMde18" 18 "SelDrvMde19" 19 "SelDrvMde20" 20 "SelDrvMde21" 21 "SelDrvMde22" 22 "SelDrvMde23" 23 "SelDrvMde24" 24 "SelDrvMde25" 25 "SelDrvMde26" 26 "SelDrvMde27" 27 "SelDrvMde28" 28 "SelDrvMde29" 29 "SelDrvMde30" 30 "SelDrvMde31" 31 "Faulty" ;
VAL_ 1102 SelDrvMdePos10_D_Stat 0 "SelDrvMde01" 1 "SelDrvMde02" 2 "SelDrvMde03" 3 "SelDrvMde04" 4 "SelDrvMde05" 5 "SelDrvMde06" 6 "SelDrvMde07" 7 "SelDrvMde08" 8 "SelDrvMde09" 9 "SelDrvMde10" 10 "SelDrvMde11" 11 "SelDrvMde12" 12 "SelDrvMde13" 13 "SelDrvMde14" 14 "SelDrvMde15" 15 "SelDrvMde16" 16 "SelDrvMde17" 17 "SelDrvMde18" 18 "SelDrvMde19" 19 "SelDrvMde20" 20 "SelDrvMde21" 21 "SelDrvMde22" 22 "SelDrvMde23" 23 "SelDrvMde24" 24 "SelDrvMde25" 25 "SelDrvMde26" 26 "SelDrvMde27" 27 "SelDrvMde28" 28 "SelDrvMde29" 29 "SelDrvMde30" 30 "SelDrvMde31" 31 "Faulty" ;
VAL_ 1102 SelDrvMdePos08_D_Stat 0 "SelDrvMde01" 1 "SelDrvMde02" 2 "SelDrvMde03" 3 "SelDrvMde04" 4 "SelDrvMde05" 5 "SelDrvMde06" 6 "SelDrvMde07" 7 "SelDrvMde08" 8 "SelDrvMde09" 9 "SelDrvMde10" 10 "SelDrvMde11" 11 "SelDrvMde12" 12 "SelDrvMde13" 13 "SelDrvMde14" 14 "SelDrvMde15" 15 "SelDrvMde16" 16 "SelDrvMde17" 17 "SelDrvMde18" 18 "SelDrvMde19" 19 "SelDrvMde20" 20 "SelDrvMde21" 21 "SelDrvMde22" 22 "SelDrvMde23" 23 "SelDrvMde24" 24 "SelDrvMde25" 25 "SelDrvMde26" 26 "SelDrvMde27" 27 "SelDrvMde28" 28 "SelDrvMde29" 29 "SelDrvMde30" 30 "SelDrvMde31" 31 "Faulty" ;
VAL_ 1104 DrvCamDrvIR_D_Stat 0 "TemporaryUnavailable" 1 "Ok" 2 "Blocked" 3 "Faulty" ;
VAL_ 1104 DrvAttentZone_D_Stat 0 "NotDetermined" 1 "Other" 2 "FrontWindshield" 3 "Cluster" 4 "Infotainment" 5 "PassengerSideMirror" 6 "RearviewMirror" 7 "DriverSideMirror" 8 "DriverSideWindow" 9 "PassengerSideWindow" 10 "DriverLap" 11 "NotConfigured" 12 "PassengerWindshield" 13 "EyesClosed" 14 "HeadsDisplay" 15 "Faulty" ;
VAL_ 1104 DrvAlertSt_D_Stat 0 "NotDetermined" 1 "EyesOnRoad" 2 "EyesOffRoad" 3 "Faulty" ;
VAL_ 1104 DrvEngLvlConfid_D_Stat 0 "NotDetermined" 1 "Low" 2 "LowMedium" 3 "Medium" 4 "MediumHigh" 5 "High" 6 "NotUsed" 7 "Faulty" ;
VAL_ 1104 DrvEngageLevel_D_Stat 0 "NotDetermined" 1 "Invalid" 2 "Attentive" 3 "Distracted" 4 "Disengaged" 5 "NotUsed_1" 6 "NotUsed_2" 7 "Faulty" ;
VAL_ 1104 DrvCamera_D_Stat 0 "TemporaryUnavailable" 1 "Ok" 2 "Blocked" 3 "Faulty" ;
VAL_ 1104 DrvImpairLvl_D_Stat 0 "NotDetermined" 1 "Alert" 2 "LeastDrowsy" 3 "Drowsy_2" 4 "Drowsy_3" 5 "Drowsy_4" 6 "MostDrowsy" 7 "Microsleep" 8 "Asleep" 9 "Incapacitated" 10 "NotUsed_1" 11 "NotUsed_2" 12 "NotUsed_3" 13 "NotUsed_4" 14 "NotUsed_5" 15 "Faulty" ;
VAL_ 1104 DrvCamPassIR_D_Stat 0 "TemporaryUnavailable" 1 "Ok" 2 "Blocked" 3 "Faulty" ;
VAL_ 1104 DrvImpLvlConfid_D_Stat 0 "NotDetermined" 1 "Low" 2 "LowMedium" 3 "Medium" 4 "MediumHigh" 5 "High" 6 "NotUsed" 7 "Faulty" ;
VAL_ 1105 TrlrAidEnbl_D_RqAdas 0 "Inactive" 1 "ActiveTba" 2 "NotAvailable" 3 "Deactivate" 4 "NotUsed_1" 5 "NotUsed_2" 6 "NotUsed_3" 7 "NotUsed_4" ;
VAL_ 1105 CamraFrntStat_D_Stat 0 "Off" 1 "On" 2 "NotUsed" 3 "No_Data_Present" ;
VAL_ 1105 BrkDecel_B_RqRba 0 "Disable" 1 "Enable" ;
VAL_ 1105 RbaMnu_D_Rq 0 "None" 1 "Inactive" 2 "Active" 3 "NotUsed" ;
VAL_ 1105 RbaAlrt_D_Dsply 0 "Off" 1 "Graphic" 2 "Text" 3 "Both" ;
VAL_ 1105 Rba_D_Stat 0 "Off" 1 "On" 2 "Disabled" 3 "NotUsed" ;
VAL_ 1105 TrlrHitchLamp_D_Rq2 0 "Off" 1 "On" ;
VAL_ 1105 TrlrRvrseEnbl_D2_Stat 0 "Inactive" 1 "TbaActive" 2 "TbaSetup" 3 "TbaOffTrgSetup" 4 "TbaOffTrgActive" 5 "TbaActiveExpertAvail" 6 "TbaActiveExpertActive" 7 "NotUsed" ;
VAL_ 1105 RbaMsg_D_Rq 0 "Null" 1 "Off" 2 "Unavailable" 3 "Faulty" ;
VAL_ 1105 BrkEnbl_B_RqRba 0 "Disable" 1 "Enable" ;
VAL_ 1105 ClrExitAsstActv_B_Rq 0 "Inactive" 1 "Active" ;
VAL_ 1105 CamraFrntOffRd_B_Stat 0 "Inactive" 1 "Active" ;
VAL_ 1105 TrlrRvrseMsgTxt_D2_Rq 0 "NoMessage" 1 "Message1" 2 "Message2" 3 "Message3" 4 "Message4" 5 "Message5" 6 "Message6" 7 "Message7" 8 "Message8" 9 "Message9" 10 "Message10" 11 "Message11" 12 "Message12" 13 "Message13" 14 "Message14" 15 "Message15" 16 "Message16" 17 "Message17" 18 "Message18" 19 "Message19" 20 "Message20" 21 "Message21" 22 "Message22" 23 "Message23" 24 "Message24" 25 "Message25" 26 "Message26" 27 "Message27" 28 "Message28" 29 "Message29" 30 "Message30" 31 "Message31" 47 "Message47" 63 "Message63" ;
VAL_ 1105 TrlrAidSwtchLamp_B_Rq 0 "Off" 1 "On" ;
VAL_ 1105 TrlrHitchIcon_D_Rq 0 "NoIcon" 1 "Icon1" 2 "Icon2" 3 "Icon3" 4 "Icon4" 5 "Icon5" 6 "Icon6" 7 "Icon7" 8 "Icon8" 9 "Icon9" 10 "Icon10" 11 "Icon11" 12 "Icon12" 13 "Icon13" 14 "Icon14" 15 "Icon15" ;
VAL_ 1105 TrlrHitchChime_D_Rq 0 "NoChime" 1 "TrailerFoundChime" 2 "ManeuveringReadyChime" 3 "StopNowChime" 4 "NonCriticalAlertChime" 5 "WarningChime" 6 "NotUsed_1" 7 "NotUsed_1" ;
VAL_ 1105 SpeedChngChime_D_Stat 0 "Null" 1 "Off" 2 "On" 3 "NotUsed" ;
VAL_ 1105 TrlrHitchMsgTxt_D_Rq 0 "NoMessage" 1 "Message1" 2 "Message2" 3 "Message3" 4 "Message4" 5 "Message5" 6 "Message6" 7 "Message7" 8 "Message8" 9 "Message9" 10 "Message10" 11 "Message11" 12 "Message12" 13 "Message13" 14 "Message14" 15 "Message15" 16 "Message16" 17 "Message17" 18 "Message18" 19 "Message19" 20 "Message20" 21 "Message21" 22 "Message22" 23 "Message23" 24 "Message24" 25 "Message25" 26 "Message26" 27 "Message27" 28 "Message28" 29 "Message29" 30 "Message30" 31 "Message31" 47 "Message47" 63 "Message63" ;
VAL_ 1105 ClrExitAsstMsgTxt2_D_Rq 0 "NoMessage" 1 "RearLeft" 2 "RearRight" 3 "FrontLeft" 4 "FrontRight" 5 "RearLeftRearRight" 6 "FrontLeftFrontRight" 7 "RearLeftFrontRight" 8 "FrontLeftRearRight" 9 "NotUsed_1" 10 "NotUsed_2" 11 "NotUsed_3" 12 "NotUsed_4" 13 "NotUsed_5" 14 "NotUsed_6" 15 "NotUsed_7" ;
VAL_ 1106 TrlrSnsId_No_Actl 2147483646 "NoDataExists_FFFFFFFFFFFE" 2147483647 "Faulty_FFFFFFFFFFFF" ;
VAL_ 1109 PassRstrnIndB_Stat 0 "Not_Supported" 1 "Normal" 2 "AirbagOn_Indicator_fault" 3 "AirbagOff_Indicator_fault" 4 "Both Indicators Faulted" 5 "Not_Used" 6 "Not_Used" 7 "Invalid" ;
VAL_ 1109 eCallConfirmation 0 "Normal" 1 "Call_In_Progress" 2 "Call_Completed" 3 "Call_Cancelled" 4 "Call_Unsuccessful" 5 "eCall_Configured_Off" 6 "CallComplete_DTMF_Timeout" 7 "Unused_2" ;
VAL_ 1109 PassRstrnIndA_D_Stat 0 "Not_Supported" 1 "Normal" 2 "AirbagOn_Indicator_Fault" 3 "AirbagOff_Indicator_Fault" 4 "BothIndicatorsFaulted" 5 "NotUsed" 6 "NotUsed" 7 "Invalid" ;
VAL_ 1109 DcacPwOn_D_RqMnu 0 "Off" 1 "On" 2 "Null" 3 "Not Used" ;
VAL_ 1112 BattTracIsoDis_B_Stat 0 "No" 1 "Yes" ;
VAL_ 1112 BattTracTeEvnt_B_Stat 0 "Inactive" 1 "Active" ;
VAL_ 1112 BattChrgTrgtEvnt_B_Stat 0 "Inactive" 1 "Active" ;
VAL_ 1112 BattTracChrgSustn_B_Rq 0 "Inactive" 1 "Active" ;
VAL_ 1112 HtrnClntPump_D_Stat 0 "Off" 1 "On" 2 "No_Data_Exists" 3 "Faulty" ;
VAL_ 1112 BattTracDcdcDis_B_Rq 0 "No" 1 "Yes" ;
VAL_ 1112 BattTracHvilOpen_B_Stat 0 "Closed" 1 "Open" ;
VAL_ 1112 BattTracCoolLvl_D_Rq 0 "Off" 1 "CoolantFlowBypassLine" 2 "OpportunisticCoolingRad" 3 "ForcedCoolingRadiator" 4 "ChillerCoolingCabinFirst" 5 "ChillerCoolingBattFirst" 6 "NotUsed" 7 "Faulty" ;
VAL_ 1112 BattDcCnnct_D_Cmd 0 "Open" 1 "Precharge" 2 "Closed" 3 "OkToDischarge" 4 "WeldCheck" 5 "NotUsed_1" 6 "NotUsed_2" 7 "NotUsed_3" ;
VAL_ 1112 BattTracDiagClr_B_Rq 0 "Off" 1 "On" ;
VAL_ 1112 BattTracCnnct_D_Cmd 0 "Open" 1 "Precharge" 2 "Closed" 3 "OkToDischarge" 4 "WeldCheck" 5 "NotUsed_1" 6 "NotUsed_2" 7 "NotUsed_3" ;
VAL_ 1112 BattTrac2_E_Avail 4094 "NoDataExists" 4095 "Faulty" ;
VAL_ 1112 BattTracClntPmp_D_Stat 0 "Off" 1 "On" 2 "No_Data_Exists" 3 "Faulty" ;
VAL_ 1112 BattTracHeat_D_Rq 0 "Off" 1 "On" 2 "NotUsed" 3 "Faulty" ;
VAL_ 1112 BattTrac2_E_Max 4094 "NoDataExists" 4095 "Faulty" ;
VAL_ 1112 BattTracHazrd_D_Stat 0 "NoHazardDetected" 1 "ExternalMonitoringRequired" 2 "HazardConfirmed" 3 "Disabled" ;
VAL_ 1112 BattTracDcFstSustn_B_Rq 0 "Inactive" 1 "Active" ;
VAL_ 1112 BattTracDelta_Te_Actl 254 "NoDataExists" 255 "Faulty" ;
VAL_ 1113 HitchToVehAxle_L_Calc 255 "Faulty" ;
VAL_ 1113 TrlrAid_AnRate2_Actl 1023 "Faulty" ;
VAL_ 1113 TrlrAid_An3_Actl 2047 "Faulty" ;
VAL_ 1113 TrlrAnOffstDir_D_Calc 0 "Null" 1 "Left_or_Center" 2 "Right" 3 "NotUSed" ;
VAL_ 1113 TrlrAnCalib_B_Complt 0 "No" 1 "Yes" ;
VAL_ 1113 TrlrRvrse_D_Stat 0 "Off" 1 "On" 2 "TrailerReverseGuidanceLite" 3 "Faulty" ;
VAL_ 1113 TrlrTrgtAcquire_D_Stat 0 "Null" 1 "TargetAcquired" 2 "TargetNotAcquired" 3 "Processing" 4 "RVCforTBA_Activated" 5 "NotUsed_1" 6 "NotUsed_2" 7 "Faulty" ;
VAL_ 1113 TrlrAid_D2_Stat 0 "NotTracking" 1 "Initializing" 2 "DriveStraighRequested" 3 "TurnRequested" 4 "TrackingLowConfidence" 5 "TrackingMediumConfidence" 6 "TrackingHighConfidence" 7 "TrackingUnknownConfidence" 8 "TrackingLost" 9 "IncorrectLighting" 10 "DirtyCamera" 11 "NotUsed_1" 12 "NotUsed_2" 13 "NotUsed_3" 14 "NotUsed_4" 15 "Faulty" ;
VAL_ 1114 TrailCtlSwtch_B_Stat2 0 "Not_Pressed" 1 "Pressed" ;
VAL_ 1114 TrlBrkInitOut_D_Rq 0 "Null" 1 "Light" 2 "Medium" 3 "Heavy" ;
VAL_ 1115 HudPersChng_D_Stat 0 "Null" 1 "Profile_Updated" 2 "Data_Lost" 3 "NotUsed_1" ;
VAL_ 1115 HUD_BTIncomingCall_Rq 0 "Inactive" 1 "AcceptIncomingCall" 2 "DeclineIncomingCall" ;
VAL_ 1115 HUD_TextMessage_Rq 0 "Invalid" 1 "Listen" 2 "Ignore" 3 "Cancel" ;
VAL_ 1115 HUD_BTEndTelService_Rq 0 "Inactive" 1 "EndOngoingTelephonyCall" ;
VAL_ 1115 HUD_BTInCallOptions_Rq 0 "Inactive" 1 "SwitchCalls" 2 "JoinCalls" 3 "GotoPrivacyMode" 4 "GotoHandsfreeMode" 5 "HoldCall" 6 "EndHoldCall" ;
VAL_ 1115 HudPersSrvc_D_Res 0 "Null" 1 "Success" 2 "Pending" 3 "Rejected" 4 "Interrupted" 5 "Failed" 6 "In_Prog" 7 "Invalid" 8 "NotUsed_1" 9 "NotUsed_2" 10 "NotUsed_3" 11 "NotUsed_4" 12 "NotUsed_5" 13 "NotUsed_6" 14 "NotUsed_7" 15 "Faulty" ;
VAL_ 1116 TrlrRvrseCancl_B_Rq 0 "Null" 1 "Cancel" ;
VAL_ 1116 TrlrAidSetup_D2_Rq 0 "Inactive" 1 "BeginSetup" 2 "EndSetup" 3 "ConfirmSetup" 4 "StickerNotCircled" 5 "ReturnToSetup" 6 "CompleteSetup" 7 "NotUsed_1" 8 "NotUsed_2" 9 "NotUsed_3" 10 "NotUsed_4" 11 "NotUsed_5" 12 "NotUsed_6" 13 "NotUsed_7" 14 "NotUsed_8" 15 "NotUsed_9" ;
VAL_ 1116 TrlrAidEnbl_D2_Rq 0 "Inactive" 1 "ActivateTba" 2 "ActivateTrg" 3 "Deactivate" 4 "NotUsed_1" 5 "NotUsed_2" 6 "NotUsed_3" 7 "NotUsed_4" ;
VAL_ 1116 TrlrAnOffstDir_D_Mem 0 "Null" 1 "Left_or_Center" 2 "Right" 3 "NotUSed" ;
VAL_ 1116 TlightTest_D_Mnu 0 "Null" 1 "StopTest" 2 "StartTest" 3 "TestEndAcknowledge" ;
VAL_ 1116 TrlrIdType_D_Stat 0 "Null" 1 "Conventional" 2 "FifthWheel" 3 "Gooseneck" ;
VAL_ 1120 HdcSwtchPos_B_Actl 0 "Not_Pressed" 1 "Pressed" ;
VAL_ 1120 AwdLck_D_RqDrv 0 "Off" 1 "On" 2 "NoRequest" 3 "Faulty" ;
VAL_ 1120 RearDiffLck_D_RqDrv 0 "Off" 1 "On" 2 "NoRequest" 3 "Faulty" ;
VAL_ 1120 AwdMde_D_RqDrv 0 "FourByTwo" 1 "FourByFourAuto" 2 "FourByFourHigh" 3 "FourByFourLow" 4 "Neutral" 5 "NoRequest" 6 "NotUsed2" 7 "Faulty" ;
VAL_ 1120 FrontDiffLck_D_RqDrv 0 "Off" 1 "On" 2 "NoRequest" 3 "Faulty" ;
VAL_ 1120 StabBarCnncButtn_D_Stat 0 "Not_Pressed" 1 "Pressed" 2 "NotUsed" 3 "Faulty" ;
VAL_ 1120 HybMdeSwtch_B_Rq 0 "Not_Pressed" 1 "Pressed" ;
VAL_ 1120 DrvSlipCtlMde_B_Rq3 0 "Not_Pressed" 1 "Pressed" ;
VAL_ 1120 TrailCtlSwtch_B_Stat3 0 "Not_Pressed" 1 "Pressed" ;
VAL_ 1121 StopStrtDrvMde_B_RqBtn2 0 "Not_Pressed" 1 "Pressed" ;
VAL_ 1121 SelDrvMdeSwtch_D_Stat 0 "NotPressed" 1 "SwitchState1" 2 "SwitchState2" 3 "Faulty" ;
VAL_ 1121 SelDrvMdeCnt_D_Stat 0 "ZeroCounts" 1 "OneCount" 2 "TwoCounts" 3 "ThreeCounts" 4 "FourCounts" 5 "FiveCounts" 6 "SixCounts" 7 "SevenOrMoreCounts" ;
VAL_ 1121 SelDrvMdeSwtchOk_D_Stat 0 "Null" 1 "NotPressed" 2 "Pressed" 3 "Faulty" ;
VAL_ 1121 AutoHoldSwtch_D_Stat2 0 "Not_Pressed" 1 "Pressed" 2 "NotUsed" 3 "Faulty" ;
VAL_ 1121 PrkAidSwtch_D_RqDrv3 0 "Not_Pressed" 1 "Pressed" ;
VAL_ 1121 ApaSwtch_D_RqDrv3 0 "Not_Pressed" 1 "Pressed" 2 "NotUsed1" 3 "NotUsed2" ;
VAL_ 1121 OrtaSwtch_D_Stat2 0 "Not_Pressed" 1 "Pressed" 2 "NotUsed" 3 "Faulty" ;
VAL_ 1121 OffRdSwtch_D_RqMnu 0 "Off" 1 "On" 2 "NoRequest" 3 "Faulty" ;
VAL_ 1122 GPS_Latitude_Degrees 254 "Unknown" 255 "Invalid" ;
VAL_ 1122 GpsHsphLongEast_D_Actl 0 "Invalid" 1 "Eastern" 2 "Western" 3 "Fault" ;
VAL_ 1122 GPS_Latitude_Minutes 62 "Unknown" 63 "Fault" ;
VAL_ 1122 GPS_Latitude_Min_dec 16382 "Unknown" 16383 "Invalid" ;
VAL_ 1122 GpsHsphLattSth_D_Actl 0 "Invalid" 1 "Southern" 2 "Northern" 3 "Fault" ;
VAL_ 1122 GPS_Longitude_Degrees 510 "Unknown" 511 "Fault" ;
VAL_ 1122 GPS_Longitude_Minutes 62 "Unknown" 63 "Fault" ;
VAL_ 1122 GPS_Longitude_Min_dec 16382 "Unknown" 16383 "Invalid" ;
VAL_ 1123 Gps_B_Falt 0 "No" 1 "Yes" ;
VAL_ 1123 GPS_UTC_hours 30 "Unknown" 31 "Invalid" ;
VAL_ 1123 GPS_UTC_minutes 62 "Unknown" 63 "Fault" ;
VAL_ 1123 GPS_UTC_seconds 62 "Unknown" 63 "Fault" ;
VAL_ 1123 GPS_Compass_direction 0 "North" 1 "NorthEast" 2 "East" 3 "SouthEast" 4 "South" 5 "SouthWest" 6 "West" 7 "NorthWest" ;
VAL_ 1123 GPS_Pdop 30 "Unknown" 31 "Invalid" ;
VAL_ 1123 GPS_Actual_vs_Infer_pos 0 "Actual_Postition" 1 "Inferred_Position" ;
VAL_ 1123 GpsUtcMnth_No_Actl 15 "Fault" ;
VAL_ 1123 GpsUtcYr_No_Actl 31 "Fault" ;
VAL_ 1124 GPS_dimension 0 "No_Fix" 1 "2D" 2 "3D" ;
VAL_ 1124 GPS_Sat_num_in_view 30 "Unknown" 31 "Invalid" ;
VAL_ 1124 GPS_MSL_altitude 4094 "Unknown" 4095 "Fault" ;
VAL_ 1124 GPS_Heading 65534 "Unknown" 65535 "Fault" ;
VAL_ 1124 GPS_Speed 254 "Unknown" 255 "Invalid" ;
VAL_ 1124 GPS_Hdop 30 "Unknown" 31 "Invalid" ;
VAL_ 1124 GPS_Vdop 30 "Unknown" 31 "Invalid" ;
VAL_ 1128 ChrgrSrvcRqd_B_Rq 0 "Off" 1 "On" ;
VAL_ 1128 ChrgrInPwMde_D_Actl 0 "EvseNotDetected" 1 "EvsePaused" 2 "DigitalCommDetected" 3 "AcBasic" 4 "AcDigital" 5 "DcCharging" 6 "IcCharging" 7 "EvseNotCompatible" 8 "EvseFault" 9 "DigitalCommEnd" 10 "DcBpt" 11 "NotUsed_1" 12 "NotUsed_2" 13 "NotUsed_3" 14 "NotUsed_4" 15 "NotUsed_5" ;
VAL_ 1128 ChrgCordLck_D_Stat 0 "Retain" 1 "Unlock" 2 "Lock" 3 "UnlockInProgress" 4 "LockInProgress" 5 "UnlockFail" 6 "LockFail" 7 "Faulty" ;
VAL_ 1128 BptTgl_B_Complt 0 "No" 1 "Yes" ;
VAL_ 1128 ChrgrClntFlw_D_Rq 0 "Off" 1 "Low" 2 "Medium" 3 "High" ;
VAL_ 1128 ChrgrAvailEvnt_B_Stat 0 "Inactive" 1 "Active" ;
VAL_ 1128 ChrgChngEvnt_B_Stat 0 "Inactive" 1 "Active" ;
VAL_ 1128 ChrgCrdLck_D_Falt 0 "NoFault" 1 "CsiFault" 2 "HardwareFault" 3 "NotUsed" ;
VAL_ 1128 ChrgrS2Swtch_B_Stat 0 "Open" 1 "Close" ;
VAL_ 1128 ChrgPortDrOpen_B_Stat 0 "False" 1 "True" ;
VAL_ 1128 CoolFanChrgr_D_Rq 0 "Off" 1 "Low" 2 "Medium" 3 "High" ;
VAL_ 1128 PlgStatEvnt_B_Stat 0 "Inactive" 1 "Active" ;
VAL_ 1128 ChrgrCnnctPwr_B_Stat 0 "NotAsserted" 1 "Asserted" ;
VAL_ 1128 DgtlCommGtwyMde_D_Rq 0 "NoDgtlComm" 1 "AttemptDgtlComm" 2 "DcEIM" 3 "DcPnC" 4 "AcEIM" 5 "AcPnC" 6 "NotUsed_1" 7 "NotUsed_2" 8 "NotUsed_3" 9 "NotUsed_4" 10 "NotUsed_5" 11 "NotUsed_6" 12 "NotUsed_7" 13 "NotUsed_8" 14 "NotUsed_9" 15 "NotUsed_10" ;
VAL_ 1128 ExtChrgNowButtn_B_Rq 0 "NoRequest" 1 "Request" ;
VAL_ 1128 ChrgrDcOvrVolt_B_Falt 0 "No" 1 "Yes" ;
VAL_ 1128 AcChrgRdy_B_Stat 0 "False" 1 "True" ;
VAL_ 1128 ChrgrDcOvrCurnt_B_Falt 0 "No" 1 "Yes" ;
VAL_ 1128 ChrgrPncEnbl_D_Stat 0 "Null" 1 "Disable" 2 "Enable" 3 "NotUsed" ;
VAL_ 1128 ChrgrCc2Cnnct_B_Falt 0 "No" 1 "Yes" ;
VAL_ 1128 ChrgPortDcTeMx_B_Falt 0 "No" 1 "Yes" ;
VAL_ 1134 AuxAirCond_B_Rq 0 "Reset" 1 "Off" 2 "On" 3 "Error" ;
VAL_ 1134 UpftrDgtlIn12_D_Stat 0 "Off" 1 "On" 2 "OutOfRange" 3 "NotUsed" ;
VAL_ 1134 UpftrDgtlIn11_D_Stat 0 "Off" 1 "On" 2 "OutOfRange" 3 "NotUsed" ;
VAL_ 1134 UpftrDgtlIn10_D_Stat 0 "Off" 1 "On" 2 "OutOfRange" 3 "NotUsed" ;
VAL_ 1134 EmgcyLghtSiren_B_Stat 0 "Off" 1 "On" ;
VAL_ 1134 UpftrEnbl_D_Stat 0 "Disabled" 1 "Requested" 2 "Enabled" 3 "Faulty" ;
VAL_ 1134 UpftrEngIdlShutDis_D_Rq 0 "NoRequest" 1 "Disable" 2 "Enable" 3 "NotUsed_1" ;
VAL_ 1134 EmgcyLght_D_RqUpftr 0 "Null" 1 "Deactivate" 2 "Activate" 3 "Faulty" ;
VAL_ 1134 WndwMovPsngr_D_Rq 0 "Idle" 1 "Manual_up" 2 "Auto_up" 3 "Manual_down" 4 "Auto_down" 5 "NotUsed_1" 6 "NotUsed_2" 7 "NotUsed_3" ;
VAL_ 1134 WndwMovDrv_D_Rq 0 "Idle" 1 "Manual_up" 2 "Auto_up" 3 "Manual_down" 4 "Auto_down" 5 "NotUsed_1" 6 "NotUsed_2" 7 "NotUsed_3" ;
VAL_ 1137 RngPerChrgAvg_L_Dsply 4094 "NoDataExists" 4095 "Faulty" ;
VAL_ 1137 RngPerChrgLbl_L_Dsply 4094 "NoDataExists" 4095 "Faulty" ;
VAL_ 1137 RngImpctDrv_Pc_Dsply 1023 "Faulty" ;
VAL_ 1137 RngImpctClim_Pc_Dsply 1023 "Faulty" ;
VAL_ 1137 RngImpctExt_Pc_Dsply 1023 "Faulty" ;
VAL_ 1137 RngImpctTot_Pc_Dsply 1023 "Faulty" ;
VAL_ 1138 BattChrgTrgtLMin_T_Est 2046 "NoDataExists" 2047 "Faulty" ;
VAL_ 1138 ActChrgEndMin_No_Actl 62 "Unknown" 63 "Invalid" ;
VAL_ 1138 ActChrgEndHr_No_Actl 30 "Unknown" 31 "Invalid" ;
VAL_ 1138 ActChrgEndDay_No_Actl 31 "Invalid" ;
VAL_ 1138 ActChrgEndMnth_No_Actl 15 "Invalid" ;
VAL_ 1138 ActChrgEndYr_No_Actl 31 "Invalid" ;
VAL_ 1139 BattChrgTrgtLMax_T_Est 2046 "NoDataExists" 2047 "Faulty" ;
VAL_ 1139 ActChrgStrtMin_No_Actl 62 "Unknown" 63 "Invalid" ;
VAL_ 1139 ActChrgStrtHr_No_Actl 30 "Unknown" 31 "Invalid" ;
VAL_ 1139 ActChrgStrtDay_No_Actl 31 "Invalid" ;
VAL_ 1139 ActChrgStrMnth_No_Actl 15 "Invalid" ;
VAL_ 1139 ActChrgStrtYr_No_Actl 31 "Invalid" ;
VAL_ 1140 BattTracPw_Pc_Avail 254 "NoDataExists" 255 "Faulty" ;
VAL_ 1140 RgenEvntLvl_Pc_Dsply 1022 "NoDataExists" 1023 "Fault" ;
VAL_ 1140 PreCondStat_D_Dsply 0 "Not_Scheduled" 1 "Scheduled" 2 "In_Progress" 3 "Complete" 4 "Faulted" 5 "Reserved1" 6 "Reserved2" 7 "Reserved3" ;
VAL_ 1140 ExtChrgrFalt_B_Dsply 0 "No" 1 "Yes" ;
VAL_ 1140 BrkEvntComplt_B_Dsply 0 "Off" 1 "On" ;
VAL_ 1140 RgenLongTerm_L_Dsply 16777214 "NoDataExists" 16777215 "Faulty" ;
VAL_ 1141 OfbChrgSetSync_D_Stat 0 "NoSyncInProgress" 1 "InProgress" 2 "Success" 3 "Fail" ;
VAL_ 1141 AirAmbTePlgIn_D_Dsply 0 "No_Plg_In_Msg" 1 "Cold_Outside_Plg_In_Msg" 2 "Hot_Outside_Plg_In_Msg" 3 "NotUsed" ;
VAL_ 1141 NxtUsg_D_Rq 0 "Invalid" 1 "Not_Requested" 2 "Requested" 3 "NotUsed" ;
VAL_ 1141 NtfctnConflict1_D_Rq 0 "Null" 1 "NoConflictExists" 2 "DepartureTime" 3 "ChargeWindow" 4 "NotUsed_1" 5 "NotUsed_2" 6 "NotUsed_3" 7 "NotUsed_4" ;
VAL_ 1141 ChrgLocGPS_D_Rq 0 "Inactive" 1 "Not_Requested" 2 "Requested" 3 "NotUsed" ;
VAL_ 1141 PtRmtRprt_D_Rq 0 "NoReportRequest" 1 "TripDistanceAchieved" 2 "VehiclePreconditioned" 3 "ChargeComplete" 4 "ChargeFault" 5 "LimitedPerformance" 6 "ReducedPerformance" 7 "BatteryTemperatureReminder" 8 "OneTimeSocReached" 9 "ChargeNotOccurring" 10 "FastChargeComplete" 11 "SettingUpdated" 12 "PlugInToMaintain12vBattery" 13 "NotUsed_2" 14 "NotUsed_3" 15 "NotUsed_4" ;
VAL_ 1142 ConsTipA_No_Dsply 1022 "NoDataExists" 1023 "Faulty" ;
VAL_ 1142 ConsTipMsg3_D_Dsply 0 "NoDisplay" 1 "Acceleration" 2 "Deceleration" 3 "VehicleSpeed" 4 "ClimateUsage" 5 "ReduceIdleTime" 6 "NotUsed1" 7 "NotUsed2" 8 "NotUsed3" 9 "NotUsed4" 10 "NotUsed5" 11 "NotUsed6" 12 "NotUsed7" 13 "NotUsed8" 14 "NotUsed9" 15 "NotUsed10" ;
VAL_ 1142 ConsTipDecel_No_Dsply 1022 "NoDataExists" 1023 "Faulty" ;
VAL_ 1142 ConsTipMsg2_D_Dsply 0 "NoDisplay" 1 "Acceleration" 2 "Deceleration" 3 "VehicleSpeed" 4 "ClimateUsage" 5 "ReduceIdleTime" 6 "NotUsed1" 7 "NotUsed2" 8 "NotUsed3" 9 "NotUsed4" 10 "NotUsed5" 11 "NotUsed6" 12 "NotUsed7" 13 "NotUsed8" 14 "NotUsed9" 15 "NotUsed10" ;
VAL_ 1142 ConsTipV_No_Dsply 1022 "NoDataExists" 1023 "Faulty" ;
VAL_ 1142 ConsTipMsg1_D_Dsply 0 "NoDisplay" 1 "Acceleration" 2 "Deceleration" 3 "VehicleSpeed" 4 "ClimateUsage" 5 "ReduceIdleTime" 6 "NotUsed1" 7 "NotUsed2" 8 "NotUsed3" 9 "NotUsed4" 10 "NotUsed5" 11 "NotUsed6" 12 "NotUsed7" 13 "NotUsed8" 14 "NotUsed9" 15 "NotUsed10" ;
VAL_ 1143 AirCondClntLo_Te_Actl 255 "Fault" ;
VAL_ 1143 AirCondFluidLo_P_Actl 254 "No data exists" 255 "Fault" ;
VAL_ 1143 ConsTipTot_Pc_Dsply 1022 "NoDataExists" 1023 "Faulty" ;
VAL_ 1143 ConsTipUnitPt_D_Dsply 0 "Percentage" 1 "Distance" 2 "FuelEconomy" 3 "NotUsed" ;
VAL_ 1143 ChrgCompltMsgTxt_D_Rq 0 "DefaultLabel" 1 "ChargeToFastChargeLimit" 2 "ChargeToFull" 3 "NotUsed_1" ;
VAL_ 1144 BattTracDrvSustn_B_Rq 0 "Inactive" 1 "Active" ;
VAL_ 1144 HtrnCnnctPwr_B_Stat 0 "NotAsserted" 1 "Asserted" ;
VAL_ 1144 PtcHtr_D_Stat 0 "Off" 1 "On" 2 "NotUsed" 3 "Faulty" ;
VAL_ 1144 HtrnClntFlw_D_Rq 0 "Off" 1 "Low" 2 "Medium" 3 "High" ;
VAL_ 1144 WakeAlarm0_B_Typ 0 "CanOnly" 1 "CanAndEcuDriveCircuit" ;
VAL_ 1144 ChrgNowEvnt_B_Stat 0 "Inactive" 1 "Active" ;
VAL_ 1144 CabinDrvSustn_B_Rq 0 "Inactive" 1 "Active" ;
VAL_ 1144 BrkAppl_D_RqPt 0 "NotActive" 1 "BrakesEngage" 2 "BrakesFastRelease" 3 "BrakesSlowRelease" ;
VAL_ 1144 HtrnDcdcDis_B_Rq 0 "No" 1 "Yes" ;
VAL_ 1144 BattTracChillerOn_B_Rq 0 "Off" 1 "On" ;
VAL_ 1144 BattTracChiller_D_Stat 0 "ChillerAvailable" 1 "ChillerBrieflyAvailable" 2 "ChillerNotAvailable" 3 "NotUsed" ;
VAL_ 1144 BattClntVlvOvrrd_D_Rq 0 "NoOverrideToTbcvCLogic" 1 "OverrideTbcvToRadiator" 2 "OverrideTbcvToChiller" 3 "NotUsed" ;
VAL_ 1144 PreCondBatt_B_Actl 0 "Off" 1 "On" ;
VAL_ 1144 BattChrgTrgtSoC_D_Rq 0 "Percent_100" 1 "Percent_95" 2 "Percent_90" 3 "Percent_85" 4 "Percent_80" 5 "Percent_70" 6 "Percent_60" 7 "Percent_50" ;
VAL_ 1144 HeatCoreSovRear_B_Rq 0 "Off" 1 "On" ;
VAL_ 1144 CabnEvapSovRear_B_Rq 0 "Off" 1 "On" ;
VAL_ 1144 CabnEvapSovFront_B_Rq 0 "Off" 1 "On" ;
VAL_ 1144 BattChlrSov_B_Rq 0 "Off" 1 "On" ;
VAL_ 1144 BattTracClimtDis_B_Stat 0 "Disable" 1 "Enable" ;
VAL_ 1144 ULoBattTrnsfrSustn_B_Rq 0 "Inactive" 1 "Active" ;
VAL_ 1144 ULoBattTransfer_D_Stat 0 "NoTransfer" 1 "TransferInProgress" 2 "InsufficientEnergyToXfer" 3 "TransferThroughGridEnergy" 4 "TransferComplete" 5 "TransferError" 6 "NotUsed_1" 7 "NotUsed_2" ;
VAL_ 1144 BattTracClntVlv_B_Rq 0 "Off" 1 "On" ;
VAL_ 1144 BattMtrTeGage_B_Dsply 0 "Off" 1 "On" ;
VAL_ 1144 AwdLckMde_D_Stat 0 "Off" 1 "SecondaryAxleSpeedCtrl" 2 "SecondaryAxleTorqueCtrl" 3 "EfficiencySplit" 4 "DualAxleSpeedControl" 5 "PrimaryAxleSpeedControl" 6 "NotUsed_1" 7 "NotUsed_2" ;
VAL_ 1144 BattTracCool_B_Actl 0 "Off" 1 "On" ;
VAL_ 1144 BattChrgInhbt_D2_Rq 0 "Enable_Charging" 1 "InhibitCharging" 2 "EndAtTarget" 3 "MaintainTargetSoc" 4 "NotUsed_1" 5 "NotUsed_2" 6 "NotUsed_3" 7 "NotUsed_4" ;
VAL_ 1145 NxtUsgSocEst_Pc_Dsply 254 "NoDataExists" 255 "Faulty" ;
VAL_ 1145 VehElRngeNut_L_Dsply 4094 "NoDataExists" 4095 "Faulty" ;
VAL_ 1145 ChargeNowDuration_St 255 "Invalid" ;
VAL_ 1145 EstmChrgTimeLP_St 255 "Invalid" ;
VAL_ 1145 EstmChrgTimeHP_St 255 "Invalid" ;
VAL_ 1145 VehElRngeNut_L2_Dsply 8190 "NoDataExists" 8191 "Faulty" ;
VAL_ 1146 TrlrAidCtl_U_RqDrv 4094 "NoDataExists" 4095 "Faulty" ;
VAL_ 1146 TrlrAidSwtch_D_RqDrv 0 "Not_Pressed" 1 "Pressed" 2 "NotUsed" 3 "Faulty" ;
